VERSION "created by canmatrix"

NS_ :

BS_:

BU_: HC IDC_L3 RRR SRR_L SRR_R GW RSDS_R CR_R FR FR_IDC_L2 IFC IDC_L2 ADAS HAP CR_L RSDS_L IDC15_IDC_L2_ADC15H_ADC30L ADC15H_ADC30L_ADC30_ADC40 Tester CEM

BO_ 395 AEB_FD1: 64 IFC
 SG_ AEB_TgtDecel_ReqValue : 87|16@0+ (0.000488,-16) [-16|16] "m/s2"  CR_L,CR_R
 SG_ AEB_TgtDecel_Req : 74|1@0+ (1,0) [0|1] ""  CR_L,CR_R

BO_ 147 TMCU6: 8 GW
 SG_ TMCU_ActPosRotSpd : 15|16@0+ (1,0) [0|65534] "rpm"  CR_L,CR_R,RSDS_L,RSDS_R

BO_ 303 HCU_FD3: 64 GW
 SG_ HCU_GearSts : 164|4@0+ (1,0) [0|15] ""  CR_L,CR_R,RSDS_L,RSDS_R

BO_ 350 CR_FD1: 64 CR_R
 SG_ Checksum_CR_R_1 : 71|8@0+ (1,0) [0|255] "" Vector__XXX
 SG_ CR_FCTA_Resp : 79|1@0+ (1,0) [0|1] ""  GW
 SG_ CR_FCTB_Resp : 78|1@0+ (1,0) [0|1] ""  GW
 SG_ CR_ErrSts : 87|1@0+ (1,0) [0|1] ""  FR,ADAS
 SG_ CR_BliSts : 86|1@0+ (1,0) [0|1] ""  GW
 SG_ FCTB_ABA_Level : 82|2@0+ (1,0) [0|3] ""  FR,ADAS
 SG_ FCTB_ABA_Req : 80|1@0+ (1,0) [0|1] ""  FR,ADAS
 SG_ FCTB_ABP_Req : 111|1@0+ (1,0) [0|1] ""  FR,ADAS
 SG_ FCTA_Warn : 75|1@0+ (1,0) [0|1] ""  GW
 SG_ FCTBTrig : 83|1@0+ (1,0) [0|1] ""  GW
 SG_ FCTA_B_FuncSts : 77|2@0+ (1,0) [0|3] ""  GW
 SG_ CR_BrkgReqVal : 95|16@0+ (0.000488,-16) [-16|16] "m/s2"  FR,ADAS
 SG_ CR_BrkgReq : 85|1@0+ (1,0) [0|1] ""  FR,ADAS
 SG_ FCTA_B_TTC : 110|6@0+ (0.1,0) [0|6.3] "s"  GW
 SG_ RollingCounter_CR_R_1 : 123|4@0+ (1,0) [0|15] "" Vector__XXX
 SG_ Checksum_CR_R_2 : 135|8@0+ (1,0) [0|255] ""  IFC
 SG_ CR_ObjSts_Le : 179|2@0+ (1,0) [0|3] ""  IFC
 SG_ CR_ObjID_Le : 157|6@0+ (1,0) [0|63] ""  IFC
 SG_ CR_ObjDistX_Le : 151|10@0+ (0.1,-10) [-10|92.3] "m"  IFC
 SG_ CR_ObjDistY_Le : 143|8@0+ (0.1,-12.8) [-12.8|12.7] "m"  IFC
 SG_ CR_ObjRelVelX_Le : 167|10@0+ (0.1,-60) [-60|42.3] "m/s"  IFC
 SG_ CR_ObjRelAccelX_Le : 173|10@0+ (0.03125,-16) [-16|15.9688] "m/s2"  IFC
 SG_ CR_ObjMotionType_Le : 191|3@0+ (1,0) [0|7] ""  IFC
 SG_ RollingCounter_CR_R_2 : 187|4@0+ (1,0) [0|15] ""  IFC
 SG_ Checksum_CR_R_3 : 199|8@0+ (1,0) [0|255] ""  IFC
 SG_ CR_ObjSts_Ri : 243|2@0+ (1,0) [0|3] ""  IFC
 SG_ CR_ObjID_Ri : 221|6@0+ (1,0) [0|63] ""  IFC
 SG_ CR_ObjDistX_Ri : 215|10@0+ (0.1,-10) [-10|92.3] "m"  IFC
 SG_ CR_ObjDistY_Ri : 207|8@0+ (0.1,-12.8) [-12.8|12.7] "m"  IFC
 SG_ CR_ObjRelVelX_Ri : 231|10@0+ (0.1,-60) [-60|42.3] "m/s"  IFC
 SG_ CR_ObjRelAccelX_Ri : 237|10@0+ (0.03125,-16) [-16|15.9688] "m/s2"  IFC
 SG_ CR_ObjMotionType_Ri : 255|3@0+ (1,0) [0|7] ""  IFC
 SG_ RollingCounter_CR_R_3 : 251|4@0+ (1,0) [0|15] ""  IFC
 SG_ Checksum_CR_R_4 : 263|8@0+ (1,0) [0|255] ""  IFC
 SG_ CR_ObjRelAccelY_Ri : 271|10@0+ (0.03125,-16) [-16|15.9688] "m/s2"  IFC
 SG_ CR_ObjRelVelY_Ri : 295|7@0+ (0.1,-6.4) [-6.4|6.3] "m/s"  IFC
 SG_ CR_ObjRelAccelY_Le : 277|10@0+ (0.03125,-16) [-16|15.9688] "m/s2"  IFC
 SG_ CR_ObjRelVelY_Le : 303|7@0+ (0.1,-6.4) [-6.4|6.3] "m/s"  IFC
 SG_ RollingCounter_CR_R_4 : 315|4@0+ (1,0) [0|15] ""  IFC
 SG_ CR_ObjDistXStd_Le : 335|5@0+ (0.375,0) [0|11.625] "m"  IFC,IDC_L2
 SG_ CR_ObjDistYStd_Le : 330|5@0+ (0.375,0) [0|11.625] "m"  IFC,IDC_L2
 SG_ CR_ObjRelVelXStd_Le : 341|5@0+ (0.375,0) [0|11.625] "mps"  IFC,IDC_L2
 SG_ CR_ObjRelVelYStd_Le : 336|5@0+ (0.375,0) [0|11.625] "mps"  IFC,IDC_L2
 SG_ CR_ObjRAccelXStd_Le : 347|5@0+ (0.375,0) [0|11.625] "mps2"  IFC,IDC_L2
 SG_ CR_ObjRAccelYStd_Le : 358|5@0+ (0.375,0) [0|11.625] "mps2"  IFC,IDC_L2
 SG_ CR_ObjDistXStd_Ri : 353|5@0+ (0.375,0) [0|11.625] "m"  IFC,IDC_L2
 SG_ CR_ObjDistYStd_Ri : 364|5@0+ (0.375,0) [0|11.625] "m"  IFC,IDC_L2
 SG_ CR_ObjRelVelXStd_Ri : 375|5@0+ (0.375,0) [0|11.625] "mps"  IFC,IDC_L2
 SG_ CR_ObjRelVelYStd_Ri : 399|5@0+ (0.375,0) [0|11.625] "mps"  IFC,IDC_L2
 SG_ CR_ObjRAccelXStd_Ri : 394|5@0+ (0.375,0) [0|11.625] "mps2"  IFC,IDC_L2
 SG_ CR_ObjRAccelYStd_Ri : 405|5@0+ (0.375,0) [0|11.625] "mps2"  IFC,IDC_L2

BO_ 846 ACC_FD5: 16 FR
 SG_ Sync_CRC : 15|8@0+ (1,0) [0|255] ""  CR_L,CR_R
 SG_ Sync_OVS : 25|2@0+ (1,0) [0|3] ""  CR_L,CR_R
 SG_ Sync_Resd : 31|5@0+ (1,0) [0|31] ""  CR_L,CR_R
 SG_ Sync_Counter : 19|4@0+ (1,0) [0|15] ""  CR_L,CR_R
 SG_ Sync_SGW : 26|1@0+ (1,0) [0|1] ""  CR_L,CR_R
 SG_ Sync_SyncTime : 39|32@0+ (1,0) [0|4294967295] ""  CR_L,CR_R
 SG_ Sync_TimeDomain : 23|4@0+ (1,0) [0|15] ""  CR_L,CR_R
 SG_ Sync_Type : 7|8@0+ (1,0) [0|255] ""  CR_L,CR_R

BO_ 323 ACC_FD1: 64 FR_IDC_L2
 SG_ ACC_CRInterface : 191|1@0+ (1,0) [0|1] ""  CR_L,CR_R

BO_ 121 ECM_FD1: 64 GW
 SG_ BrkPedalSts_0x079 : 275|2@0+ (1,0) [0|3] ""  RSDS_R,RSDS_L,CR_L,CR_R
 SG_ EngSpd_0x079 : 303|16@0+ (0.125,0) [0|8191.875] "rpm"  RSDS_R,RSDS_L,CR_L,CR_R
 SG_ EngSpdVldty_0x079 : 319|2@0+ (1,0) [0|2] ""  RSDS_R,RSDS_L,CR_L,CR_R

BO_ 259 ECM_FD2: 64 GW
 SG_ AccelPedlPosnDiagc_0x103 : 103|8@0+ (0.3937,0) [0|100.3935] "%"  RSDS_R,RSDS_L,CR_L,CR_R
 SG_ AccelPedalPosnVldty_0x103 : 242|2@0+ (1,0) [0|2] ""  RSDS_R,RSDS_L,CR_L,CR_R
 SG_ EngState_0x103 : 254|2@0+ (1,0) [0|3] ""  RSDS_R,RSDS_L,CR_L,CR_R
 SG_ EngState_PHEV_0x103 : 351|3@0+ (1,0) [0|7] ""  RSDS_R,RSDS_L,CR_L,CR_R

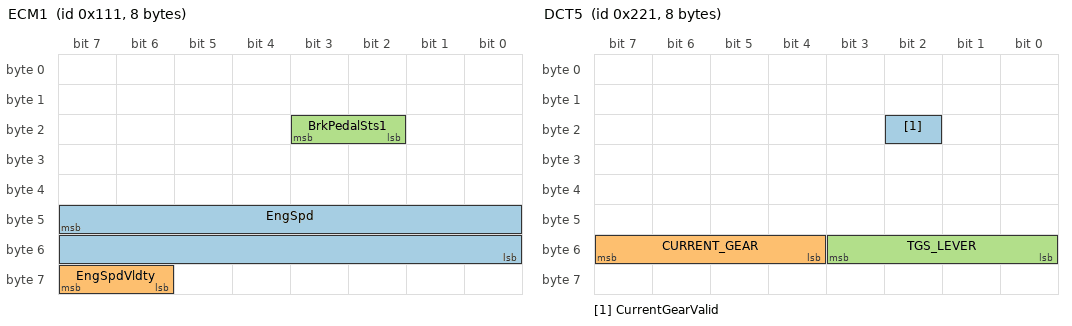
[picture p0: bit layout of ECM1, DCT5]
BO_ 273 ECM1: 8 GW
 SG_ EngSpd : 47|16@0+ (0.125,0) [0|8191.875] "rpm"  RSDS_R,RSDS_L,CR_L,CR_R
 SG_ EngSpdVldty : 63|2@0+ (1,0) [0|2] ""  RSDS_R,RSDS_L,CR_L,CR_R
 SG_ BrkPedalSts1 : 19|2@0+ (1,0) [0|3] ""  RSDS_R,RSDS_L,CR_L,CR_R

BO_ 545 DCT5: 8 GW
 SG_ CurrentGearValid : 18|1@0+ (1,0) [0|1] ""  RSDS_R,RSDS_L,CR_L,CR_R
 SG_ CURRENT_GEAR : 55|4@0+ (1,0) [0|15] ""  RSDS_R,RSDS_L,CR_L,CR_R
 SG_ TGS_LEVER : 51|4@0+ (1,0) [0|15] ""  RSDS_R,RSDS_L,CR_L,CR_R

BO_ 311 ESP_FD2: 64 GW
 SG_ ESP_DiagActv_0x137 : 73|1@0+ (1,0) [0|1] ""  RSDS_R,RSDS_L,CR_L,CR_R
 SG_ BrkDskOvrheatd_0x137 : 75|1@0+ (1,0) [0|1] ""  CR_L,CR_R
 SG_ NoBrkForce_0x137 : 76|1@0+ (1,0) [0|1] ""  RSDS_R,RSDS_L,CR_L,CR_R
 SG_ VehStandstill_0x137 : 78|2@0+ (1,0) [0|3] ""  RSDS_R,RSDS_L,CR_L,CR_R
 SG_ AEBIBActv_0x137 : 81|1@0+ (1,0) [0|1] ""  RSDS_R,RSDS_L,CR_L,CR_R
 SG_ AEBBAActv_0x137 : 82|1@0+ (1,0) [0|1] ""  RSDS_R,RSDS_L,CR_L,CR_R
 SG_ AEBAvailable_0x137 : 83|1@0+ (1,0) [0|1] ""  CR_L,CR_R
 SG_ ABPAvailable_0x137 : 84|1@0+ (1,0) [0|1] ""  CR_L,CR_R
 SG_ ABPActv_0x137 : 85|1@0+ (1,0) [0|1] ""  CR_L,CR_R
 SG_ ABAavailable_0x137 : 86|1@0+ (1,0) [0|1] ""  CR_L,CR_R
 SG_ ABAactv_0x137 : 87|1@0+ (1,0) [0|1] ""  CR_L,CR_R
 SG_ HDCCtrl_0x137 : 91|2@0+ (1,0) [0|2] ""  RSDS_R,RSDS_L,CR_L,CR_R
 SG_ CTABrkAvailable_0x137 : 74|1@0+ (1,0) [0|1] ""  RSDS_R,RSDS_L
 SG_ CheckSum_ESP1_0x137 : 135|8@0+ (1,0) [0|255] ""  RSDS_R,RSDS_L,CR_L,CR_R
 SG_ ESPFuncOffSts_0x137 : 140|1@0+ (1,0) [0|1] ""  RSDS_R,RSDS_L,CR_L,CR_R
 SG_ ESPFailSts_0x137 : 143|1@0+ (1,0) [0|1] ""  RSDS_R,RSDS_L,CR_L,CR_R
 SG_ ESP_MasterCylBrkPressVld_0x137 : 144|1@0+ (1,0) [0|1] ""  RSDS_R,RSDS_L,CR_L,CR_R
 SG_ MSRActv_0x137 : 149|1@0+ (1,0) [0|1] ""  RSDS_R,RSDS_L,CR_L,CR_R
 SG_ VDCActv_0x137 : 148|1@0+ (1,0) [0|1] ""  RSDS_R,RSDS_L,CR_L,CR_R
 SG_ PTCActv_0x137 : 150|1@0+ (1,0) [0|1] ""  RSDS_R,RSDS_L,CR_L,CR_R
 SG_ BTCActv_0x137 : 151|1@0+ (1,0) [0|1] ""  RSDS_R,RSDS_L,CR_L,CR_R
 SG_ ESP_MasterCylBrkPress_0x137 : 159|16@0+ (0.03125,-42.5) [-42.5|425] "bar"  RSDS_R,RSDS_L,CR_L,CR_R
 SG_ MSRActv_RA_0x137 : 174|1@0+ (1,0) [0|1] ""  RSDS_R,RSDS_L,CR_L,CR_R
 SG_ PTCActv_RA_0x137 : 136|1@0+ (1,0) [0|1] ""  RSDS_R,RSDS_L,CR_L,CR_R
 SG_ BTCActv_RA_0x137 : 137|1@0+ (1,0) [0|1] ""  RSDS_R,RSDS_L,CR_L,CR_R
 SG_ RollingCounter_ESP1_0x137 : 187|4@0+ (1,0) [0|15] ""  RSDS_R,RSDS_L,CR_L,CR_R
 SG_ CheckSum_ABS3_0x137 : 327|8@0+ (1,0) [0|255] ""  RSDS_R,RSDS_L,CR_L,CR_R
 SG_ VehSpdVld_0x137 : 333|1@0+ (1,0) [0|1] ""  RSDS_R,RSDS_L,CR_L,CR_R
 SG_ VehSpd_0x137 : 332|13@0+ (0.05625,0) [0|299.98125] "kph"  RSDS_R,RSDS_L,CR_L,CR_R
 SG_ ABSActv_0x137 : 347|1@0+ (1,0) [0|1] ""  RSDS_R,RSDS_L,CR_L,CR_R
 SG_ RollingCounter_ABS3_0x137 : 379|4@0+ (1,0) [0|15] ""  RSDS_R,RSDS_L,CR_L,CR_R

BO_ 315 ESP_FD3: 64 GW
 SG_ CheckSum_ABS1_0x13B : 7|8@0+ (1,0) [0|255] ""  RSDS_R,RSDS_L,CR_L,CR_R
 SG_ FLWheelDriveDirection_0x13B : 15|2@0+ (1,0) [0|3] ""  RSDS_R,RSDS_L,CR_L,CR_R
 SG_ FLWheelSpdVld_0x13B : 13|1@0+ (1,0) [0|1] ""  RSDS_R,RSDS_L,CR_L,CR_R
 SG_ FLWheelSpd_0x13B : 12|13@0+ (0.05625,0) [0|299.98125] "km/h"  RSDS_R,RSDS_L,CR_L,CR_R
 SG_ FRWheelDriveDirection_0x13B : 31|2@0+ (1,0) [0|3] ""  RSDS_R,RSDS_L,CR_L,CR_R
 SG_ FRWheelSpdVld_0x13B : 29|1@0+ (1,0) [0|1] ""  RSDS_R,RSDS_L,CR_L,CR_R
 SG_ FRWheelSpd_0x13B : 28|13@0+ (0.05625,0) [0|299.98125] "km/h"  RSDS_R,RSDS_L,CR_L,CR_R
 SG_ RollingCounter_ABS1_0x13B : 59|4@0+ (1,0) [0|15] ""  RSDS_R,RSDS_L,CR_L,CR_R
 SG_ EPBErrSts_0x13B : 91|2@0+ (1,0) [0|3] ""  RSDS_R,RSDS_L,CR_L,CR_R
 SG_ EPBSts_0x13B : 93|2@0+ (1,0) [0|3] ""  RSDS_R,RSDS_L,CR_L,CR_R
 SG_ CheckSum_ABS2_0x13B : 327|8@0+ (1,0) [0|255] ""  RSDS_R,RSDS_L,CR_L,CR_R
 SG_ RLWheelDriveDirection_0x13B : 335|2@0+ (1,0) [0|3] ""  RSDS_R,RSDS_L,CR_L,CR_R
 SG_ RLWheelSpdVld_0x13B : 333|1@0+ (1,0) [0|1] ""  RSDS_R,RSDS_L,CR_L,CR_R
 SG_ RLWheelSpd_0x13B : 332|13@0+ (0.05625,0) [0|299.98125] "km/h"  RSDS_R,RSDS_L,CR_L,CR_R
 SG_ RRWheelDriveDirection_0x13B : 351|2@0+ (1,0) [0|3] ""  RSDS_R,RSDS_L,CR_L,CR_R
 SG_ RRWheelSpdVld_0x13B : 349|1@0+ (1,0) [0|1] ""  RSDS_R,RSDS_L,CR_L,CR_R
 SG_ RRWheelSpd_0x13B : 348|13@0+ (0.05625,0) [0|299.98125] "km/h"  RSDS_R,RSDS_L,CR_L,CR_R
 SG_ RollingCounter_ABS2_0x13B : 379|4@0+ (1,0) [0|15] ""  RSDS_R,RSDS_L,CR_L,CR_R

BO_ 793 BCM1: 16 GW
 SG_ DrvDoorSts : 22|1@0+ (1,0) [0|1] ""  RSDS_R,RSDS_L,CR_L,CR_R
 SG_ LRDoorSts : 21|1@0+ (1,0) [0|1] ""  RSDS_R,RSDS_L
 SG_ PassengerDoorSts : 20|1@0+ (1,0) [0|1] ""  RSDS_R,RSDS_L
 SG_ RRDoorSts : 19|1@0+ (1,0) [0|1] ""  RSDS_R,RSDS_L

BO_ 671 BCM8: 8 GW
 SG_ RSDS_LLEDSts : 47|1@0+ (1,0) [0|1] ""  RSDS_R,RSDS_L
 SG_ RSDS_RLEDSts : 46|1@0+ (1,0) [0|1] ""  RSDS_R,RSDS_L

BO_ 661 PEPS2: 8 GW
 SG_ SysPowerMod : 15|2@0+ (1,0) [0|3] ""  RSDS_R,RSDS_L,CR_L,CR_R
 SG_ SysPowerModVld : 13|1@0+ (1,0) [0|1] ""  RSDS_R,RSDS_L,CR_L,CR_R

BO_ 627 Trailer1: 8 GW
 SG_ TrailerSts : 7|1@0+ (1,0) [0|1] ""  RSDS_R,RSDS_L

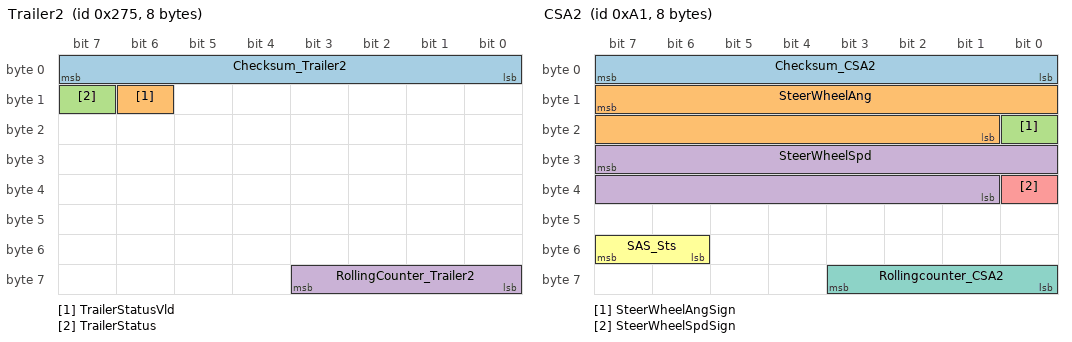
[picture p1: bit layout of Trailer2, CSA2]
BO_ 629 Trailer2: 8 GW
 SG_ Checksum_Trailer2 : 7|8@0+ (1,0) [0|255] "NoUnit"  RSDS_R,RSDS_L
 SG_ TrailerStatusVld : 14|1@0+ (1,0) [0|1] "NoUnit"  RSDS_R,RSDS_L
 SG_ TrailerStatus : 15|1@0+ (1,0) [0|1] "NoUnit"  RSDS_R,RSDS_L
 SG_ RollingCounter_Trailer2 : 59|4@0+ (1,0) [0|15] "NoUnit"  RSDS_R,RSDS_L

BO_ 357 CSA1: 8 GW
 SG_ LTurnLmpSwtSts : 19|1@0+ (1,0) [0|1] ""  RSDS_R,RSDS_L,CR_L,CR_R
 SG_ RTurnLmpSwtSts : 20|1@0+ (1,0) [0|1] ""  RSDS_R,RSDS_L,CR_L,CR_R

BO_ 161 CSA2: 8 GW
 SG_ Checksum_CSA2 : 7|8@0+ (1,0) [0|255] ""  RSDS_R,RSDS_L
 SG_ SteerWheelAng : 15|15@0+ (0.1,0) [0|780] "deg"  RSDS_R,RSDS_L,CR_L,CR_R
 SG_ SteerWheelAngSign : 16|1@0+ (1,0) [0|1] ""  RSDS_R,RSDS_L,CR_L,CR_R
 SG_ SteerWheelSpd : 31|15@0+ (0.1,0) [0|1016] "deg/s"  RSDS_R,RSDS_L,CR_L,CR_R
 SG_ SteerWheelSpdSign : 32|1@0+ (1,0) [0|1] ""  RSDS_R,RSDS_L,CR_L,CR_R
 SG_ SAS_Sts : 55|2@0+ (1,0) [0|3] ""  RSDS_R,RSDS_L,CR_L,CR_R
 SG_ Rollingcounter_CSA2 : 59|4@0+ (1,0) [0|15] ""  RSDS_R,RSDS_L

BO_ 714 DDCM1: 8 GW
 SG_ RSDS_Driver_LED_Sts : 9|1@0+ (1,0) [0|1] ""  RSDS_R,RSDS_L

BO_ 717 PDCM1: 8 GW
 SG_ RSDS_Pass_LED_Sts : 8|1@0+ (1,0) [0|1] ""  RSDS_R,RSDS_L

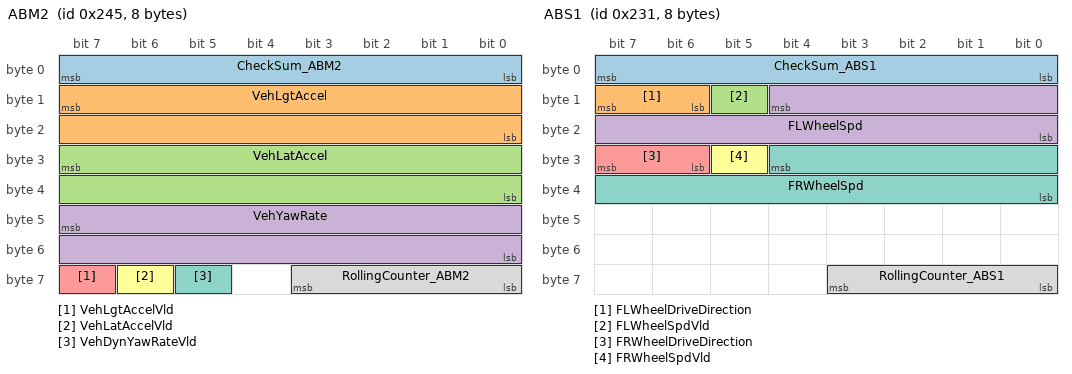
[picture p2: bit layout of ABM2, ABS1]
BO_ 581 ABM2: 8 GW
 SG_ CheckSum_ABM2 : 7|8@0+ (1,0) [0|255] ""  RSDS_R,RSDS_L,CR_L,CR_R
 SG_ VehLgtAccel : 15|16@0+ (0.00098,-21.592) [-21.592|21.592] "m/s^2"  RSDS_R,RSDS_L,CR_L,CR_R
 SG_ VehLatAccel : 31|16@0+ (0.00098,-21.592) [-21.592|21.592] "m/s^2"  RSDS_R,RSDS_L,CR_L,CR_R
 SG_ VehYawRate : 47|16@0+ (0.00024,-2.093) [-2.093|2.093] "rad/s"  RSDS_R,RSDS_L,CR_L,CR_R
 SG_ VehLgtAccelVld : 63|1@0+ (1,0) [0|1] ""  RSDS_R,RSDS_L,CR_L,CR_R
 SG_ VehLatAccelVld : 62|1@0+ (1,0) [0|1] ""  RSDS_R,RSDS_L,CR_L,CR_R
 SG_ VehDynYawRateVld : 61|1@0+ (1,0) [0|1] ""  RSDS_R,RSDS_L,CR_L,CR_R
 SG_ RollingCounter_ABM2 : 59|4@0+ (1,0) [0|15] ""  RSDS_R,RSDS_L,CR_L,CR_R

BO_ 639 IP2: 16 GW
 SG_ IP_VehTotDistance : 15|24@0+ (0.1,0) [0|999999.9] "Km"  RSDS_R,RSDS_L,CR_L,CR_R
 SG_ IP_VehTotDistanceValid : 46|1@0+ (1,0) [0|1] ""  RSDS_R,RSDS_L,CR_L,CR_R

BO_ 707 HUT_FD1: 64 GW
 SG_ DOWSwtReq : 104|1@0+ (1,0) [0|1] ""  RSDS_R,RSDS_L
 SG_ LCASwtReq : 85|1@0+ (1,0) [0|1] ""  RSDS_R,RSDS_L
 SG_ RCTASwtReq : 84|1@0+ (1,0) [0|1] ""  RSDS_R,RSDS_L
 SG_ RCTABrkSwtReq : 83|1@0+ (1,0) [0|1] ""  RSDS_R,RSDS_L
 SG_ RCWSwtReq : 82|1@0+ (1,0) [0|1] ""  RSDS_R,RSDS_L
 SG_ FCW_SnvtySet : 81|2@0+ (1,0) [0|3] ""  CR_L,CR_R
 SG_ FCTASwtReq : 301|1@0+ (1,0) [0|1] ""  CR_L,CR_R
 SG_ FCTABrkSwtReq : 300|1@0+ (1,0) [0|1] ""  CR_L,CR_R

BO_ 258 ECM9: 8 GW
 SG_ AccelPedlPosnDiagc : 39|8@0+ (0.3937,0) [0|100.3935] "%"  RSDS_R,RSDS_L,CR_L,CR_R

BO_ 625 ECM2: 8 GW
 SG_ AccelPedalPosnVldty : 50|2@0+ (1,0) [0|2] ""  RSDS_R,RSDS_L,CR_L,CR_R
 SG_ EngState : 62|2@0+ (1,0) [0|3] ""  RSDS_R,RSDS_L,CR_L,CR_R

BO_ 561 ABS1: 8 GW
 SG_ CheckSum_ABS1 : 7|8@0+ (1,0) [0|255] ""  RSDS_R,RSDS_L,CR_L,CR_R
 SG_ FLWheelDriveDirection : 15|2@0+ (1,0) [0|3] ""  RSDS_R,RSDS_L,CR_L,CR_R
 SG_ FLWheelSpdVld : 13|1@0+ (1,0) [0|1] ""  RSDS_R,RSDS_L,CR_L,CR_R
 SG_ FLWheelSpd : 12|13@0+ (0.05625,0) [0|299.98125] "km/h"  RSDS_R,RSDS_L,CR_L,CR_R
 SG_ FRWheelDriveDirection : 31|2@0+ (1,0) [0|3] ""  RSDS_R,RSDS_L,CR_L,CR_R
 SG_ FRWheelSpdVld : 29|1@0+ (1,0) [0|1] ""  RSDS_R,RSDS_L,CR_L,CR_R
 SG_ FRWheelSpd : 28|13@0+ (0.05625,0) [0|299.98125] "km/h"  RSDS_R,RSDS_L,CR_L,CR_R
 SG_ RollingCounter_ABS1 : 59|4@0+ (1,0) [0|15] ""  RSDS_R,RSDS_L,CR_L,CR_R

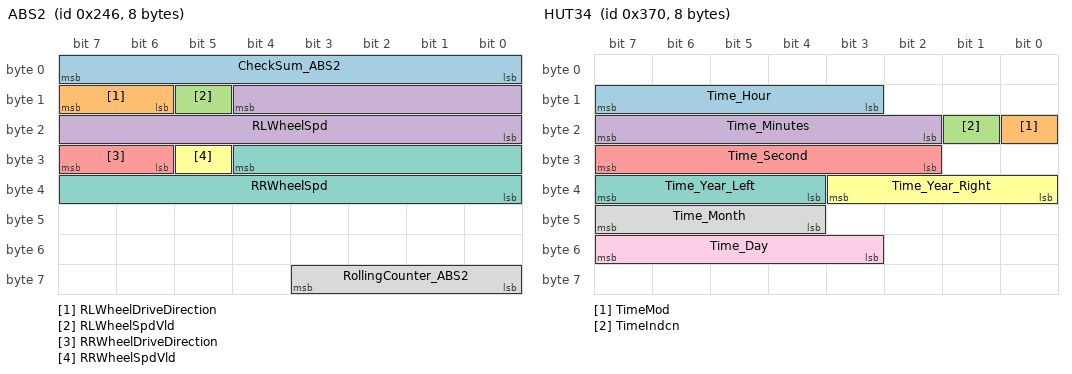
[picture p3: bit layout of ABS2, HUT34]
BO_ 582 ABS2: 8 GW
 SG_ CheckSum_ABS2 : 7|8@0+ (1,0) [0|255] ""  RSDS_R,RSDS_L,CR_L,CR_R
 SG_ RLWheelDriveDirection : 15|2@0+ (1,0) [0|3] ""  RSDS_R,RSDS_L,CR_L,CR_R
 SG_ RLWheelSpdVld : 13|1@0+ (1,0) [0|1] ""  RSDS_R,RSDS_L,CR_L,CR_R
 SG_ RLWheelSpd : 12|13@0+ (0.05625,0) [0|299.98125] "km/h"  RSDS_R,RSDS_L,CR_L,CR_R
 SG_ RRWheelDriveDirection : 31|2@0+ (1,0) [0|3] ""  RSDS_R,RSDS_L,CR_L,CR_R
 SG_ RRWheelSpdVld : 29|1@0+ (1,0) [0|1] ""  RSDS_R,RSDS_L,CR_L,CR_R
 SG_ RRWheelSpd : 28|13@0+ (0.05625,0) [0|299.98125] "km/h"  RSDS_R,RSDS_L,CR_L,CR_R
 SG_ RollingCounter_ABS2 : 59|4@0+ (1,0) [0|15] ""  RSDS_R,RSDS_L,CR_L,CR_R

BO_ 613 ABS3: 16 GW
 SG_ CheckSum_ABS3 : 7|8@0+ (1,0) [0|255] ""  RSDS_R,RSDS_L,CR_L,CR_R
 SG_ VehSpdVld : 13|1@0+ (1,0) [0|1] ""  RSDS_R,RSDS_L,CR_L,CR_R
 SG_ VehSpd : 12|13@0+ (0.05625,0) [0|299.98125] "kph"  RSDS_R,RSDS_L,CR_L,CR_R
 SG_ ABSActv : 27|1@0+ (1,0) [0|1] ""  RSDS_R,RSDS_L,CR_L,CR_R
 SG_ RollingCounter_ABS3 : 59|4@0+ (1,0) [0|15] ""  RSDS_R,RSDS_L,CR_L,CR_R

BO_ 363 EPB1: 8 GW
 SG_ EPBErrSts : 27|2@0+ (1,0) [0|3] ""  RSDS_R,RSDS_L,CR_L,CR_R
 SG_ EPBSts : 29|2@0+ (1,0) [0|3] ""  RSDS_R,RSDS_L,CR_L,CR_R

BO_ 329 ESP1: 16 GW
 SG_ CheckSum_ESP1 : 7|8@0+ (1,0) [0|255] ""  RSDS_R,RSDS_L,CR_L,CR_R
 SG_ ESPFuncOffSts : 12|1@0+ (1,0) [0|1] ""  RSDS_R,RSDS_L,CR_L,CR_R
 SG_ ESPFailSts : 15|1@0+ (1,0) [0|1] ""  RSDS_R,RSDS_L,CR_L,CR_R
 SG_ ESP_MasterCylBrkPressVld : 16|1@0+ (1,0) [0|1] ""  RSDS_R,RSDS_L,CR_L,CR_R
 SG_ MSRActv : 21|1@0+ (1,0) [0|1] ""  RSDS_R,RSDS_L,CR_L,CR_R
 SG_ VDCActv : 20|1@0+ (1,0) [0|1] ""  RSDS_R,RSDS_L,CR_L,CR_R
 SG_ PTCActv : 22|1@0+ (1,0) [0|1] ""  RSDS_R,RSDS_L,CR_L,CR_R
 SG_ BTCActv : 23|1@0+ (1,0) [0|1] ""  RSDS_R,RSDS_L,CR_L,CR_R
 SG_ ESP_MasterCylBrkPress : 31|16@0+ (0.03125,-42.5) [-42.5|425] "bar"  RSDS_R,RSDS_L,CR_L,CR_R
 SG_ RollingCounter_ESP1 : 59|4@0+ (1,0) [0|15] ""  RSDS_R,RSDS_L,CR_L,CR_R

BO_ 325 ESP2: 16 GW
 SG_ ESP_DiagActv : 9|1@0+ (1,0) [0|1] ""  RSDS_R,RSDS_L,CR_L,CR_R
 SG_ NoBrkForce : 12|1@0+ (1,0) [0|1] ""  RSDS_R,RSDS_L,CR_L,CR_R
 SG_ VehStandstill : 14|2@0+ (1,0) [0|3] ""  RSDS_R,RSDS_L,CR_L,CR_R
 SG_ AEBIBActv : 17|1@0+ (1,0) [0|1] ""  RSDS_R,RSDS_L,CR_L,CR_R
 SG_ AEBBAActv : 18|1@0+ (1,0) [0|1] ""  RSDS_R,RSDS_L,CR_L,CR_R
 SG_ HDCCtrl : 27|2@0+ (1,0) [0|2] ""  RSDS_R,RSDS_L,CR_L,CR_R
 SG_ CTABrkAvailable : 10|1@0+ (1,0) [0|1] ""  RSDS_R,RSDS_L
 SG_ BrkDskOvrheatd : 11|1@0+ (1,0) [0|1] ""  CR_L,CR_R
 SG_ AEBAvailable : 19|1@0+ (1,0) [0|1] ""  CR_L,CR_R
 SG_ ABPAvailable : 20|1@0+ (1,0) [0|1] ""  CR_L,CR_R
 SG_ ABPActv : 21|1@0+ (1,0) [0|1] ""  CR_L,CR_R
 SG_ ABAavailable : 22|1@0+ (1,0) [0|1] ""  CR_L,CR_R
 SG_ ABAactv : 23|1@0+ (1,0) [0|1] ""  CR_L,CR_R

BO_ 96 HCU_FD1: 64 GW
 SG_ HCU_BrkPedalSts : 87|2@0+ (1,0) [0|3] ""  RSDS_R,RSDS_L,CR_L,CR_R
 SG_ HCU_BrkPedalStsValid : 84|1@0+ (1,0) [0|1] ""  RSDS_R,RSDS_L,CR_L,CR_R
 SG_ HCU_AccelPedalPosn_Diag : 79|8@0+ (0.3937,0) [0|100.395] "%"  RSDS_R,RSDS_L,CR_L,CR_R
 SG_ HCU_AccelPedalPosn_DiagValid : 85|1@0+ (1,0) [0|1] ""  RSDS_R,RSDS_L,CR_L,CR_R
 SG_ HCU_PowertrainSts : 303|5@0+ (1,0) [0|31] ""  RSDS_R,RSDS_L,CR_L,CR_R

BO_ 288 Ibooster_FD2: 64 GW
 SG_ IB_BrkPedalAppld : 11|1@0+ (1,0) [0|1] ""  RSDS_R,RSDS_L,CR_L,CR_R
 SG_ IB_BrkPedalAppldVld : 10|2@0+ (1,0) [0|3] ""  RSDS_R,RSDS_L,CR_L,CR_R

BO_ 174 MCU_FD1: 64 GW
 SG_ MCU_ActRotSpd : 167|16@0+ (1,-20000) [-20000|45534] "rpm"  RSDS_R,RSDS_L,CR_L,CR_R

BO_ 537 VCU_FD3: 64 GW
 SG_ VCU_GearSts : 87|4@0+ (1,0) [0|15] ""  RSDS_R,RSDS_L,CR_L,CR_R
 SG_ VCU_GearStsVld : 94|1@0+ (1,0) [0|1] ""  RSDS_R,RSDS_L,CR_L,CR_R

BO_ 1305 HC_NM: 8 HC
 SG_ Destination_HC_NM : 7|8@0+ (1,0) [0|63] ""  GW,IDC_L3
 SG_ OpCode_HC_NM : 15|8@0+ (1,0) [0|63] ""  GW,IDC_L3

BO_ 1308 IDC_L3_NM: 8 IDC_L3
 SG_ Destination_IDC_L3_NM : 7|8@0+ (1,0) [0|63] ""  GW,HC,RRR,SRR_L,SRR_R
 SG_ OpCode_IDC_L3_NM : 15|8@0+ (1,0) [0|63] ""  GW,HC,RRR,SRR_L,SRR_R

BO_ 1309 RRR_NM: 8 RRR
 SG_ Destination_RRR_NM : 7|8@0+ (1,0) [0|63] ""  IDC_L3
 SG_ OpCode_RRR_NM : 15|8@0+ (1,0) [0|63] ""  IDC_L3

BO_ 1310 SRR_L_NM: 8 SRR_L
 SG_ Destination_SRR_L_NM : 7|8@0+ (1,0) [0|63] ""  IDC_L3,SRR_R
 SG_ OpCode_SRR_L_NM : 15|8@0+ (1,0) [0|63] ""  IDC_L3,SRR_R

BO_ 1311 SRR_R_NM: 8 SRR_R
 SG_ Destination_SRR_R_NM : 7|8@0+ (1,0) [0|63] ""  IDC_L3,SRR_L
 SG_ OpCode_SRR_R_NM : 15|8@0+ (1,0) [0|63] ""  IDC_L3,SRR_L

BO_ 1281 GW_NM: 8 GW
 SG_ Destination_GW_NM : 7|8@0+ (1,0) [0|63] ""  HC,IDC_L3
 SG_ OpCode_GW_NM : 15|8@0+ (1,0) [0|63] ""  HC,IDC_L3

BO_ 301 EBOOSTER_FD1: 64 GW
 SG_ EB_AEBIBActv : 13|1@0+ (1,0) [0|1] ""  CR_L,CR_R,RSDS_R,RSDS_L
 SG_ EB_AEBBAActv : 12|1@0+ (1,0) [0|1] ""  CR_L,CR_R,RSDS_R,RSDS_L
 SG_ EB_AEBAvailable : 11|1@0+ (1,0) [0|1] ""  CR_L,CR_R,RSDS_R,RSDS_L
 SG_ EB_ABPAvailable : 10|1@0+ (1,0) [0|1] ""  CR_L,CR_R
 SG_ EB_ABPActv : 9|1@0+ (1,0) [0|1] ""  CR_L,CR_R
 SG_ EB_CTABrkAvailable : 17|1@0+ (1,0) [0|1] ""  RSDS_R,RSDS_L

BO_ 1136 ADAS_AD1: 16 GW
 SG_ Sync_CRC_0x470 : 15|8@0+ (1,0) [0|255] ""  FR,CR_L,CR_R,RSDS_R,RSDS_L
 SG_ Sync_OVS_0x470 : 25|2@0+ (1,0) [0|3] ""  FR,CR_L,CR_R,RSDS_R,RSDS_L
 SG_ Sync_Resd_0x470 : 31|5@0+ (1,0) [0|31] ""  FR,CR_L,CR_R,RSDS_R,RSDS_L
 SG_ Sync_Counter_0x470 : 19|4@0+ (1,0) [0|15] ""  FR,CR_L,CR_R,RSDS_R,RSDS_L
 SG_ Sync_SGW_0x470 : 26|1@0+ (1,0) [0|1] ""  FR,CR_L,CR_R,RSDS_R,RSDS_L
 SG_ Sync_SyncTime_0x470 : 39|32@0+ (1,0) [0|4294967295] ""  FR,CR_L,CR_R,RSDS_R,RSDS_L
 SG_ Sync_TimeDomain_0x470 : 23|4@0+ (1,0) [0|15] ""  FR,CR_L,CR_R,RSDS_R,RSDS_L
 SG_ Sync_Type_0x470 : 7|8@0+ (1,0) [0|255] ""  FR,CR_L,CR_R,RSDS_R,RSDS_L

BO_ 778 RSDS_FD2: 64 RSDS_R
 SG_ RCTA_B_TTC : 15|6@0+ (0.1,0) [0|6.3] "s" Vector__XXX
 SG_ BSD_LCA_Left_TTC : 9|6@0+ (0.1,0) [0|6.3] "s" Vector__XXX
 SG_ RCW_TTC : 29|6@0+ (0.1,0) [0|6.3] "s" Vector__XXX
 SG_ BSD_LCA_Right_TTC : 19|6@0+ (0.1,0) [0|6.3] "s" Vector__XXX
 SG_ RSDS_LeTgt_01_dy : 78|7@0+ (0.1,0) [0|8] "m" Vector__XXX
 SG_ RSDS_LeTgt_01 : 79|1@0+ (1,0) [0|1] "NoUnit" Vector__XXX
 SG_ RSDS_LeTgt_02 : 93|1@0+ (1,0) [0|1] "NoUnit" Vector__XXX
 SG_ RSDS_LeTgt_01_dx : 87|10@0+ (0.1,-90) [-90|5] "m" Vector__XXX
 SG_ RSDS_LeTgt_02_dx : 92|10@0+ (0.1,-90) [-90|5] "m" Vector__XXX
 SG_ RSDS_RiTgt_01 : 107|1@0+ (1,0) [0|1] "NoUnit" Vector__XXX
 SG_ RSDS_LeTgt_02_dy : 98|7@0+ (0.1,0) [0|8] "m" Vector__XXX
 SG_ RSDS_RiTgt_01_dx : 106|10@0+ (0.1,-90) [-90|5] "m" Vector__XXX
 SG_ RSDS_RiTgt_02 : 136|1@0+ (1,0) [0|1] "NoUnit" Vector__XXX
 SG_ RSDS_RiTgt_01_dy : 143|7@0+ (0.1,-8) [-8|0] "m" Vector__XXX
 SG_ RSDS_RiTgt_02_dx : 151|10@0+ (0.1,-90) [-90|5] "m" Vector__XXX
 SG_ RSDS_MidTgt_01 : 166|1@0+ (1,0) [0|1] "NoUnit" Vector__XXX
 SG_ RSDS_RiTgt_02_dy : 157|7@0+ (0.1,-8) [-8|0] "m" Vector__XXX
 SG_ RSDS_MidTgt_01_dx : 165|10@0+ (0.1,-90) [-90|5] "m" Vector__XXX
 SG_ RSDS_MidTgt_02 : 180|1@0+ (1,0) [0|1] "NoUnit" Vector__XXX
 SG_ RSDS_MidTgt_01_dy : 171|7@0+ (0.1,-4) [-4|4] "m" Vector__XXX
 SG_ RSDS_MidTgt_02_dx : 207|10@0+ (0.1,-90) [-90|5] "m" Vector__XXX
 SG_ RSDS_MidTgt_02_dy : 213|7@0+ (0.1,-4) [-4|4] "m" Vector__XXX
 SG_ LCA_LeTgt_01_Type : 126|3@0+ (1,0) [0|7] "NoUnit" Vector__XXX
 SG_ RCTA_LeTgt_02_Type : 179|3@0+ (1,0) [0|7] "NoUnit" Vector__XXX
 SG_ LCA_RiTgt_01_Type : 190|3@0+ (1,0) [0|7] "NoUnit" Vector__XXX
 SG_ RCTA_RiTgt_02_Type : 222|3@0+ (1,0) [0|7] "NoUnit" Vector__XXX
 SG_ RCW_MidTgt_01_Type : 219|3@0+ (1,0) [0|7] "NoUnit" Vector__XXX
 SG_ RCTB_MidTgt_02_Type : 292|3@0+ (1,0) [0|7] "NoUnit" Vector__XXX
 SG_ LCA_LeTgt_01_Vx : 216|9@0+ (0.5,-127.5) [-127|128] "kph" Vector__XXX
 SG_ RCTA_LeTgt_02_Vx : 239|9@0+ (0.5,-127.5) [-127|128] "kph" Vector__XXX
 SG_ LCA_RiTgt_01_Vx : 246|9@0+ (0.5,-127.5) [-127|128] "kph" Vector__XXX
 SG_ RCTA_RiTgt_02_Vx : 271|9@0+ (0.5,-127.5) [-127|128] "kph" Vector__XXX
 SG_ RCW_MidTgt_01_Vx : 278|9@0+ (0.5,-127.5) [-127|128] "kph" Vector__XXX
 SG_ RCTB_MidTgt_02_Vx : 285|9@0+ (0.5,-127.5) [-127|128] "kph" Vector__XXX
 SG_ LCA_LeTgt_01_Vy : 289|9@0+ (0.5,-127.5) [-127|128] "kph" Vector__XXX
 SG_ RCTA_LeTgt_02_Vy : 296|9@0+ (0.5,-127.5) [-127|128] "kph" Vector__XXX
 SG_ LCA_RiTgt_01_Vy : 335|9@0+ (0.5,-127.5) [-127|128] "kph" Vector__XXX
 SG_ RCTA_RiTgt_02_Vy : 342|9@0+ (0.5,-127.5) [-127|128] "kph" Vector__XXX
 SG_ RCW_MidTgt_01_Vy : 349|9@0+ (0.5,-127.5) [-127|128] "kph" Vector__XXX
 SG_ RCTB_MidTgt_02_Vy : 356|9@0+ (0.5,-127.5) [-127|128] "kph" Vector__XXX

BO_ 367 RSDS_FD1: 64 RSDS_R
 SG_ RSDS_ObjRelAccelY_Le : 15|10@0+ (0.03125,-16) [-16|15.9688] "MtrPerSecSq"  GW
 SG_ Checksum_RSDS_R_2 : 71|8@0+ (1,0) [0|255] "NoUnit"  GW
 SG_ RSDS_BrkgReq : 78|1@0+ (1,0) [0|1] "NoUnit"  GW
 SG_ RSDS_Brk_ErrSts : 79|1@0+ (1,0) [0|1] "NoUnit"  GW
 SG_ RSDS_IPSoundReq : 81|2@0+ (1,0) [0|3] "NoUnit"  GW
 SG_ RSDS_LEDLightReqRight : 83|2@0+ (1,0) [0|3] "NoUnit" Vector__XXX
 SG_ RSDS_LEDLightReqLeft : 85|2@0+ (1,0) [0|3] "NoUnit" Vector__XXX
 SG_ RSDS_BrkgReqVal : 77|8@0+ (0.05,-10) [-10|2.75] "MtrPerSecSq"  GW
 SG_ DOW_warningReqleft : 89|2@0+ (1,0) [0|3] "NoUnit"  GW
 SG_ DOW_warningReqRight : 91|2@0+ (1,0) [0|3] "NoUnit"  GW
 SG_ BSD_LCA_warningReqleft : 93|2@0+ (1,0) [0|3] "NoUnit"  GW
 SG_ BSD_LCA_warningReqRight : 95|2@0+ (1,0) [0|3] "NoUnit"  GW
 SG_ RSDS_RCW_Trigger : 105|2@0+ (1,0) [0|3] "NoUnit"  GW
 SG_ RSDS_RCTAResp : 112|1@0+ (1,0) [0|1] "NoUnit"  GW
 SG_ RSDS_RCWResp : 113|1@0+ (1,0) [0|1] "NoUnit"  GW
 SG_ RSDS_DOWResp : 114|1@0+ (1,0) [0|1] "NoUnit"  GW
 SG_ RSDS_LCAResp : 115|1@0+ (1,0) [0|1] "NoUnit"  GW
 SG_ RSDS_TrailerSts : 116|1@0+ (1,0) [0|1] "NoUnit"  GW
 SG_ RSDS_BliSts : 117|1@0+ (1,0) [0|1] "NoUnit"  GW
 SG_ RSDS_BrkgTrig : 118|1@0+ (1,0) [0|1] "NoUnit"  GW
 SG_ RSDS_ErrSts : 119|1@0+ (1,0) [0|1] "NoUnit"  GW
 SG_ RollingCounter_RSDS_R_2 : 123|4@0+ (1,0) [0|15] "NoUnit"  GW
 SG_ RCTA_warningReqLeft : 124|1@0+ (1,0) [0|1] "NoUnit"  GW
 SG_ RCTA_warningReqRight : 125|1@0+ (1,0) [0|1] "NoUnit"  GW
 SG_ RSDS_CTA_Actv : 126|1@0+ (1,0) [0|1] "NoUnit"  GW
 SG_ RSDS_RCTABrkResp : 127|1@0+ (1,0) [0|1] "NoUnit"  GW
 SG_ Checksum_RSDS_R_3 : 135|8@0+ (1,0) [0|255] "NoUnit"  GW
 SG_ ObjIDLe : 141|6@0+ (1,0) [0|63] "NoUnit"  GW
 SG_ LeTarSts : 143|2@0+ (1,0) [0|3] "NoUnit"  GW
 SG_ ObjLgtPosnCurvLe : 151|10@0+ (0.1,-92.3) [-92.3|10] "m"  GW
 SG_ ObjLatPosnCurvLe : 157|8@0+ (0.1,-12.8) [-12.8|12.7] "m"  GW
 SG_ ObjLgtSpdCurvLe : 165|10@0+ (0.1,-10) [-10|92.3] "mps"  GW
 SG_ ObjLatSpdCurvLe : 171|7@0+ (0.1,-6.4) [-6.4|6.3] "mps"  GW
 SG_ RollingCounter_RSDS_R_3 : 187|4@0+ (1,0) [0|15] "NoUnit"  GW
 SG_ ObjTTCLe : 180|7@0+ (0.1,0) [0|12.7] "s"  GW
 SG_ Checksum_RSDS_R_4 : 199|8@0+ (1,0) [0|255] "NoUnit"  GW
 SG_ ObjStatyLe : 200|1@0+ (1,0) [0|1] "NoUnit"  GW
 SG_ ObjWidthLe : 203|3@0+ (0.5,0) [0|3.5] "m"  GW
 SG_ ObjLenLe : 207|4@0+ (1,0) [0|15] "m"  GW
 SG_ ObjRinRi : 211|4@0+ (1,0) [0|15] "m"  GW
 SG_ ObjStsLe : 213|2@0+ (1,0) [0|3] "NoUnit"  GW
 SG_ ZoneIndLe : 215|2@0+ (1,0) [0|3] "NoUnit"  GW
 SG_ ObjStsRi : 217|2@0+ (1,0) [0|3] "NoUnit"  GW
 SG_ ZoneIndRi : 219|2@0+ (1,0) [0|3] "NoUnit"  GW
 SG_ ObjStatyRi : 220|1@0+ (1,0) [0|1] "NoUnit"  GW
 SG_ ObjWidthRi : 223|3@0+ (0.5,0) [0|3.5] "m"  GW
 SG_ RollingCounter_RSDS_R_4 : 251|4@0+ (1,0) [0|15] "NoUnit"  GW
 SG_ Checksum_RSDS_R_5 : 263|8@0+ (1,0) [0|255] "NoUnit"  GW
 SG_ ObjIDRi : 269|6@0+ (1,0) [0|63] "NoUnit"  GW
 SG_ RiTarSts : 271|2@0+ (1,0) [0|3] "NoUnit"  GW
 SG_ ObjLgtPosnCurvRi : 279|10@0+ (0.1,-92.3) [-92.3|10] "m"  GW
 SG_ ObjLatPosnCurvRi : 285|8@0+ (0.1,-12.8) [-12.8|12.7] "m"  GW
 SG_ ObjLgtSpdCurvRi : 293|10@0+ (0.1,-10) [-10|92.3] "mps"  GW
 SG_ ObjLatSpdCurvRi : 299|7@0+ (0.1,-6.4) [-6.4|6.3] "mps"  GW
 SG_ RollingCounter_RSDS_R_5 : 315|4@0+ (1,0) [0|15] "NoUnit"  GW
 SG_ ObjTTCRi : 308|7@0+ (0.1,0) [0|12.7] "s"  GW
 SG_ RSDS_ObjDistXStd_Le : 335|5@0+ (0.375,0) [0|11.625] "m"  GW
 SG_ RSDS_ObjRelVelXStd_Le : 341|5@0+ (0.375,0) [0|11.625] "mps"  GW
 SG_ RSDS_ObjDistYStd_Le : 330|5@0+ (0.375,0) [0|11.625] "m"  GW
 SG_ RSDS_ObjRelVelYStd_Le : 336|5@0+ (0.375,0) [0|11.625] "mps"  GW
 SG_ RSDS_ObjRAccelYStd_Le : 358|5@0+ (0.375,0) [0|11.625] "MtrPerSecSq"  GW
 SG_ RSDS_ObjRAccelXStd_Le : 347|5@0+ (0.375,0) [0|11.625] "MtrPerSecSq"  GW
 SG_ RSDS_ObjDistYStd_Ri : 364|5@0+ (0.375,0) [0|11.625] "m"  GW
 SG_ RSDS_ObjDistXStd_Ri : 353|5@0+ (0.375,0) [0|11.625] "m"  GW
 SG_ RSDS_ObjRelVelXStd_Ri : 375|5@0+ (0.375,0) [0|11.625] "mps"  GW
 SG_ RSDS_ObjRelVelYStd_Ri : 399|5@0+ (0.375,0) [0|11.625] "mps"  GW
 SG_ RSDS_ObjRAccelYStd_Ri : 405|5@0+ (0.375,0) [0|11.625] "MtrPerSecSq"  GW
 SG_ RSDS_ObjRAccelXStd_Ri : 394|5@0+ (0.375,0) [0|11.625] "MtrPerSecSq"  GW
 SG_ RSDS_ObjRelAccelX_Le : 415|10@0+ (0.03125,-16) [-16|15.9688] "MtrPerSecSq"  GW
 SG_ RSDS_ObjRelAccelX_Ri : 421|10@0+ (0.03125,-16) [-16|15.9688] "MtrPerSecSq"  GW
 SG_ RSDS_ObjRelAccelY_Ri : 427|10@0+ (0.03125,-16) [-16|15.9688] "MtrPerSecSq"  GW
 SG_ BSD_State : 21|3@0+ (1,0) [0|7] "NoUnit" Vector__XXX
 SG_ LCA_State : 18|3@0+ (1,0) [0|7] "NoUnit" Vector__XXX
 SG_ DOW_State : 31|3@0+ (1,0) [0|7] "NoUnit" Vector__XXX
 SG_ RCW_State : 28|3@0+ (1,0) [0|7] "NoUnit" Vector__XXX
 SG_ RCTA_State : 25|3@0+ (1,0) [0|7] "NoUnit" Vector__XXX
 SG_ RCTB_State : 38|3@0+ (1,0) [0|7] "NoUnit" Vector__XXX

BO_ 880 HUT34: 8 GW
 SG_ Time_Hour : 15|5@0+ (1,0) [0|31] "NoUnit"  CR_L,CR_R,RSDS_L,RSDS_R
 SG_ TimeMod : 16|1@0+ (1,0) [0|1] "NoUnit"  CR_L,CR_R,RSDS_L,RSDS_R
 SG_ TimeIndcn : 17|1@0+ (1,0) [0|1] "NoUnit"  CR_L,CR_R,RSDS_L,RSDS_R
 SG_ Time_Minutes : 23|6@0+ (1,0) [0|63] "NoUnit"  CR_L,CR_R,RSDS_L,RSDS_R
 SG_ Time_Second : 31|6@0+ (1,0) [0|63] "NoUnit"  CR_L,CR_R,RSDS_L,RSDS_R
 SG_ Time_Year_Right : 35|4@0+ (1,0) [0|15] "NoUnit"  CR_L,CR_R,RSDS_L,RSDS_R
 SG_ Time_Year_Left : 39|4@0+ (1,0) [0|15] "NoUnit"  CR_L,CR_R,RSDS_L,RSDS_R
 SG_ Time_Month : 47|4@0+ (1,0) [0|15] "NoUnit"  CR_L,CR_R,RSDS_L,RSDS_R
 SG_ Time_Day : 55|5@0+ (1,0) [0|31] "NoUnit"  CR_L,CR_R,RSDS_L,RSDS_R

BO_ 302 IBC_FD1: 64 GW
 SG_ InpRodStkSts : 32|1@0+ (1,0) [0|1] "NoUnit"  CR_L,CR_R,RSDS_L,RSDS_R
 SG_ PushrodStauts : 51|2@0+ (1,0) [0|3] "NoUnit"  CR_L,CR_R,RSDS_L,RSDS_R
 SG_ InpRodStk : 47|10@0+ (0.05,-5) [-5|46.15] "mm"  CR_L,CR_R,RSDS_L,RSDS_R

BO_ 181 VCU_FD1: 64 GW
 SG_ VCU_ActAccrPedlRat : 247|8@0+ (0.3937,0) [0|100.3935] "Perc"  CR_L,CR_R,RSDS_L,RSDS_R
 SG_ VCU_APedlPosVld : 219|1@0+ (1,0) [0|1] "NoUnit"  CR_L,CR_R,RSDS_L,RSDS_R
 SG_ VCU_BrkPedlSts : 217|2@0+ (1,0) [0|3] "NoUnit"  CR_L,CR_R,RSDS_L,RSDS_R
 SG_ HCU_BrkPedalStsValid : 218|1@0+ (1,0) [0|1] "NoUnit"  CR_L,CR_R,RSDS_L,RSDS_R

BO_ 1091 RSDS_R_AD1: 64 RSDS_R
 SG_ RSDS_R_hdr_ErrorStatus : 181|4@0+ (1,0) [0|15] ""  IDC_L2
 SG_ RSDS_R_hdr_TimeStamp : 207|27@0+ (0.00097,0) [0|65536] "s"  IDC_L2
 SG_ RSDS_R_ObjID_1 : 15|8@0+ (1,0) [0|255] ""  IDC_L2
 SG_ RSDS_R_ObjExistProb_1 : 23|5@0+ (0.0322581,0) [0|1] ""  IDC_L2
 SG_ RSDS_R_ObjObstacleProb_1 : 18|5@0+ (0.0322581,0) [0|1] ""  IDC_L2
 SG_ RSDS_R_ObjDistX_1 : 29|12@0+ (0.0625,-128) [-128|126.9375] "m"  IDC_L2
 SG_ RSDS_R_ObjDistY_1 : 33|11@0+ (0.125,-128) [-128|127.875] "m"  IDC_L2
 SG_ RSDS_R_ObjRelVelX_1 : 79|13@0+ (0.0312,-128) [-128|126.9976] "mps"  IDC_L2
 SG_ RSDS_R_ObjRelVelY_1 : 82|13@0+ (0.0312,-128) [-128|126.9976] "mps"  IDC_L2
 SG_ RSDS_R_ObjRelAccelX_1 : 54|10@0+ (0.03125,-16) [-16|15.96875] "mps2"  IDC_L2
 SG_ RSDS_R_ObjRelAccelY_1 : 143|10@0+ (0.03125,-16) [-16|15.96875] "mps2"  IDC_L2
 SG_ RSDS_R_ObjDistXStd_1 : 101|6@0+ (0.1,0) [0|6] "m"  IDC_L2
 SG_ RSDS_R_ObjDistYStd_1 : 111|6@0+ (0.1,0) [0|6] "m"  IDC_L2
 SG_ RSDS_R_ObjRelVelXStd_1 : 105|6@0+ (0.0625,0) [0|3.9375] "mps"  IDC_L2
 SG_ RSDS_R_ObjRelVelYStd_1 : 115|6@0+ (0.0625,0) [0|3.9375] "mps"  IDC_L2
 SG_ RSDS_R_ObjRAccelXStd_1 : 149|6@0+ (0.0625,0) [0|3.9375] "mps2"  IDC_L2
 SG_ RSDS_R_ObjRAccelYStd_1 : 159|6@0+ (0.0625,0) [0|3.9375] "mps2"  IDC_L2
 SG_ RSDS_R_VFC_ObjWidth_1 : 153|10@0+ (0.01,0) [0|5] "m"  IDC_L2
 SG_ RSDS_R_VFC_ObjLength_1 : 175|10@0+ (0.05,0) [0|20] "m"  IDC_L2
 SG_ RSDS_R_ObjID_2 : 335|8@0+ (1,0) [0|255] ""  IDC_L2
 SG_ RSDS_R_ObjExistProb_2 : 343|5@0+ (0.0322581,0) [0|1] ""  IDC_L2
 SG_ RSDS_R_ObjObstacleProb_2 : 338|5@0+ (0.0322581,0) [0|1] ""  IDC_L2
 SG_ RSDS_R_ObjDistX_2 : 349|12@0+ (0.0625,-128) [-128|126.9375] "m"  IDC_L2
 SG_ RSDS_R_ObjDistY_2 : 353|11@0+ (0.125,-128) [-128|127.875] "m"  IDC_L2
 SG_ RSDS_R_ObjRelVelX_2 : 399|13@0+ (0.0312,-128) [-128|126.9976] "mps"  IDC_L2
 SG_ RSDS_R_ObjRelVelY_2 : 402|13@0+ (0.0312,-128) [-128|126.9976] "mps"  IDC_L2
 SG_ RSDS_R_ObjRelAccelX_2 : 374|10@0+ (0.03125,-16) [-16|15.96875] "mps2"  IDC_L2
 SG_ RSDS_R_ObjRelAccelY_2 : 463|10@0+ (0.03125,-16) [-16|15.96875] "mps2"  IDC_L2
 SG_ RSDS_R_ObjDistXStd_2 : 421|6@0+ (0.1,0) [0|6] "m"  IDC_L2
 SG_ RSDS_R_ObjDistYStd_2 : 431|6@0+ (0.1,0) [0|6] "m"  IDC_L2
 SG_ RSDS_R_ObjRelVelXStd_2 : 425|6@0+ (0.0625,0) [0|3.9375] "mps"  IDC_L2
 SG_ RSDS_R_ObjRelVelYStd_2 : 435|6@0+ (0.0625,0) [0|3.9375] "mps"  IDC_L2
 SG_ RSDS_R_ObjRAccelXStd_2 : 469|6@0+ (0.0625,0) [0|3.9375] "mps2"  IDC_L2
 SG_ RSDS_R_ObjRAccelYStd_2 : 479|6@0+ (0.0625,0) [0|3.9375] "mps2"  IDC_L2
 SG_ RSDS_R_VFC_ObjWidth_2 : 473|10@0+ (0.01,0) [0|5] "m"  IDC_L2
 SG_ RSDS_R_VFC_ObjLength_2 : 495|10@0+ (0.05,0) [0|20] "m"  IDC_L2
 SG_ Checksum22 : 7|8@0+ (1,0) [0|255] ""  IDC_L2
 SG_ Checksum23 : 71|8@0+ (1,0) [0|255] ""  IDC_L2
 SG_ Checksum24 : 135|8@0+ (1,0) [0|255] ""  IDC_L2
 SG_ Checksum26 : 327|8@0+ (1,0) [0|255] ""  IDC_L2
 SG_ Checksum27 : 391|8@0+ (1,0) [0|255] ""  IDC_L2
 SG_ Checksum28 : 455|8@0+ (1,0) [0|255] ""  IDC_L2
 SG_ RollingCounter22 : 59|4@0+ (1,0) [0|15] ""  IDC_L2
 SG_ RollingCounter23 : 123|4@0+ (1,0) [0|15] ""  IDC_L2
 SG_ RollingCounter24 : 187|4@0+ (1,0) [0|15] ""  IDC_L2
 SG_ RollingCounter26 : 379|4@0+ (1,0) [0|15] ""  IDC_L2
 SG_ RollingCounter27 : 443|4@0+ (1,0) [0|15] ""  IDC_L2
 SG_ RollingCounter28 : 507|4@0+ (1,0) [0|15] ""  IDC_L2
 SG_ RSDS_R_ObjMeasured_1 : 497|2@0+ (1,0) [0|3] ""  IDC_L2
 SG_ RSDS_R_ObjMeasured_2 : 499|2@0+ (1,0) [0|3] ""  IDC_L2
 SG_ RSDS_R_BLIND : 177|2@0+ (1,0) [0|3] ""  IDC_L2
 SG_ RSDS_R_hdr_TimerStempStatus : 228|8@0+ (1,0) [0|255] ""  IDC_L2
 SG_ Checksum25 : 199|8@0+ (1,0) [0|255] ""  IDC_L2
 SG_ Rollingcounter25 : 251|4@0+ (1,0) [0|15] ""  IDC_L2
 SG_ BlockCounter4 : 236|4@0+ (1,0) [0|15] ""  IDC_L2
 SG_ RSDS_R_hdr_AutosarTimeStamp : 271|26@0+ (1,0) [0|67108863] "ms"  IDC_L2

BO_ 1092 RSDS_R_AD2: 64 RSDS_R
 SG_ RSDS_R_ObjID_3 : 15|8@0+ (1,0) [0|255] ""  IDC_L2
 SG_ RSDS_R_ObjExistProb_3 : 23|5@0+ (0.0322581,0) [0|1] ""  IDC_L2
 SG_ RSDS_R_ObjObstacleProb_3 : 18|5@0+ (0.0322581,0) [0|1] ""  IDC_L2
 SG_ RSDS_R_ObjDistX_3 : 29|12@0+ (0.0625,-128) [-128|126.9375] "m"  IDC_L2
 SG_ RSDS_R_ObjDistY_3 : 33|11@0+ (0.125,-128) [-128|127.875] "m"  IDC_L2
 SG_ RSDS_R_ObjRelVelX_3 : 79|13@0+ (0.0312,-128) [-128|126.9976] "mps"  IDC_L2
 SG_ RSDS_R_ObjRelVelY_3 : 82|13@0+ (0.0312,-128) [-128|126.9976] "mps"  IDC_L2
 SG_ RSDS_R_ObjRelAccelX_3 : 54|10@0+ (0.03125,-16) [-16|15.96875] "mps2"  IDC_L2
 SG_ RSDS_R_ObjRelAccelY_3 : 143|10@0+ (0.03125,-16) [-16|15.96875] "mps2"  IDC_L2
 SG_ RSDS_R_ObjDistXStd_3 : 101|6@0+ (0.1,0) [0|6] "m"  IDC_L2
 SG_ RSDS_R_ObjDistYStd_3 : 111|6@0+ (0.1,0) [0|6] "m"  IDC_L2
 SG_ RSDS_R_ObjRelVelXStd_3 : 105|6@0+ (0.0625,0) [0|3.9375] "mps"  IDC_L2
 SG_ RSDS_R_ObjRelVelYStd_3 : 115|6@0+ (0.0625,0) [0|3.9375] "mps"  IDC_L2
 SG_ RSDS_R_ObjRAccelXStd_3 : 149|6@0+ (0.0625,0) [0|3.9375] "mps2"  IDC_L2
 SG_ RSDS_R_ObjRAccelYStd_3 : 159|6@0+ (0.0625,0) [0|3.9375] "mps2"  IDC_L2
 SG_ RSDS_R_VFC_ObjWidth_3 : 153|10@0+ (0.01,0) [0|5] "m"  IDC_L2
 SG_ RSDS_R_VFC_ObjLength_3 : 175|10@0+ (0.05,0) [0|20] "m"  IDC_L2
 SG_ RSDS_R_ObjID_4 : 335|8@0+ (1,0) [0|255] ""  IDC_L2
 SG_ RSDS_R_ObjExistProb_4 : 343|5@0+ (0.0322581,0) [0|1] ""  IDC_L2
 SG_ RSDS_R_ObjObstacleProb_4 : 338|5@0+ (0.0322581,0) [0|1] ""  IDC_L2
 SG_ RSDS_R_ObjDistX_4 : 349|12@0+ (0.0625,-128) [-128|126.9375] "m"  IDC_L2
 SG_ RSDS_R_ObjDistY_4 : 353|11@0+ (0.125,-128) [-128|127.875] "m"  IDC_L2
 SG_ RSDS_R_ObjRelVelX_4 : 399|13@0+ (0.0312,-128) [-128|126.9976] "mps"  IDC_L2
 SG_ RSDS_R_ObjRelVelY_4 : 402|13@0+ (0.0312,-128) [-128|126.9976] "mps"  IDC_L2
 SG_ RSDS_R_ObjRelAccelX_4 : 374|10@0+ (0.03125,-16) [-16|15.96875] "mps2"  IDC_L2
 SG_ RSDS_R_ObjRelAccelY_4 : 463|10@0+ (0.03125,-16) [-16|15.96875] "mps2"  IDC_L2
 SG_ RSDS_R_ObjDistXStd_4 : 421|6@0+ (0.1,0) [0|6] "m"  IDC_L2
 SG_ RSDS_R_ObjDistYStd_4 : 431|6@0+ (0.1,0) [0|6] "m"  IDC_L2
 SG_ RSDS_R_ObjRelVelXStd_4 : 425|6@0+ (0.0625,0) [0|3.9375] "mps"  IDC_L2
 SG_ RSDS_R_ObjRelVelYStd_4 : 435|6@0+ (0.0625,0) [0|3.9375] "mps"  IDC_L2
 SG_ RSDS_R_ObjRAccelXStd_4 : 469|6@0+ (0.0625,0) [0|3.9375] "mps2"  IDC_L2
 SG_ RSDS_R_ObjRAccelYStd_4 : 479|6@0+ (0.0625,0) [0|3.9375] "mps2"  IDC_L2
 SG_ RSDS_R_VFC_ObjWidth_4 : 473|10@0+ (0.01,0) [0|5] "m"  IDC_L2
 SG_ RSDS_R_VFC_ObjLength_4 : 495|10@0+ (0.05,0) [0|20] "m"  IDC_L2
 SG_ Checksum29 : 7|8@0+ (1,0) [0|255] ""  IDC_L2
 SG_ Checksum30 : 71|8@0+ (1,0) [0|255] ""  IDC_L2
 SG_ Checksum31 : 135|8@0+ (1,0) [0|255] ""  IDC_L2
 SG_ Checksum33 : 327|8@0+ (1,0) [0|255] ""  IDC_L2
 SG_ Checksum34 : 391|8@0+ (1,0) [0|255] ""  IDC_L2
 SG_ Checksum35 : 455|8@0+ (1,0) [0|255] ""  IDC_L2
 SG_ RollingCounter29 : 59|4@0+ (1,0) [0|15] ""  IDC_L2
 SG_ RollingCounter30 : 123|4@0+ (1,0) [0|15] ""  IDC_L2
 SG_ RollingCounter31 : 187|4@0+ (1,0) [0|15] ""  IDC_L2
 SG_ RollingCounter33 : 379|4@0+ (1,0) [0|15] ""  IDC_L2
 SG_ RollingCounter34 : 443|4@0+ (1,0) [0|15] ""  IDC_L2
 SG_ RollingCounter35 : 507|4@0+ (1,0) [0|15] ""  IDC_L2
 SG_ RSDS_R_ObjMeasured_3 : 497|2@0+ (1,0) [0|3] ""  IDC_L2
 SG_ RSDS_R_ObjMeasured_4 : 499|2@0+ (1,0) [0|3] ""  IDC_L2
 SG_ Checksum32 : 199|8@0+ (1,0) [0|255] ""  IDC_L2
 SG_ Rollingcounter32 : 251|4@0+ (1,0) [0|15] ""  IDC_L2
 SG_ BlockCounter5 : 236|4@0+ (1,0) [0|15] ""  IDC_L2

BO_ 1093 RSDS_R_AD3: 64 RSDS_R
 SG_ RSDS_R_ObjID_5 : 15|8@0+ (1,0) [0|255] ""  IDC_L2
 SG_ RSDS_R_ObjExistProb_5 : 23|5@0+ (0.0322581,0) [0|1] ""  IDC_L2
 SG_ RSDS_R_ObjObstacleProb_5 : 18|5@0+ (0.0322581,0) [0|1] ""  IDC_L2
 SG_ RSDS_R_ObjDistX_5 : 29|12@0+ (0.0625,-128) [-128|126.9375] "m"  IDC_L2
 SG_ RSDS_R_ObjDistY_5 : 33|11@0+ (0.125,-128) [-128|127.875] "m"  IDC_L2
 SG_ RSDS_R_ObjRelVelX_5 : 79|13@0+ (0.0312,-128) [-128|126.9976] "mps"  IDC_L2
 SG_ RSDS_R_ObjRelVelY_5 : 82|13@0+ (0.0312,-128) [-128|126.9976] "mps"  IDC_L2
 SG_ RSDS_R_ObjRelAccelX_5 : 54|10@0+ (0.03125,-16) [-16|15.96875] "mps2"  IDC_L2
 SG_ RSDS_R_ObjRelAccelY_5 : 143|10@0+ (0.03125,-16) [-16|15.96875] "mps2"  IDC_L2
 SG_ RSDS_R_ObjDistXStd_5 : 101|6@0+ (0.1,0) [0|6] "m"  IDC_L2
 SG_ RSDS_R_ObjDistYStd_5 : 111|6@0+ (0.1,0) [0|6] "m"  IDC_L2
 SG_ RSDS_R_ObjRelVelXStd_5 : 105|6@0+ (0.0625,0) [0|3.9375] "mps"  IDC_L2
 SG_ RSDS_R_ObjRelVelYStd_5 : 115|6@0+ (0.0625,0) [0|3.9375] "mps"  IDC_L2
 SG_ RSDS_R_ObjRAccelXStd_5 : 149|6@0+ (0.0625,0) [0|3.9375] "mps2"  IDC_L2
 SG_ RSDS_R_ObjRAccelYStd_5 : 159|6@0+ (0.0625,0) [0|3.9375] "mps2"  IDC_L2
 SG_ RSDS_R_VFC_ObjWidth_5 : 153|10@0+ (0.01,0) [0|5] "m"  IDC_L2
 SG_ RSDS_R_VFC_ObjLength_5 : 175|10@0+ (0.05,0) [0|20] "m"  IDC_L2
 SG_ RSDS_R_ObjID_6 : 335|8@0+ (1,0) [0|255] ""  IDC_L2
 SG_ RSDS_R_ObjExistProb_6 : 343|5@0+ (0.0322581,0) [0|1] ""  IDC_L2
 SG_ RSDS_R_ObjObstacleProb_6 : 338|5@0+ (0.0322581,0) [0|1] ""  IDC_L2
 SG_ RSDS_R_ObjDistX_6 : 349|12@0+ (0.0625,-128) [-128|126.9375] "m"  IDC_L2
 SG_ RSDS_R_ObjDistY_6 : 353|11@0+ (0.125,-128) [-128|127.875] "m"  IDC_L2
 SG_ RSDS_R_ObjRelVelX_6 : 399|13@0+ (0.0312,-128) [-128|126.9976] "mps"  IDC_L2
 SG_ RSDS_R_ObjRelVelY_6 : 402|13@0+ (0.0312,-128) [-128|126.9976] "mps"  IDC_L2
 SG_ RSDS_R_ObjRelAccelX_6 : 374|10@0+ (0.03125,-16) [-16|15.96875] "mps2"  IDC_L2
 SG_ RSDS_R_ObjRelAccelY_6 : 463|10@0+ (0.03125,-16) [-16|15.96875] "mps2"  IDC_L2
 SG_ RSDS_R_ObjDistXStd_6 : 421|6@0+ (0.1,0) [0|6] "m"  IDC_L2
 SG_ RSDS_R_ObjDistYStd_6 : 431|6@0+ (0.1,0) [0|6] "m"  IDC_L2
 SG_ RSDS_R_ObjRelVelXStd_6 : 425|6@0+ (0.0625,0) [0|3.9375] "mps"  IDC_L2
 SG_ RSDS_R_ObjRelVelYStd_6 : 435|6@0+ (0.0625,0) [0|3.9375] "mps"  IDC_L2
 SG_ RSDS_R_ObjRAccelXStd_6 : 469|6@0+ (0.0625,0) [0|3.9375] "mps2"  IDC_L2
 SG_ RSDS_R_ObjRAccelYStd_6 : 479|6@0+ (0.0625,0) [0|3.9375] "mps2"  IDC_L2
 SG_ RSDS_R_VFC_ObjWidth_6 : 473|10@0+ (0.01,0) [0|5] "m"  IDC_L2
 SG_ RSDS_R_VFC_ObjLength_6 : 495|10@0+ (0.05,0) [0|20] "m"  IDC_L2
 SG_ Checksum36 : 7|8@0+ (1,0) [0|255] ""  IDC_L2
 SG_ Checksum37 : 71|8@0+ (1,0) [0|255] ""  IDC_L2
 SG_ Checksum38 : 135|8@0+ (1,0) [0|255] ""  IDC_L2
 SG_ Checksum40 : 327|8@0+ (1,0) [0|255] ""  IDC_L2
 SG_ Checksum41 : 391|8@0+ (1,0) [0|255] ""  IDC_L2
 SG_ Checksum42 : 455|8@0+ (1,0) [0|255] ""  IDC_L2
 SG_ RollingCounter36 : 59|4@0+ (1,0) [0|15] ""  IDC_L2
 SG_ RollingCounter37 : 123|4@0+ (1,0) [0|15] ""  IDC_L2
 SG_ RollingCounter38 : 187|4@0+ (1,0) [0|15] ""  IDC_L2
 SG_ RollingCounter40 : 379|4@0+ (1,0) [0|15] ""  IDC_L2
 SG_ RollingCounter41 : 443|4@0+ (1,0) [0|15] ""  IDC_L2
 SG_ RollingCounter42 : 507|4@0+ (1,0) [0|15] ""  IDC_L2
 SG_ RSDS_R_ObjMeasured_5 : 497|2@0+ (1,0) [0|3] ""  IDC_L2
 SG_ RSDS_R_ObjMeasured_6 : 499|2@0+ (1,0) [0|3] ""  IDC_L2
 SG_ Checksum39 : 199|8@0+ (1,0) [0|255] ""  IDC_L2
 SG_ Rollingcounter39 : 251|4@0+ (1,0) [0|15] ""  IDC_L2
 SG_ BlockCounter6 : 236|4@0+ (1,0) [0|15] ""  IDC_L2

BO_ 1424 RSDS_R_SGU1: 64 RSDS_R
 SG_ RSDS_R_ObjID_1 : 15|8@0+ (1,0) [0|255] ""  IDC15_IDC_L2_ADC15H_ADC30L
 SG_ RSDS_R_ObjExistProb_1 : 23|5@0+ (0.03326,0) [0|1] ""  IDC15_IDC_L2_ADC15H_ADC30L
 SG_ RSDS_R_ObjObstacleProb_1 : 18|5@0+ (0.03326,0) [0|1] ""  IDC15_IDC_L2_ADC15H_ADC30L
 SG_ RSDS_R_ObjDistX_1 : 29|12@0+ (0.0625,-128) [-128|127.9375] "m"  IDC15_IDC_L2_ADC15H_ADC30L
 SG_ RSDS_R_ObjDistY_1 : 33|11@0+ (0.125,-128) [-128|127.875] "m"  IDC15_IDC_L2_ADC15H_ADC30L
 SG_ RSDS_R_ObjDistXStd_1 : 54|6@0+ (0.1,0) [0|6] "m"  IDC15_IDC_L2_ADC15H_ADC30L
 SG_ RSDS_R_ObjType_1 : 63|4@0+ (1,0) [0|15] ""  IDC15_IDC_L2_ADC15H_ADC30L
 SG_ RSDS_R_ObjRelVelX_1 : 79|13@0+ (0.0312,-128) [-128|126.9976] "mps"  IDC15_IDC_L2_ADC15H_ADC30L
 SG_ RSDS_R_ObjRelVelY_1 : 82|13@0+ (0.0312,-128) [-128|126.9976] "mps"  IDC15_IDC_L2_ADC15H_ADC30L
 SG_ RSDS_R_ObjRelAccelX_1 : 101|10@0+ (0.03125,-16) [-16|15.96875] "mps2"  IDC15_IDC_L2_ADC15H_ADC30L
 SG_ RSDS_R_ObjRelAccelY_1 : 107|10@0+ (0.03125,-16) [-16|15.96875] "mps2"  IDC15_IDC_L2_ADC15H_ADC30L
 SG_ RSDS_R_ObjMotionType_1 : 127|3@0+ (1,0) [0|7] ""  IDC15_IDC_L2_ADC15H_ADC30L
 SG_ RSDS_R_ObjMeasured_1 : 113|2@0+ (1,0) [0|3] ""  IDC15_IDC_L2_ADC15H_ADC30L
 SG_ RSDS_R_ObjDistYStd_1 : 143|6@0+ (0.1,0) [0|6] "m"  IDC15_IDC_L2_ADC15H_ADC30L
 SG_ RSDS_R_ObjRelVelXStd_1 : 137|6@0+ (0.0625,0) [0|3.9375] "mps"  IDC15_IDC_L2_ADC15H_ADC30L
 SG_ RSDS_R_ObjRelVelYStd_1 : 147|6@0+ (0.0625,0) [0|3.9375] "mps"  IDC15_IDC_L2_ADC15H_ADC30L
 SG_ RSDS_R_ObjRAccelXStd_1 : 157|6@0+ (0.0625,0) [0|3.9375] "mps2"  IDC15_IDC_L2_ADC15H_ADC30L
 SG_ RSDS_R_ObjRAccelYStd_1 : 167|6@0+ (0.0625,0) [0|3.9375] "mps2"  IDC15_IDC_L2_ADC15H_ADC30L
 SG_ RSDS_R_ObjWidth_1 : 161|10@0+ (0.01,0) [0|5] "m"  IDC15_IDC_L2_ADC15H_ADC30L
 SG_ RSDS_R_ObjMotionDirection_1 : 191|3@0+ (1,0) [0|7] ""  IDC15_IDC_L2_ADC15H_ADC30L
 SG_ RSDS_R_ObjAge_1 : 183|8@0+ (1,0) [0|255] ""  IDC15_IDC_L2_ADC15H_ADC30L
 SG_ RSDS_R_ObjLength_1 : 207|10@0+ (0.05,0) [0|20] "m"  IDC15_IDC_L2_ADC15H_ADC30L
 SG_ RSDS_R_ObjHeading_1 : 213|12@0+ (0.002,-3.14) [-3.14|3.14] "rad"  IDC15_IDC_L2_ADC15H_ADC30L
 SG_ RSDS_R_ObjYawrate_1 : 217|12@0+ (0.002,-3.14) [-3.14|3.14] "rad/s"  IDC15_IDC_L2_ADC15H_ADC30L
 SG_ RSDS_R_ObjRCS_1 : 237|10@0+ (0.125,-50) [-50|70] "dBm2"  IDC15_IDC_L2_ADC15H_ADC30L
 SG_ RSDS_R_ObjRefPoint_1 : 243|3@0+ (1,0) [0|8] ""  IDC15_IDC_L2_ADC15H_ADC30L
 SG_ RSDS_R_HWATargetValidity_1 : 240|1@0+ (1,0) [0|1] ""  IDC15_IDC_L2_ADC15H_ADC30L
 SG_ RSDS_R_ObjID_2 : 271|8@0+ (1,0) [0|255] ""  IDC15_IDC_L2_ADC15H_ADC30L
 SG_ RSDS_R_ObjExistProb_2 : 279|5@0+ (0.03326,0) [0|1] ""  IDC15_IDC_L2_ADC15H_ADC30L
 SG_ RSDS_R_ObjObstacleProb_2 : 274|5@0+ (0.03326,0) [0|1] ""  IDC15_IDC_L2_ADC15H_ADC30L
 SG_ RSDS_R_ObjDistX_2 : 285|12@0+ (0.0625,-128) [-128|127.9375] "m"  IDC15_IDC_L2_ADC15H_ADC30L
 SG_ RSDS_R_ObjDistY_2 : 289|11@0+ (0.125,-128) [-128|127.875] "m"  IDC15_IDC_L2_ADC15H_ADC30L
 SG_ RSDS_R_ObjDistXStd_2 : 310|6@0+ (0.1,0) [0|6] "m"  IDC15_IDC_L2_ADC15H_ADC30L
 SG_ RSDS_R_ObjType_2 : 319|4@0+ (1,0) [0|15] ""  IDC15_IDC_L2_ADC15H_ADC30L
 SG_ RSDS_R_ObjRelVelX_2 : 335|13@0+ (0.0312,-128) [-128|126.9976] "mps"  IDC15_IDC_L2_ADC15H_ADC30L
 SG_ RSDS_R_ObjRelVelY_2 : 338|13@0+ (0.0312,-128) [-128|126.9976] "mps"  IDC15_IDC_L2_ADC15H_ADC30L
 SG_ RSDS_R_ObjRelAccelX_2 : 357|10@0+ (0.03125,-16) [-16|15.96875] "mps2"  IDC15_IDC_L2_ADC15H_ADC30L
 SG_ RSDS_R_ObjRelAccelY_2 : 363|10@0+ (0.03125,-16) [-16|15.96875] "mps2"  IDC15_IDC_L2_ADC15H_ADC30L
 SG_ RSDS_R_ObjMotionType_2 : 383|3@0+ (1,0) [0|7] ""  IDC15_IDC_L2_ADC15H_ADC30L
 SG_ RSDS_R_ObjMeasured_2 : 369|2@0+ (1,0) [0|3] ""  IDC15_IDC_L2_ADC15H_ADC30L
 SG_ RSDS_R_ObjDistYStd_2 : 399|6@0+ (0.1,0) [0|6] "m"  IDC15_IDC_L2_ADC15H_ADC30L
 SG_ RSDS_R_ObjRelVelXStd_2 : 393|6@0+ (0.0625,0) [0|3.9375] "mps"  IDC15_IDC_L2_ADC15H_ADC30L
 SG_ RSDS_R_ObjRelVelYStd_2 : 403|6@0+ (0.0625,0) [0|3.9375] "mps"  IDC15_IDC_L2_ADC15H_ADC30L
 SG_ RSDS_R_ObjRAccelXStd_2 : 413|6@0+ (0.0625,0) [0|3.9375] "mps2"  IDC15_IDC_L2_ADC15H_ADC30L
 SG_ RSDS_R_ObjRAccelYStd_2 : 423|6@0+ (0.0625,0) [0|3.9375] "mps2"  IDC15_IDC_L2_ADC15H_ADC30L
 SG_ RSDS_R_ObjWidth_2 : 417|10@0+ (0.01,0) [0|5] "m"  IDC15_IDC_L2_ADC15H_ADC30L
 SG_ RSDS_R_ObjMotionDirection_2 : 447|3@0+ (1,0) [0|7] ""  IDC15_IDC_L2_ADC15H_ADC30L
 SG_ RSDS_R_ObjAge_2 : 439|8@0+ (1,0) [0|255] ""  IDC15_IDC_L2_ADC15H_ADC30L
 SG_ RSDS_R_ObjLength_2 : 463|10@0+ (0.05,0) [0|20] "m"  IDC15_IDC_L2_ADC15H_ADC30L
 SG_ RSDS_R_ObjHeading_2 : 469|12@0+ (0.002,-3.14) [-3.14|3.14] "rad"  IDC15_IDC_L2_ADC15H_ADC30L
 SG_ RSDS_R_ObjYawrate_2 : 473|12@0+ (0.002,-3.14) [-3.14|3.14] "rad/s"  IDC15_IDC_L2_ADC15H_ADC30L
 SG_ RSDS_R_ObjRCS_2 : 493|10@0+ (0.125,-50) [-50|70] "dBm2"  IDC15_IDC_L2_ADC15H_ADC30L
 SG_ RSDS_R_ObjRefPoint_2 : 499|3@0+ (1,0) [0|8] ""  IDC15_IDC_L2_ADC15H_ADC30L
 SG_ RSDS_R_HWATargetValidity_2 : 496|1@0+ (1,0) [0|1] ""  IDC15_IDC_L2_ADC15H_ADC30L
 SG_ RSDS_R_SGU1_BlockCounter : 511|4@0+ (1,0) [0|15] ""  IDC15_IDC_L2_ADC15H_ADC30L
 SG_ RSDS_R_SGU1_Checksum1 : 7|8@0+ (1,0) [0|255] ""  IDC15_IDC_L2_ADC15H_ADC30L
 SG_ RSDS_R_SGU1_Checksum2 : 71|8@0+ (1,0) [0|255] ""  IDC15_IDC_L2_ADC15H_ADC30L
 SG_ RSDS_R_SGU1_Checksum3 : 135|8@0+ (1,0) [0|255] ""  IDC15_IDC_L2_ADC15H_ADC30L
 SG_ RSDS_R_SGU1_Checksum4 : 199|8@0+ (1,0) [0|255] ""  IDC15_IDC_L2_ADC15H_ADC30L
 SG_ RSDS_R_SGU1_Checksum5 : 263|8@0+ (1,0) [0|255] ""  IDC15_IDC_L2_ADC15H_ADC30L
 SG_ RSDS_R_SGU1_Checksum6 : 327|8@0+ (1,0) [0|255] ""  IDC15_IDC_L2_ADC15H_ADC30L
 SG_ RSDS_R_SGU1_Checksum7 : 391|8@0+ (1,0) [0|255] ""  IDC15_IDC_L2_ADC15H_ADC30L
 SG_ RSDS_R_SGU1_Checksum8 : 455|8@0+ (1,0) [0|255] ""  IDC15_IDC_L2_ADC15H_ADC30L
 SG_ RSDS_R_SGU1_RollingCounter1 : 59|4@0+ (1,0) [0|15] ""  IDC15_IDC_L2_ADC15H_ADC30L
 SG_ RSDS_R_SGU1_RollingCounter2 : 123|4@0+ (1,0) [0|15] ""  IDC15_IDC_L2_ADC15H_ADC30L
 SG_ RSDS_R_SGU1_RollingCounter3 : 187|4@0+ (1,0) [0|15] ""  IDC15_IDC_L2_ADC15H_ADC30L
 SG_ RSDS_R_SGU1_RollingCounter4 : 251|4@0+ (1,0) [0|15] ""  IDC15_IDC_L2_ADC15H_ADC30L
 SG_ RSDS_R_SGU1_RollingCounter5 : 315|4@0+ (1,0) [0|15] ""  IDC15_IDC_L2_ADC15H_ADC30L
 SG_ RSDS_R_SGU1_RollingCounter6 : 379|4@0+ (1,0) [0|15] ""  IDC15_IDC_L2_ADC15H_ADC30L
 SG_ RSDS_R_SGU1_RollingCounter7 : 443|4@0+ (1,0) [0|15] ""  IDC15_IDC_L2_ADC15H_ADC30L
 SG_ RSDS_R_SGU1_RollingCounter8 : 507|4@0+ (1,0) [0|15] ""  IDC15_IDC_L2_ADC15H_ADC30L

BO_ 1425 RSDS_R_SGU2: 64 RSDS_R
 SG_ RSDS_R_ObjID_3 : 15|8@0+ (1,0) [0|255] ""  IDC15_IDC_L2_ADC15H_ADC30L
 SG_ RSDS_R_ObjExistProb_3 : 23|5@0+ (0.03326,0) [0|1] ""  IDC15_IDC_L2_ADC15H_ADC30L
 SG_ RSDS_R_ObjObstacleProb_3 : 18|5@0+ (0.03326,0) [0|1] ""  IDC15_IDC_L2_ADC15H_ADC30L
 SG_ RSDS_R_ObjDistX_3 : 29|12@0+ (0.0625,-128) [-128|127.9375] "m"  IDC15_IDC_L2_ADC15H_ADC30L
 SG_ RSDS_R_ObjDistY_3 : 33|11@0+ (0.125,-128) [-128|127.875] "m"  IDC15_IDC_L2_ADC15H_ADC30L
 SG_ RSDS_R_ObjDistXStd_3 : 54|6@0+ (0.1,0) [0|6] "m"  IDC15_IDC_L2_ADC15H_ADC30L
 SG_ RSDS_R_ObjType_3 : 63|4@0+ (1,0) [0|15] ""  IDC15_IDC_L2_ADC15H_ADC30L
 SG_ RSDS_R_ObjRelVelX_3 : 79|13@0+ (0.0312,-128) [-128|126.9976] "mps"  IDC15_IDC_L2_ADC15H_ADC30L
 SG_ RSDS_R_ObjRelVelY_3 : 82|13@0+ (0.0312,-128) [-128|126.9976] "mps"  IDC15_IDC_L2_ADC15H_ADC30L
 SG_ RSDS_R_ObjRelAccelX_3 : 101|10@0+ (0.03125,-16) [-16|15.96875] "mps2"  IDC15_IDC_L2_ADC15H_ADC30L
 SG_ RSDS_R_ObjRelAccelY_3 : 107|10@0+ (0.03125,-16) [-16|15.96875] "mps2"  IDC15_IDC_L2_ADC15H_ADC30L
 SG_ RSDS_R_ObjMotionType_3 : 127|3@0+ (1,0) [0|7] ""  IDC15_IDC_L2_ADC15H_ADC30L
 SG_ RSDS_R_ObjMeasured_3 : 113|2@0+ (1,0) [0|3] ""  IDC15_IDC_L2_ADC15H_ADC30L
 SG_ RSDS_R_ObjDistYStd_3 : 143|6@0+ (0.1,0) [0|6] "m"  IDC15_IDC_L2_ADC15H_ADC30L
 SG_ RSDS_R_ObjRelVelXStd_3 : 137|6@0+ (0.0625,0) [0|3.9375] "mps"  IDC15_IDC_L2_ADC15H_ADC30L
 SG_ RSDS_R_ObjRelVelYStd_3 : 147|6@0+ (0.0625,0) [0|3.9375] "mps"  IDC15_IDC_L2_ADC15H_ADC30L
 SG_ RSDS_R_ObjRAccelXStd_3 : 157|6@0+ (0.0625,0) [0|3.9375] "mps2"  IDC15_IDC_L2_ADC15H_ADC30L
 SG_ RSDS_R_ObjRAccelYStd_3 : 167|6@0+ (0.0625,0) [0|3.9375] "mps2"  IDC15_IDC_L2_ADC15H_ADC30L
 SG_ RSDS_R_ObjWidth_3 : 161|10@0+ (0.01,0) [0|5] "m"  IDC15_IDC_L2_ADC15H_ADC30L
 SG_ RSDS_R_ObjMotionDirection_3 : 191|3@0+ (1,0) [0|7] ""  IDC15_IDC_L2_ADC15H_ADC30L
 SG_ RSDS_R_ObjAge_3 : 183|8@0+ (1,0) [0|255] ""  IDC15_IDC_L2_ADC15H_ADC30L
 SG_ RSDS_R_ObjLength_3 : 207|10@0+ (0.05,0) [0|20] "m"  IDC15_IDC_L2_ADC15H_ADC30L
 SG_ RSDS_R_ObjHeading_3 : 213|12@0+ (0.002,-3.14) [-3.14|3.14] "rad"  IDC15_IDC_L2_ADC15H_ADC30L
 SG_ RSDS_R_ObjYawrate_3 : 217|12@0+ (0.002,-3.14) [-3.14|3.14] "rad/s"  IDC15_IDC_L2_ADC15H_ADC30L
 SG_ RSDS_R_ObjRCS_3 : 237|10@0+ (0.125,-50) [-50|70] "dBm2"  IDC15_IDC_L2_ADC15H_ADC30L
 SG_ RSDS_R_ObjRefPoint_3 : 243|3@0+ (1,0) [0|8] ""  IDC15_IDC_L2_ADC15H_ADC30L
 SG_ RSDS_R_HWATargetValidity_3 : 240|1@0+ (1,0) [0|1] ""  IDC15_IDC_L2_ADC15H_ADC30L
 SG_ RSDS_R_ObjID_4 : 271|8@0+ (1,0) [0|255] ""  IDC15_IDC_L2_ADC15H_ADC30L
 SG_ RSDS_R_ObjExistProb_4 : 279|5@0+ (0.03326,0) [0|1] ""  IDC15_IDC_L2_ADC15H_ADC30L
 SG_ RSDS_R_ObjObstacleProb_4 : 274|5@0+ (0.03326,0) [0|1] ""  IDC15_IDC_L2_ADC15H_ADC30L
 SG_ RSDS_R_ObjDistX_4 : 285|12@0+ (0.0625,-128) [-128|127.9375] "m"  IDC15_IDC_L2_ADC15H_ADC30L
 SG_ RSDS_R_ObjDistY_4 : 289|11@0+ (0.125,-128) [-128|127.875] "m"  IDC15_IDC_L2_ADC15H_ADC30L
 SG_ RSDS_R_ObjDistXStd_4 : 310|6@0+ (0.1,0) [0|6] "m"  IDC15_IDC_L2_ADC15H_ADC30L
 SG_ RSDS_R_ObjType_4 : 319|4@0+ (1,0) [0|15] ""  IDC15_IDC_L2_ADC15H_ADC30L
 SG_ RSDS_R_ObjRelVelX_4 : 335|13@0+ (0.0312,-128) [-128|126.9976] "mps"  IDC15_IDC_L2_ADC15H_ADC30L
 SG_ RSDS_R_ObjRelVelY_4 : 338|13@0+ (0.0312,-128) [-128|126.9976] "mps"  IDC15_IDC_L2_ADC15H_ADC30L
 SG_ RSDS_R_ObjRelAccelX_4 : 357|10@0+ (0.03125,-16) [-16|15.96875] "mps2"  IDC15_IDC_L2_ADC15H_ADC30L
 SG_ RSDS_R_ObjRelAccelY_4 : 363|10@0+ (0.03125,-16) [-16|15.96875] "mps2"  IDC15_IDC_L2_ADC15H_ADC30L
 SG_ RSDS_R_ObjMotionType_4 : 383|3@0+ (1,0) [0|7] ""  IDC15_IDC_L2_ADC15H_ADC30L
 SG_ RSDS_R_ObjMeasured_4 : 369|2@0+ (1,0) [0|3] ""  IDC15_IDC_L2_ADC15H_ADC30L
 SG_ RSDS_R_ObjDistYStd_4 : 399|6@0+ (0.1,0) [0|6] "m"  IDC15_IDC_L2_ADC15H_ADC30L
 SG_ RSDS_R_ObjRelVelXStd_4 : 393|6@0+ (0.0625,0) [0|3.9375] "mps"  IDC15_IDC_L2_ADC15H_ADC30L
 SG_ RSDS_R_ObjRelVelYStd_4 : 403|6@0+ (0.0625,0) [0|3.9375] "mps"  IDC15_IDC_L2_ADC15H_ADC30L
 SG_ RSDS_R_ObjRAccelXStd_4 : 413|6@0+ (0.0625,0) [0|3.9375] "mps2"  IDC15_IDC_L2_ADC15H_ADC30L
 SG_ RSDS_R_ObjRAccelYStd_4 : 423|6@0+ (0.0625,0) [0|3.9375] "mps2"  IDC15_IDC_L2_ADC15H_ADC30L
 SG_ RSDS_R_ObjWidth_4 : 417|10@0+ (0.01,0) [0|5] "m"  IDC15_IDC_L2_ADC15H_ADC30L
 SG_ RSDS_R_ObjMotionDirection_4 : 447|3@0+ (1,0) [0|7] ""  IDC15_IDC_L2_ADC15H_ADC30L
 SG_ RSDS_R_ObjAge_4 : 439|8@0+ (1,0) [0|255] ""  IDC15_IDC_L2_ADC15H_ADC30L
 SG_ RSDS_R_ObjLength_4 : 463|10@0+ (0.05,0) [0|20] "m"  IDC15_IDC_L2_ADC15H_ADC30L
 SG_ RSDS_R_ObjHeading_4 : 469|12@0+ (0.002,-3.14) [-3.14|3.14] "rad"  IDC15_IDC_L2_ADC15H_ADC30L
 SG_ RSDS_R_ObjYawrate_4 : 473|12@0+ (0.002,-3.14) [-3.14|3.14] "rad/s"  IDC15_IDC_L2_ADC15H_ADC30L
 SG_ RSDS_R_ObjRCS_4 : 493|10@0+ (0.125,-50) [-50|70] "dBm2"  IDC15_IDC_L2_ADC15H_ADC30L
 SG_ RSDS_R_ObjRefPoint_4 : 499|3@0+ (1,0) [0|8] ""  IDC15_IDC_L2_ADC15H_ADC30L
 SG_ RSDS_R_HWATargetValidity_4 : 496|1@0+ (1,0) [0|1] ""  IDC15_IDC_L2_ADC15H_ADC30L
 SG_ RSDS_R_SGU2_BlockCounter : 511|4@0+ (1,0) [0|15] ""  IDC15_IDC_L2_ADC15H_ADC30L
 SG_ RSDS_R_SGU2_Checksum1 : 7|8@0+ (1,0) [0|255] ""  IDC15_IDC_L2_ADC15H_ADC30L
 SG_ RSDS_R_SGU2_Checksum2 : 71|8@0+ (1,0) [0|255] ""  IDC15_IDC_L2_ADC15H_ADC30L
 SG_ RSDS_R_SGU2_Checksum3 : 135|8@0+ (1,0) [0|255] ""  IDC15_IDC_L2_ADC15H_ADC30L
 SG_ RSDS_R_SGU2_Checksum4 : 199|8@0+ (1,0) [0|255] ""  IDC15_IDC_L2_ADC15H_ADC30L
 SG_ RSDS_R_SGU2_Checksum5 : 263|8@0+ (1,0) [0|255] ""  IDC15_IDC_L2_ADC15H_ADC30L
 SG_ RSDS_R_SGU2_Checksum6 : 327|8@0+ (1,0) [0|255] ""  IDC15_IDC_L2_ADC15H_ADC30L
 SG_ RSDS_R_SGU2_Checksum7 : 391|8@0+ (1,0) [0|255] ""  IDC15_IDC_L2_ADC15H_ADC30L
 SG_ RSDS_R_SGU2_Checksum8 : 455|8@0+ (1,0) [0|255] ""  IDC15_IDC_L2_ADC15H_ADC30L
 SG_ RSDS_R_SGU2_RollingCounter1 : 59|4@0+ (1,0) [0|15] ""  IDC15_IDC_L2_ADC15H_ADC30L
 SG_ RSDS_R_SGU2_RollingCounter2 : 123|4@0+ (1,0) [0|15] ""  IDC15_IDC_L2_ADC15H_ADC30L
 SG_ RSDS_R_SGU2_RollingCounter3 : 187|4@0+ (1,0) [0|15] ""  IDC15_IDC_L2_ADC15H_ADC30L
 SG_ RSDS_R_SGU2_RollingCounter4 : 251|4@0+ (1,0) [0|15] ""  IDC15_IDC_L2_ADC15H_ADC30L
 SG_ RSDS_R_SGU2_RollingCounter5 : 315|4@0+ (1,0) [0|15] ""  IDC15_IDC_L2_ADC15H_ADC30L
 SG_ RSDS_R_SGU2_RollingCounter6 : 379|4@0+ (1,0) [0|15] ""  IDC15_IDC_L2_ADC15H_ADC30L
 SG_ RSDS_R_SGU2_RollingCounter7 : 443|4@0+ (1,0) [0|15] ""  IDC15_IDC_L2_ADC15H_ADC30L
 SG_ RSDS_R_SGU2_RollingCounter8 : 507|4@0+ (1,0) [0|15] ""  IDC15_IDC_L2_ADC15H_ADC30L

BO_ 1426 RSDS_R_SGU3: 64 RSDS_R
 SG_ RSDS_R_ObjID_5 : 15|8@0+ (1,0) [0|255] ""  IDC15_IDC_L2_ADC15H_ADC30L
 SG_ RSDS_R_ObjExistProb_5 : 23|5@0+ (0.03326,0) [0|1] ""  IDC15_IDC_L2_ADC15H_ADC30L
 SG_ RSDS_R_ObjObstacleProb_5 : 18|5@0+ (0.03326,0) [0|1] ""  IDC15_IDC_L2_ADC15H_ADC30L
 SG_ RSDS_R_ObjDistX_5 : 29|12@0+ (0.0625,-128) [-128|127.9375] "m"  IDC15_IDC_L2_ADC15H_ADC30L
 SG_ RSDS_R_ObjDistY_5 : 33|11@0+ (0.125,-128) [-128|127.875] "m"  IDC15_IDC_L2_ADC15H_ADC30L
 SG_ RSDS_R_ObjDistXStd_5 : 54|6@0+ (0.1,0) [0|6] "m"  IDC15_IDC_L2_ADC15H_ADC30L
 SG_ RSDS_R_ObjType_5 : 63|4@0+ (1,0) [0|15] ""  IDC15_IDC_L2_ADC15H_ADC30L
 SG_ RSDS_R_ObjRelVelX_5 : 79|13@0+ (0.0312,-128) [-128|126.9976] "mps"  IDC15_IDC_L2_ADC15H_ADC30L
 SG_ RSDS_R_ObjRelVelY_5 : 82|13@0+ (0.0312,-128) [-128|126.9976] "mps"  IDC15_IDC_L2_ADC15H_ADC30L
 SG_ RSDS_R_ObjRelAccelX_5 : 101|10@0+ (0.03125,-16) [-16|15.96875] "mps2"  IDC15_IDC_L2_ADC15H_ADC30L
 SG_ RSDS_R_ObjRelAccelY_5 : 107|10@0+ (0.03125,-16) [-16|15.96875] "mps2"  IDC15_IDC_L2_ADC15H_ADC30L
 SG_ RSDS_R_ObjMotionType_5 : 127|3@0+ (1,0) [0|7] ""  IDC15_IDC_L2_ADC15H_ADC30L
 SG_ RSDS_R_ObjMeasured_5 : 113|2@0+ (1,0) [0|3] ""  IDC15_IDC_L2_ADC15H_ADC30L
 SG_ RSDS_R_ObjDistYStd_5 : 143|6@0+ (0.1,0) [0|6] "m"  IDC15_IDC_L2_ADC15H_ADC30L
 SG_ RSDS_R_ObjRelVelXStd_5 : 137|6@0+ (0.0625,0) [0|3.9375] "mps"  IDC15_IDC_L2_ADC15H_ADC30L
 SG_ RSDS_R_ObjRelVelYStd_5 : 147|6@0+ (0.0625,0) [0|3.9375] "mps"  IDC15_IDC_L2_ADC15H_ADC30L
 SG_ RSDS_R_ObjRAccelXStd_5 : 157|6@0+ (0.0625,0) [0|3.9375] "mps2"  IDC15_IDC_L2_ADC15H_ADC30L
 SG_ RSDS_R_ObjRAccelYStd_5 : 167|6@0+ (0.0625,0) [0|3.9375] "mps2"  IDC15_IDC_L2_ADC15H_ADC30L
 SG_ RSDS_R_ObjWidth_5 : 161|10@0+ (0.01,0) [0|5] "m"  IDC15_IDC_L2_ADC15H_ADC30L
 SG_ RSDS_R_ObjMotionDirection_5 : 191|3@0+ (1,0) [0|7] ""  IDC15_IDC_L2_ADC15H_ADC30L
 SG_ RSDS_R_ObjAge_5 : 183|8@0+ (1,0) [0|255] ""  IDC15_IDC_L2_ADC15H_ADC30L
 SG_ RSDS_R_ObjLength_5 : 207|10@0+ (0.05,0) [0|20] "m"  IDC15_IDC_L2_ADC15H_ADC30L
 SG_ RSDS_R_ObjHeading_5 : 213|12@0+ (0.002,-3.14) [-3.14|3.14] "rad"  IDC15_IDC_L2_ADC15H_ADC30L
 SG_ RSDS_R_ObjYawrate_5 : 217|12@0+ (0.002,-3.14) [-3.14|3.14] "rad/s"  IDC15_IDC_L2_ADC15H_ADC30L
 SG_ RSDS_R_ObjRCS_5 : 237|10@0+ (0.125,-50) [-50|70] "dBm2"  IDC15_IDC_L2_ADC15H_ADC30L
 SG_ RSDS_R_ObjRefPoint_5 : 243|3@0+ (1,0) [0|8] ""  IDC15_IDC_L2_ADC15H_ADC30L
 SG_ RSDS_R_HWATargetValidity_5 : 240|1@0+ (1,0) [0|1] ""  IDC15_IDC_L2_ADC15H_ADC30L
 SG_ RSDS_R_ObjID_6 : 271|8@0+ (1,0) [0|255] ""  IDC15_IDC_L2_ADC15H_ADC30L
 SG_ RSDS_R_ObjExistProb_6 : 279|5@0+ (0.03326,0) [0|1] ""  IDC15_IDC_L2_ADC15H_ADC30L
 SG_ RSDS_R_ObjObstacleProb_6 : 274|5@0+ (0.03326,0) [0|1] ""  IDC15_IDC_L2_ADC15H_ADC30L
 SG_ RSDS_R_ObjDistX_6 : 285|12@0+ (0.0625,-128) [-128|127.9375] "m"  IDC15_IDC_L2_ADC15H_ADC30L
 SG_ RSDS_R_ObjDistY_6 : 289|11@0+ (0.125,-128) [-128|127.875] "m"  IDC15_IDC_L2_ADC15H_ADC30L
 SG_ RSDS_R_ObjDistXStd_6 : 310|6@0+ (0.1,0) [0|6] "m"  IDC15_IDC_L2_ADC15H_ADC30L
 SG_ RSDS_R_ObjType_6 : 319|4@0+ (1,0) [0|15] ""  IDC15_IDC_L2_ADC15H_ADC30L
 SG_ RSDS_R_ObjRelVelX_6 : 335|13@0+ (0.0312,-128) [-128|126.9976] "mps"  IDC15_IDC_L2_ADC15H_ADC30L
 SG_ RSDS_R_ObjRelVelY_6 : 338|13@0+ (0.0312,-128) [-128|126.9976] "mps"  IDC15_IDC_L2_ADC15H_ADC30L
 SG_ RSDS_R_ObjRelAccelX_6 : 357|10@0+ (0.03125,-16) [-16|15.96875] "mps2"  IDC15_IDC_L2_ADC15H_ADC30L
 SG_ RSDS_R_ObjRelAccelY_6 : 363|10@0+ (0.03125,-16) [-16|15.96875] "mps2"  IDC15_IDC_L2_ADC15H_ADC30L
 SG_ RSDS_R_ObjMotionType_6 : 383|3@0+ (1,0) [0|7] ""  IDC15_IDC_L2_ADC15H_ADC30L
 SG_ RSDS_R_ObjMeasured_6 : 369|2@0+ (1,0) [0|3] ""  IDC15_IDC_L2_ADC15H_ADC30L
 SG_ RSDS_R_ObjDistYStd_6 : 399|6@0+ (0.1,0) [0|6] "m"  IDC15_IDC_L2_ADC15H_ADC30L
 SG_ RSDS_R_ObjRelVelXStd_6 : 393|6@0+ (0.0625,0) [0|3.9375] "mps"  IDC15_IDC_L2_ADC15H_ADC30L
 SG_ RSDS_R_ObjRelVelYStd_6 : 403|6@0+ (0.0625,0) [0|3.9375] "mps"  IDC15_IDC_L2_ADC15H_ADC30L
 SG_ RSDS_R_ObjRAccelXStd_6 : 413|6@0+ (0.0625,0) [0|3.9375] "mps2"  IDC15_IDC_L2_ADC15H_ADC30L
 SG_ RSDS_R_ObjRAccelYStd_6 : 423|6@0+ (0.0625,0) [0|3.9375] "mps2"  IDC15_IDC_L2_ADC15H_ADC30L
 SG_ RSDS_R_ObjWidth_6 : 417|10@0+ (0.01,0) [0|5] "m"  IDC15_IDC_L2_ADC15H_ADC30L
 SG_ RSDS_R_ObjMotionDirection_6 : 447|3@0+ (1,0) [0|7] ""  IDC15_IDC_L2_ADC15H_ADC30L
 SG_ RSDS_R_ObjAge_6 : 439|8@0+ (1,0) [0|255] ""  IDC15_IDC_L2_ADC15H_ADC30L
 SG_ RSDS_R_ObjLength_6 : 463|10@0+ (0.05,0) [0|20] "m"  IDC15_IDC_L2_ADC15H_ADC30L
 SG_ RSDS_R_ObjHeading_6 : 469|12@0+ (0.002,-3.14) [-3.14|3.14] "rad"  IDC15_IDC_L2_ADC15H_ADC30L
 SG_ RSDS_R_ObjYawrate_6 : 473|12@0+ (0.002,-3.14) [-3.14|3.14] "rad/s"  IDC15_IDC_L2_ADC15H_ADC30L
 SG_ RSDS_R_ObjRCS_6 : 493|10@0+ (0.125,-50) [-50|70] "dBm2"  IDC15_IDC_L2_ADC15H_ADC30L
 SG_ RSDS_R_ObjRefPoint_6 : 499|3@0+ (1,0) [0|8] ""  IDC15_IDC_L2_ADC15H_ADC30L
 SG_ RSDS_R_HWATargetValidity_6 : 496|1@0+ (1,0) [0|1] ""  IDC15_IDC_L2_ADC15H_ADC30L
 SG_ RSDS_R_SGU3_BlockCounter : 511|4@0+ (1,0) [0|15] ""  IDC15_IDC_L2_ADC15H_ADC30L
 SG_ RSDS_R_SGU3_Checksum1 : 7|8@0+ (1,0) [0|255] ""  IDC15_IDC_L2_ADC15H_ADC30L
 SG_ RSDS_R_SGU3_Checksum2 : 71|8@0+ (1,0) [0|255] ""  IDC15_IDC_L2_ADC15H_ADC30L
 SG_ RSDS_R_SGU3_Checksum3 : 135|8@0+ (1,0) [0|255] ""  IDC15_IDC_L2_ADC15H_ADC30L
 SG_ RSDS_R_SGU3_Checksum4 : 199|8@0+ (1,0) [0|255] ""  IDC15_IDC_L2_ADC15H_ADC30L
 SG_ RSDS_R_SGU3_Checksum5 : 263|8@0+ (1,0) [0|255] ""  IDC15_IDC_L2_ADC15H_ADC30L
 SG_ RSDS_R_SGU3_Checksum6 : 327|8@0+ (1,0) [0|255] ""  IDC15_IDC_L2_ADC15H_ADC30L
 SG_ RSDS_R_SGU3_Checksum7 : 391|8@0+ (1,0) [0|255] ""  IDC15_IDC_L2_ADC15H_ADC30L
 SG_ RSDS_R_SGU3_Checksum8 : 455|8@0+ (1,0) [0|255] ""  IDC15_IDC_L2_ADC15H_ADC30L
 SG_ RSDS_R_SGU3_RollingCounter1 : 59|4@0+ (1,0) [0|15] ""  IDC15_IDC_L2_ADC15H_ADC30L
 SG_ RSDS_R_SGU3_RollingCounter2 : 123|4@0+ (1,0) [0|15] ""  IDC15_IDC_L2_ADC15H_ADC30L
 SG_ RSDS_R_SGU3_RollingCounter3 : 187|4@0+ (1,0) [0|15] ""  IDC15_IDC_L2_ADC15H_ADC30L
 SG_ RSDS_R_SGU3_RollingCounter4 : 251|4@0+ (1,0) [0|15] ""  IDC15_IDC_L2_ADC15H_ADC30L
 SG_ RSDS_R_SGU3_RollingCounter5 : 315|4@0+ (1,0) [0|15] ""  IDC15_IDC_L2_ADC15H_ADC30L
 SG_ RSDS_R_SGU3_RollingCounter6 : 379|4@0+ (1,0) [0|15] ""  IDC15_IDC_L2_ADC15H_ADC30L
 SG_ RSDS_R_SGU3_RollingCounter7 : 443|4@0+ (1,0) [0|15] ""  IDC15_IDC_L2_ADC15H_ADC30L
 SG_ RSDS_R_SGU3_RollingCounter8 : 507|4@0+ (1,0) [0|15] ""  IDC15_IDC_L2_ADC15H_ADC30L

BO_ 1427 RSDS_R_SGU4: 64 RSDS_R
 SG_ RSDS_R_ObjID_7 : 15|8@0+ (1,0) [0|255] ""  IDC15_IDC_L2_ADC15H_ADC30L
 SG_ RSDS_R_ObjExistProb_7 : 23|5@0+ (0.03326,0) [0|1] ""  IDC15_IDC_L2_ADC15H_ADC30L
 SG_ RSDS_R_ObjObstacleProb_7 : 18|5@0+ (0.03326,0) [0|1] ""  IDC15_IDC_L2_ADC15H_ADC30L
 SG_ RSDS_R_ObjDistX_7 : 29|12@0+ (0.0625,-128) [-128|127.9375] "m"  IDC15_IDC_L2_ADC15H_ADC30L
 SG_ RSDS_R_ObjDistY_7 : 33|11@0+ (0.125,-128) [-128|127.875] "m"  IDC15_IDC_L2_ADC15H_ADC30L
 SG_ RSDS_R_ObjDistXStd_7 : 54|6@0+ (0.1,0) [0|6] "m"  IDC15_IDC_L2_ADC15H_ADC30L
 SG_ RSDS_R_ObjType_7 : 63|4@0+ (1,0) [0|15] ""  IDC15_IDC_L2_ADC15H_ADC30L
 SG_ RSDS_R_ObjRelVelX_7 : 79|13@0+ (0.0312,-128) [-128|126.9976] "mps"  IDC15_IDC_L2_ADC15H_ADC30L
 SG_ RSDS_R_ObjRelVelY_7 : 82|13@0+ (0.0312,-128) [-128|126.9976] "mps"  IDC15_IDC_L2_ADC15H_ADC30L
 SG_ RSDS_R_ObjRelAccelX_7 : 101|10@0+ (0.03125,-16) [-16|15.96875] "mps2"  IDC15_IDC_L2_ADC15H_ADC30L
 SG_ RSDS_R_ObjRelAccelY_7 : 107|10@0+ (0.03125,-16) [-16|15.96875] "mps2"  IDC15_IDC_L2_ADC15H_ADC30L
 SG_ RSDS_R_ObjMotionType_7 : 127|3@0+ (1,0) [0|7] ""  IDC15_IDC_L2_ADC15H_ADC30L
 SG_ RSDS_R_ObjMeasured_7 : 113|2@0+ (1,0) [0|3] ""  IDC15_IDC_L2_ADC15H_ADC30L
 SG_ RSDS_R_ObjDistYStd_7 : 143|6@0+ (0.1,0) [0|6] "m"  IDC15_IDC_L2_ADC15H_ADC30L
 SG_ RSDS_R_ObjRelVelXStd_7 : 137|6@0+ (0.0625,0) [0|3.9375] "mps"  IDC15_IDC_L2_ADC15H_ADC30L
 SG_ RSDS_R_ObjRelVelYStd_7 : 147|6@0+ (0.0625,0) [0|3.9375] "mps"  IDC15_IDC_L2_ADC15H_ADC30L
 SG_ RSDS_R_ObjRAccelXStd_7 : 157|6@0+ (0.0625,0) [0|3.9375] "mps2"  IDC15_IDC_L2_ADC15H_ADC30L
 SG_ RSDS_R_ObjRAccelYStd_7 : 167|6@0+ (0.0625,0) [0|3.9375] "mps2"  IDC15_IDC_L2_ADC15H_ADC30L
 SG_ RSDS_R_ObjWidth_7 : 161|10@0+ (0.01,0) [0|5] "m"  IDC15_IDC_L2_ADC15H_ADC30L
 SG_ RSDS_R_ObjMotionDirection_7 : 191|3@0+ (1,0) [0|7] ""  IDC15_IDC_L2_ADC15H_ADC30L
 SG_ RSDS_R_ObjAge_7 : 183|8@0+ (1,0) [0|255] ""  IDC15_IDC_L2_ADC15H_ADC30L
 SG_ RSDS_R_ObjLength_7 : 207|10@0+ (0.05,0) [0|20] "m"  IDC15_IDC_L2_ADC15H_ADC30L
 SG_ RSDS_R_ObjHeading_7 : 213|12@0+ (0.002,-3.14) [-3.14|3.14] "rad"  IDC15_IDC_L2_ADC15H_ADC30L
 SG_ RSDS_R_ObjYawrate_7 : 217|12@0+ (0.002,-3.14) [-3.14|3.14] "rad/s"  IDC15_IDC_L2_ADC15H_ADC30L
 SG_ RSDS_R_ObjRCS_7 : 237|10@0+ (0.125,-50) [-50|70] "dBm2"  IDC15_IDC_L2_ADC15H_ADC30L
 SG_ RSDS_R_ObjRefPoint_7 : 243|3@0+ (1,0) [0|8] ""  IDC15_IDC_L2_ADC15H_ADC30L
 SG_ RSDS_R_HWATargetValidity_7 : 240|1@0+ (1,0) [0|1] ""  IDC15_IDC_L2_ADC15H_ADC30L
 SG_ RSDS_R_ObjID_8 : 271|8@0+ (1,0) [0|255] ""  IDC15_IDC_L2_ADC15H_ADC30L
 SG_ RSDS_R_ObjExistProb_8 : 279|5@0+ (0.03326,0) [0|1] ""  IDC15_IDC_L2_ADC15H_ADC30L
 SG_ RSDS_R_ObjObstacleProb_8 : 274|5@0+ (0.03326,0) [0|1] ""  IDC15_IDC_L2_ADC15H_ADC30L
 SG_ RSDS_R_ObjDistX_8 : 285|12@0+ (0.0625,-128) [-128|127.9375] "m"  IDC15_IDC_L2_ADC15H_ADC30L
 SG_ RSDS_R_ObjDistY_8 : 289|11@0+ (0.125,-128) [-128|127.875] "m"  IDC15_IDC_L2_ADC15H_ADC30L
 SG_ RSDS_R_ObjDistXStd_8 : 310|6@0+ (0.1,0) [0|6] "m"  IDC15_IDC_L2_ADC15H_ADC30L
 SG_ RSDS_R_ObjType_8 : 319|4@0+ (1,0) [0|15] ""  IDC15_IDC_L2_ADC15H_ADC30L
 SG_ RSDS_R_ObjRelVelX_8 : 335|13@0+ (0.0312,-128) [-128|126.9976] "mps"  IDC15_IDC_L2_ADC15H_ADC30L
 SG_ RSDS_R_ObjRelVelY_8 : 338|13@0+ (0.0312,-128) [-128|126.9976] "mps"  IDC15_IDC_L2_ADC15H_ADC30L
 SG_ RSDS_R_ObjRelAccelX_8 : 357|10@0+ (0.03125,-16) [-16|15.96875] "mps2"  IDC15_IDC_L2_ADC15H_ADC30L
 SG_ RSDS_R_ObjRelAccelY_8 : 363|10@0+ (0.03125,-16) [-16|15.96875] "mps2"  IDC15_IDC_L2_ADC15H_ADC30L
 SG_ RSDS_R_ObjMotionType_8 : 383|3@0+ (1,0) [0|7] ""  IDC15_IDC_L2_ADC15H_ADC30L
 SG_ RSDS_R_ObjMeasured_8 : 369|2@0+ (1,0) [0|3] ""  IDC15_IDC_L2_ADC15H_ADC30L
 SG_ RSDS_R_ObjDistYStd_8 : 399|6@0+ (0.1,0) [0|6] "m"  IDC15_IDC_L2_ADC15H_ADC30L
 SG_ RSDS_R_ObjRelVelXStd_8 : 393|6@0+ (0.0625,0) [0|3.9375] "mps"  IDC15_IDC_L2_ADC15H_ADC30L
 SG_ RSDS_R_ObjRelVelYStd_8 : 403|6@0+ (0.0625,0) [0|3.9375] "mps"  IDC15_IDC_L2_ADC15H_ADC30L
 SG_ RSDS_R_ObjRAccelXStd_8 : 413|6@0+ (0.0625,0) [0|3.9375] "mps2"  IDC15_IDC_L2_ADC15H_ADC30L
 SG_ RSDS_R_ObjRAccelYStd_8 : 423|6@0+ (0.0625,0) [0|3.9375] "mps2"  IDC15_IDC_L2_ADC15H_ADC30L
 SG_ RSDS_R_ObjWidth_8 : 417|10@0+ (0.01,0) [0|5] "m"  IDC15_IDC_L2_ADC15H_ADC30L
 SG_ RSDS_R_ObjMotionDirection_8 : 447|3@0+ (1,0) [0|7] ""  IDC15_IDC_L2_ADC15H_ADC30L
 SG_ RSDS_R_ObjAge_8 : 439|8@0+ (1,0) [0|255] ""  IDC15_IDC_L2_ADC15H_ADC30L
 SG_ RSDS_R_ObjLength_8 : 463|10@0+ (0.05,0) [0|20] "m"  IDC15_IDC_L2_ADC15H_ADC30L
 SG_ RSDS_R_ObjHeading_8 : 469|12@0+ (0.002,-3.14) [-3.14|3.14] "rad"  IDC15_IDC_L2_ADC15H_ADC30L
 SG_ RSDS_R_ObjYawrate_8 : 473|12@0+ (0.002,-3.14) [-3.14|3.14] "rad/s"  IDC15_IDC_L2_ADC15H_ADC30L
 SG_ RSDS_R_ObjRCS_8 : 493|10@0+ (0.125,-50) [-50|70] "dBm2"  IDC15_IDC_L2_ADC15H_ADC30L
 SG_ RSDS_R_ObjRefPoint_8 : 499|3@0+ (1,0) [0|8] ""  IDC15_IDC_L2_ADC15H_ADC30L
 SG_ RSDS_R_HWATargetValidity_8 : 496|1@0+ (1,0) [0|1] ""  IDC15_IDC_L2_ADC15H_ADC30L
 SG_ RSDS_R_SGU4_BlockCounter : 511|4@0+ (1,0) [0|15] ""  IDC15_IDC_L2_ADC15H_ADC30L
 SG_ RSDS_R_SGU4_Checksum1 : 7|8@0+ (1,0) [0|255] ""  IDC15_IDC_L2_ADC15H_ADC30L
 SG_ RSDS_R_SGU4_Checksum2 : 71|8@0+ (1,0) [0|255] ""  IDC15_IDC_L2_ADC15H_ADC30L
 SG_ RSDS_R_SGU4_Checksum3 : 135|8@0+ (1,0) [0|255] ""  IDC15_IDC_L2_ADC15H_ADC30L
 SG_ RSDS_R_SGU4_Checksum4 : 199|8@0+ (1,0) [0|255] ""  IDC15_IDC_L2_ADC15H_ADC30L
 SG_ RSDS_R_SGU4_Checksum5 : 263|8@0+ (1,0) [0|255] ""  IDC15_IDC_L2_ADC15H_ADC30L
 SG_ RSDS_R_SGU4_Checksum6 : 327|8@0+ (1,0) [0|255] ""  IDC15_IDC_L2_ADC15H_ADC30L
 SG_ RSDS_R_SGU4_Checksum7 : 391|8@0+ (1,0) [0|255] ""  IDC15_IDC_L2_ADC15H_ADC30L
 SG_ RSDS_R_SGU4_Checksum8 : 455|8@0+ (1,0) [0|255] ""  IDC15_IDC_L2_ADC15H_ADC30L
 SG_ RSDS_R_SGU4_RollingCounter1 : 59|4@0+ (1,0) [0|15] ""  IDC15_IDC_L2_ADC15H_ADC30L
 SG_ RSDS_R_SGU4_RollingCounter2 : 123|4@0+ (1,0) [0|15] ""  IDC15_IDC_L2_ADC15H_ADC30L
 SG_ RSDS_R_SGU4_RollingCounter3 : 187|4@0+ (1,0) [0|15] ""  IDC15_IDC_L2_ADC15H_ADC30L
 SG_ RSDS_R_SGU4_RollingCounter4 : 251|4@0+ (1,0) [0|15] ""  IDC15_IDC_L2_ADC15H_ADC30L
 SG_ RSDS_R_SGU4_RollingCounter5 : 315|4@0+ (1,0) [0|15] ""  IDC15_IDC_L2_ADC15H_ADC30L
 SG_ RSDS_R_SGU4_RollingCounter6 : 379|4@0+ (1,0) [0|15] ""  IDC15_IDC_L2_ADC15H_ADC30L
 SG_ RSDS_R_SGU4_RollingCounter7 : 443|4@0+ (1,0) [0|15] ""  IDC15_IDC_L2_ADC15H_ADC30L
 SG_ RSDS_R_SGU4_RollingCounter8 : 507|4@0+ (1,0) [0|15] ""  IDC15_IDC_L2_ADC15H_ADC30L

CM_ SG_ 395 AEB_TgtDecel_ReqValue "0x0000-0xFFFE:Valid value
0xFFFF:Invalid";
CM_ SG_ 639 IP_VehTotDistance "B";
CM_ SG_ 639 IP_VehTotDistanceValid "B";
CM_ SG_ 181 VCU_ActAccrPedlRat "/";
CM_ SG_ 181 VCU_APedlPosVld "/";
CM_ SG_ 1091 RSDS_R_hdr_ErrorStatus "/";
CM_ SG_ 1091 RSDS_R_hdr_TimeStamp "/";
CM_ SG_ 1091 RSDS_R_ObjID_1 "/";
CM_ SG_ 1091 RSDS_R_ObjExistProb_1 "/";
CM_ SG_ 1091 RSDS_R_ObjObstacleProb_1 "/";
CM_ SG_ 1091 RSDS_R_ObjDistX_1 "/";
CM_ SG_ 1091 RSDS_R_ObjDistY_1 "/";
CM_ SG_ 1091 RSDS_R_ObjRelVelX_1 "/";
CM_ SG_ 1091 RSDS_R_ObjRelVelY_1 "/";
CM_ SG_ 1091 RSDS_R_ObjRelAccelX_1 "/";
CM_ SG_ 1091 RSDS_R_ObjRelAccelY_1 "/";
CM_ SG_ 1091 RSDS_R_ObjDistXStd_1 "/";
CM_ SG_ 1091 RSDS_R_ObjDistYStd_1 "/";
CM_ SG_ 1091 RSDS_R_ObjRelVelXStd_1 "/";
CM_ SG_ 1091 RSDS_R_ObjRelVelYStd_1 "/";
CM_ SG_ 1091 RSDS_R_ObjRAccelXStd_1 "/";
CM_ SG_ 1091 RSDS_R_ObjRAccelYStd_1 "/";
CM_ SG_ 1091 RSDS_R_VFC_ObjWidth_1 "/";
CM_ SG_ 1091 RSDS_R_VFC_ObjLength_1 "/";
CM_ SG_ 1091 RSDS_R_ObjID_2 "/";
CM_ SG_ 1091 RSDS_R_ObjExistProb_2 "/";
CM_ SG_ 1091 RSDS_R_ObjObstacleProb_2 "/";
CM_ SG_ 1091 RSDS_R_ObjDistX_2 "/";
CM_ SG_ 1091 RSDS_R_ObjDistY_2 "/";
CM_ SG_ 1091 RSDS_R_ObjRelVelX_2 "/";
CM_ SG_ 1091 RSDS_R_ObjRelVelY_2 "/";
CM_ SG_ 1091 RSDS_R_ObjRelAccelX_2 "/";
CM_ SG_ 1091 RSDS_R_ObjRelAccelY_2 "/";
CM_ SG_ 1091 RSDS_R_ObjDistXStd_2 "/";
CM_ SG_ 1091 RSDS_R_ObjDistYStd_2 "/";
CM_ SG_ 1091 RSDS_R_ObjRelVelXStd_2 "/";
CM_ SG_ 1091 RSDS_R_ObjRelVelYStd_2 "/";
CM_ SG_ 1091 RSDS_R_ObjRAccelXStd_2 "/";
CM_ SG_ 1091 RSDS_R_ObjRAccelYStd_2 "/";
CM_ SG_ 1091 RSDS_R_VFC_ObjWidth_2 "/";
CM_ SG_ 1091 RSDS_R_VFC_ObjLength_2 "/";
CM_ SG_ 1091 Checksum22 "/";
CM_ SG_ 1091 Checksum23 "/";
CM_ SG_ 1091 Checksum24 "/";
CM_ SG_ 1091 Checksum26 "/";
CM_ SG_ 1091 Checksum27 "/";
CM_ SG_ 1091 Checksum28 "/";
CM_ SG_ 1091 RollingCounter22 "/";
CM_ SG_ 1091 RollingCounter23 "/";
CM_ SG_ 1091 RollingCounter24 "/";
CM_ SG_ 1091 RollingCounter26 "/";
CM_ SG_ 1091 RollingCounter27 "/";
CM_ SG_ 1091 RollingCounter28 "/";
CM_ SG_ 1091 RSDS_R_ObjMeasured_1 "/";
CM_ SG_ 1091 RSDS_R_ObjMeasured_2 "/";
CM_ SG_ 1091 RSDS_R_BLIND "/";
CM_ SG_ 1091 RSDS_R_hdr_TimerStempStatus "/";
CM_ SG_ 1091 Checksum25 "/";
CM_ SG_ 1091 Rollingcounter25 "/";
CM_ SG_ 1091 BlockCounter4 "/";
CM_ SG_ 1091 RSDS_R_hdr_AutosarTimeStamp "/";
CM_ SG_ 1092 RSDS_R_ObjID_3 "/";
CM_ SG_ 1092 RSDS_R_ObjExistProb_3 "/";
CM_ SG_ 1092 RSDS_R_ObjObstacleProb_3 "/";
CM_ SG_ 1092 RSDS_R_ObjDistX_3 "/";
CM_ SG_ 1092 RSDS_R_ObjDistY_3 "/";
CM_ SG_ 1092 RSDS_R_ObjRelVelX_3 "/";
CM_ SG_ 1092 RSDS_R_ObjRelVelY_3 "/";
CM_ SG_ 1092 RSDS_R_ObjRelAccelX_3 "/";
CM_ SG_ 1092 RSDS_R_ObjRelAccelY_3 "/";
CM_ SG_ 1092 RSDS_R_ObjDistXStd_3 "/";
CM_ SG_ 1092 RSDS_R_ObjDistYStd_3 "/";
CM_ SG_ 1092 RSDS_R_ObjRelVelXStd_3 "/";
CM_ SG_ 1092 RSDS_R_ObjRelVelYStd_3 "/";
CM_ SG_ 1092 RSDS_R_ObjRAccelXStd_3 "/";
CM_ SG_ 1092 RSDS_R_ObjRAccelYStd_3 "/";
CM_ SG_ 1092 RSDS_R_VFC_ObjWidth_3 "/";
CM_ SG_ 1092 RSDS_R_VFC_ObjLength_3 "/";
CM_ SG_ 1092 RSDS_R_ObjID_4 "/";
CM_ SG_ 1092 RSDS_R_ObjExistProb_4 "/";
CM_ SG_ 1092 RSDS_R_ObjObstacleProb_4 "/";
CM_ SG_ 1092 RSDS_R_ObjDistX_4 "/";
CM_ SG_ 1092 RSDS_R_ObjDistY_4 "/";
CM_ SG_ 1092 RSDS_R_ObjRelVelX_4 "/";
CM_ SG_ 1092 RSDS_R_ObjRelVelY_4 "/";
CM_ SG_ 1092 RSDS_R_ObjRelAccelX_4 "/";
CM_ SG_ 1092 RSDS_R_ObjRelAccelY_4 "/";
CM_ SG_ 1092 RSDS_R_ObjDistXStd_4 "/";
CM_ SG_ 1092 RSDS_R_ObjDistYStd_4 "/";
CM_ SG_ 1092 RSDS_R_ObjRelVelXStd_4 "/";
CM_ SG_ 1092 RSDS_R_ObjRelVelYStd_4 "/";
CM_ SG_ 1092 RSDS_R_ObjRAccelXStd_4 "/";
CM_ SG_ 1092 RSDS_R_ObjRAccelYStd_4 "/";
CM_ SG_ 1092 RSDS_R_VFC_ObjWidth_4 "/";
CM_ SG_ 1092 RSDS_R_VFC_ObjLength_4 "/";
CM_ SG_ 1092 Checksum29 "/";
CM_ SG_ 1092 Checksum30 "/";
CM_ SG_ 1092 Checksum31 "/";
CM_ SG_ 1092 Checksum33 "/";
CM_ SG_ 1092 Checksum34 "/";
CM_ SG_ 1092 Checksum35 "/";
CM_ SG_ 1092 RollingCounter29 "/";
CM_ SG_ 1092 RollingCounter30 "/";
CM_ SG_ 1092 RollingCounter31 "/";
CM_ SG_ 1092 RollingCounter33 "/";
CM_ SG_ 1092 RollingCounter34 "/";
CM_ SG_ 1092 RollingCounter35 "/";
CM_ SG_ 1092 RSDS_R_ObjMeasured_3 "/";
CM_ SG_ 1092 RSDS_R_ObjMeasured_4 "/";
CM_ SG_ 1092 Checksum32 "/";
CM_ SG_ 1092 Rollingcounter32 "/";
CM_ SG_ 1092 BlockCounter5 "/";
CM_ SG_ 1093 RSDS_R_ObjID_5 "/";
CM_ SG_ 1093 RSDS_R_ObjExistProb_5 "/";
CM_ SG_ 1093 RSDS_R_ObjObstacleProb_5 "/";
CM_ SG_ 1093 RSDS_R_ObjDistX_5 "/";
CM_ SG_ 1093 RSDS_R_ObjDistY_5 "/";
CM_ SG_ 1093 RSDS_R_ObjRelVelX_5 "/";
CM_ SG_ 1093 RSDS_R_ObjRelVelY_5 "/";
CM_ SG_ 1093 RSDS_R_ObjRelAccelX_5 "/";
CM_ SG_ 1093 RSDS_R_ObjRelAccelY_5 "/";
CM_ SG_ 1093 RSDS_R_ObjDistXStd_5 "/";
CM_ SG_ 1093 RSDS_R_ObjDistYStd_5 "/";
CM_ SG_ 1093 RSDS_R_ObjRelVelXStd_5 "/";
CM_ SG_ 1093 RSDS_R_ObjRelVelYStd_5 "/";
CM_ SG_ 1093 RSDS_R_ObjRAccelXStd_5 "/";
CM_ SG_ 1093 RSDS_R_ObjRAccelYStd_5 "/";
CM_ SG_ 1093 RSDS_R_VFC_ObjWidth_5 "/";
CM_ SG_ 1093 RSDS_R_VFC_ObjLength_5 "/";
CM_ SG_ 1093 RSDS_R_ObjID_6 "/";
CM_ SG_ 1093 RSDS_R_ObjExistProb_6 "/";
CM_ SG_ 1093 RSDS_R_ObjObstacleProb_6 "/";
CM_ SG_ 1093 RSDS_R_ObjDistX_6 "/";
CM_ SG_ 1093 RSDS_R_ObjDistY_6 "/";
CM_ SG_ 1093 RSDS_R_ObjRelVelX_6 "/";
CM_ SG_ 1093 RSDS_R_ObjRelVelY_6 "/";
CM_ SG_ 1093 RSDS_R_ObjRelAccelX_6 "/";
CM_ SG_ 1093 RSDS_R_ObjRelAccelY_6 "/";
CM_ SG_ 1093 RSDS_R_ObjDistXStd_6 "/";
CM_ SG_ 1093 RSDS_R_ObjDistYStd_6 "/";
CM_ SG_ 1093 RSDS_R_ObjRelVelXStd_6 "/";
CM_ SG_ 1093 RSDS_R_ObjRelVelYStd_6 "/";
CM_ SG_ 1093 RSDS_R_ObjRAccelXStd_6 "/";
CM_ SG_ 1093 RSDS_R_ObjRAccelYStd_6 "/";
CM_ SG_ 1093 RSDS_R_VFC_ObjWidth_6 "/";
CM_ SG_ 1093 RSDS_R_VFC_ObjLength_6 "/";
CM_ SG_ 1093 Checksum36 "/";
CM_ SG_ 1093 Checksum37 "/";
CM_ SG_ 1093 Checksum38 "/";
CM_ SG_ 1093 Checksum40 "/";
CM_ SG_ 1093 Checksum41 "/";
CM_ SG_ 1093 Checksum42 "/";
CM_ SG_ 1093 RollingCounter36 "/";
CM_ SG_ 1093 RollingCounter37 "/";
CM_ SG_ 1093 RollingCounter38 "/";
CM_ SG_ 1093 RollingCounter40 "/";
CM_ SG_ 1093 RollingCounter41 "/";
CM_ SG_ 1093 RollingCounter42 "/";
CM_ SG_ 1093 RSDS_R_ObjMeasured_5 "/";
CM_ SG_ 1093 RSDS_R_ObjMeasured_6 "/";
CM_ SG_ 1093 Checksum39 "/";
CM_ SG_ 1093 Rollingcounter39 "/";
CM_ SG_ 1093 BlockCounter6 "/";
CM_ SG_ 1424 RSDS_R_ObjID_1 "/";
CM_ SG_ 1424 RSDS_R_ObjExistProb_1 "/";
CM_ SG_ 1424 RSDS_R_ObjObstacleProb_1 "/";
CM_ SG_ 1424 RSDS_R_ObjDistX_1 "/";
CM_ SG_ 1424 RSDS_R_ObjDistY_1 "/";
CM_ SG_ 1424 RSDS_R_ObjDistXStd_1 "/";
CM_ SG_ 1424 RSDS_R_ObjType_1 "/";
CM_ SG_ 1424 RSDS_R_ObjRelVelX_1 "/";
CM_ SG_ 1424 RSDS_R_ObjRelVelY_1 "/";
CM_ SG_ 1424 RSDS_R_ObjRelAccelX_1 "/";
CM_ SG_ 1424 RSDS_R_ObjRelAccelY_1 "/";
CM_ SG_ 1424 RSDS_R_ObjMotionType_1 "/";
CM_ SG_ 1424 RSDS_R_ObjMeasured_1 "/";
CM_ SG_ 1424 RSDS_R_ObjDistYStd_1 "/";
CM_ SG_ 1424 RSDS_R_ObjRelVelXStd_1 "/";
CM_ SG_ 1424 RSDS_R_ObjRelVelYStd_1 "/";
CM_ SG_ 1424 RSDS_R_ObjRAccelXStd_1 "/";
CM_ SG_ 1424 RSDS_R_ObjRAccelYStd_1 "/";
CM_ SG_ 1424 RSDS_R_ObjWidth_1 "/";
CM_ SG_ 1424 RSDS_R_ObjMotionDirection_1 "/";
CM_ SG_ 1424 RSDS_R_ObjAge_1 "/";
CM_ SG_ 1424 RSDS_R_ObjLength_1 "/";
CM_ SG_ 1424 RSDS_R_ObjHeading_1 "/";
CM_ SG_ 1424 RSDS_R_ObjYawrate_1 "/";
CM_ SG_ 1424 RSDS_R_ObjRCS_1 "/";
CM_ SG_ 1424 RSDS_R_ObjRefPoint_1 "/";
CM_ SG_ 1424 RSDS_R_HWATargetValidity_1 "/";
CM_ SG_ 1424 RSDS_R_ObjID_2 "/";
CM_ SG_ 1424 RSDS_R_ObjExistProb_2 "/";
CM_ SG_ 1424 RSDS_R_ObjObstacleProb_2 "/";
CM_ SG_ 1424 RSDS_R_ObjDistX_2 "/";
CM_ SG_ 1424 RSDS_R_ObjDistY_2 "/";
CM_ SG_ 1424 RSDS_R_ObjDistXStd_2 "/";
CM_ SG_ 1424 RSDS_R_ObjType_2 "/";
CM_ SG_ 1424 RSDS_R_ObjRelVelX_2 "/";
CM_ SG_ 1424 RSDS_R_ObjRelVelY_2 "/";
CM_ SG_ 1424 RSDS_R_ObjRelAccelX_2 "/";
CM_ SG_ 1424 RSDS_R_ObjRelAccelY_2 "/";
CM_ SG_ 1424 RSDS_R_ObjMotionType_2 "/";
CM_ SG_ 1424 RSDS_R_ObjMeasured_2 "/";
CM_ SG_ 1424 RSDS_R_ObjDistYStd_2 "/";
CM_ SG_ 1424 RSDS_R_ObjRelVelXStd_2 "/";
CM_ SG_ 1424 RSDS_R_ObjRelVelYStd_2 "/";
CM_ SG_ 1424 RSDS_R_ObjRAccelXStd_2 "/";
CM_ SG_ 1424 RSDS_R_ObjRAccelYStd_2 "/";
CM_ SG_ 1424 RSDS_R_ObjWidth_2 "/";
CM_ SG_ 1424 RSDS_R_ObjMotionDirection_2 "/";
CM_ SG_ 1424 RSDS_R_ObjAge_2 "/";
CM_ SG_ 1424 RSDS_R_ObjLength_2 "/";
CM_ SG_ 1424 RSDS_R_ObjHeading_2 "/";
CM_ SG_ 1424 RSDS_R_ObjYawrate_2 "/";
CM_ SG_ 1424 RSDS_R_ObjRCS_2 "/";
CM_ SG_ 1424 RSDS_R_ObjRefPoint_2 "/";
CM_ SG_ 1424 RSDS_R_HWATargetValidity_2 "/";
CM_ SG_ 1424 RSDS_R_SGU1_BlockCounter "/";
CM_ SG_ 1424 RSDS_R_SGU1_Checksum1 "/";
CM_ SG_ 1424 RSDS_R_SGU1_Checksum2 "/";
CM_ SG_ 1424 RSDS_R_SGU1_Checksum3 "/";
CM_ SG_ 1424 RSDS_R_SGU1_Checksum4 "/";
CM_ SG_ 1424 RSDS_R_SGU1_Checksum5 "/";
CM_ SG_ 1424 RSDS_R_SGU1_Checksum6 "/";
CM_ SG_ 1424 RSDS_R_SGU1_Checksum7 "/";
CM_ SG_ 1424 RSDS_R_SGU1_Checksum8 "/";
CM_ SG_ 1424 RSDS_R_SGU1_RollingCounter1 "/";
CM_ SG_ 1424 RSDS_R_SGU1_RollingCounter2 "/";
CM_ SG_ 1424 RSDS_R_SGU1_RollingCounter3 "/";
CM_ SG_ 1424 RSDS_R_SGU1_RollingCounter4 "/";
CM_ SG_ 1424 RSDS_R_SGU1_RollingCounter5 "/";
CM_ SG_ 1424 RSDS_R_SGU1_RollingCounter6 "/";
CM_ SG_ 1424 RSDS_R_SGU1_RollingCounter7 "/";
CM_ SG_ 1424 RSDS_R_SGU1_RollingCounter8 "/";
CM_ SG_ 1425 RSDS_R_ObjID_3 "/";
CM_ SG_ 1425 RSDS_R_ObjExistProb_3 "/";
CM_ SG_ 1425 RSDS_R_ObjObstacleProb_3 "/";
CM_ SG_ 1425 RSDS_R_ObjDistX_3 "/";
CM_ SG_ 1425 RSDS_R_ObjDistY_3 "/";
CM_ SG_ 1425 RSDS_R_ObjDistXStd_3 "/";
CM_ SG_ 1425 RSDS_R_ObjType_3 "/";
CM_ SG_ 1425 RSDS_R_ObjRelVelX_3 "/";
CM_ SG_ 1425 RSDS_R_ObjRelVelY_3 "/";
CM_ SG_ 1425 RSDS_R_ObjRelAccelX_3 "/";
CM_ SG_ 1425 RSDS_R_ObjRelAccelY_3 "/";
CM_ SG_ 1425 RSDS_R_ObjMotionType_3 "/";
CM_ SG_ 1425 RSDS_R_ObjMeasured_3 "/";
CM_ SG_ 1425 RSDS_R_ObjDistYStd_3 "/";
CM_ SG_ 1425 RSDS_R_ObjRelVelXStd_3 "/";
CM_ SG_ 1425 RSDS_R_ObjRelVelYStd_3 "/";
CM_ SG_ 1425 RSDS_R_ObjRAccelXStd_3 "/";
CM_ SG_ 1425 RSDS_R_ObjRAccelYStd_3 "/";
CM_ SG_ 1425 RSDS_R_ObjWidth_3 "/";
CM_ SG_ 1425 RSDS_R_ObjMotionDirection_3 "/";
CM_ SG_ 1425 RSDS_R_ObjAge_3 "/";
CM_ SG_ 1425 RSDS_R_ObjLength_3 "/";
CM_ SG_ 1425 RSDS_R_ObjHeading_3 "/";
CM_ SG_ 1425 RSDS_R_ObjYawrate_3 "/";
CM_ SG_ 1425 RSDS_R_ObjRCS_3 "/";
CM_ SG_ 1425 RSDS_R_ObjRefPoint_3 "/";
CM_ SG_ 1425 RSDS_R_HWATargetValidity_3 "/";
CM_ SG_ 1425 RSDS_R_ObjID_4 "/";
CM_ SG_ 1425 RSDS_R_ObjExistProb_4 "/";
CM_ SG_ 1425 RSDS_R_ObjObstacleProb_4 "/";
CM_ SG_ 1425 RSDS_R_ObjDistX_4 "/";
CM_ SG_ 1425 RSDS_R_ObjDistY_4 "/";
CM_ SG_ 1425 RSDS_R_ObjDistXStd_4 "/";
CM_ SG_ 1425 RSDS_R_ObjType_4 "/";
CM_ SG_ 1425 RSDS_R_ObjRelVelX_4 "/";
CM_ SG_ 1425 RSDS_R_ObjRelVelY_4 "/";
CM_ SG_ 1425 RSDS_R_ObjRelAccelX_4 "/";
CM_ SG_ 1425 RSDS_R_ObjRelAccelY_4 "/";
CM_ SG_ 1425 RSDS_R_ObjMotionType_4 "/";
CM_ SG_ 1425 RSDS_R_ObjMeasured_4 "/";
CM_ SG_ 1425 RSDS_R_ObjDistYStd_4 "/";
CM_ SG_ 1425 RSDS_R_ObjRelVelXStd_4 "/";
CM_ SG_ 1425 RSDS_R_ObjRelVelYStd_4 "/";
CM_ SG_ 1425 RSDS_R_ObjRAccelXStd_4 "/";
CM_ SG_ 1425 RSDS_R_ObjRAccelYStd_4 "/";
CM_ SG_ 1425 RSDS_R_ObjWidth_4 "/";
CM_ SG_ 1425 RSDS_R_ObjMotionDirection_4 "/";
CM_ SG_ 1425 RSDS_R_ObjAge_4 "/";
CM_ SG_ 1425 RSDS_R_ObjLength_4 "/";
CM_ SG_ 1425 RSDS_R_ObjHeading_4 "/";
CM_ SG_ 1425 RSDS_R_ObjYawrate_4 "/";
CM_ SG_ 1425 RSDS_R_ObjRCS_4 "/";
CM_ SG_ 1425 RSDS_R_ObjRefPoint_4 "/";
CM_ SG_ 1425 RSDS_R_HWATargetValidity_4 "/";
CM_ SG_ 1425 RSDS_R_SGU2_BlockCounter "/";
CM_ SG_ 1425 RSDS_R_SGU2_Checksum1 "/";
CM_ SG_ 1425 RSDS_R_SGU2_Checksum2 "/";
CM_ SG_ 1425 RSDS_R_SGU2_Checksum3 "/";
CM_ SG_ 1425 RSDS_R_SGU2_Checksum4 "/";
CM_ SG_ 1425 RSDS_R_SGU2_Checksum5 "/";
CM_ SG_ 1425 RSDS_R_SGU2_Checksum6 "/";
CM_ SG_ 1425 RSDS_R_SGU2_Checksum7 "/";
CM_ SG_ 1425 RSDS_R_SGU2_Checksum8 "/";
CM_ SG_ 1425 RSDS_R_SGU2_RollingCounter1 "/";
CM_ SG_ 1425 RSDS_R_SGU2_RollingCounter2 "/";
CM_ SG_ 1425 RSDS_R_SGU2_RollingCounter3 "/";
CM_ SG_ 1425 RSDS_R_SGU2_RollingCounter4 "/";
CM_ SG_ 1425 RSDS_R_SGU2_RollingCounter5 "/";
CM_ SG_ 1425 RSDS_R_SGU2_RollingCounter6 "/";
CM_ SG_ 1425 RSDS_R_SGU2_RollingCounter7 "/";
CM_ SG_ 1425 RSDS_R_SGU2_RollingCounter8 "/";
CM_ SG_ 1426 RSDS_R_ObjID_5 "/";
CM_ SG_ 1426 RSDS_R_ObjExistProb_5 "/";
CM_ SG_ 1426 RSDS_R_ObjObstacleProb_5 "/";
CM_ SG_ 1426 RSDS_R_ObjDistX_5 "/";
CM_ SG_ 1426 RSDS_R_ObjDistY_5 "/";
CM_ SG_ 1426 RSDS_R_ObjDistXStd_5 "/";
CM_ SG_ 1426 RSDS_R_ObjType_5 "/";
CM_ SG_ 1426 RSDS_R_ObjRelVelX_5 "/";
CM_ SG_ 1426 RSDS_R_ObjRelVelY_5 "/";
CM_ SG_ 1426 RSDS_R_ObjRelAccelX_5 "/";
CM_ SG_ 1426 RSDS_R_ObjRelAccelY_5 "/";
CM_ SG_ 1426 RSDS_R_ObjMotionType_5 "/";
CM_ SG_ 1426 RSDS_R_ObjMeasured_5 "/";
CM_ SG_ 1426 RSDS_R_ObjDistYStd_5 "/";
CM_ SG_ 1426 RSDS_R_ObjRelVelXStd_5 "/";
CM_ SG_ 1426 RSDS_R_ObjRelVelYStd_5 "/";
CM_ SG_ 1426 RSDS_R_ObjRAccelXStd_5 "/";
CM_ SG_ 1426 RSDS_R_ObjRAccelYStd_5 "/";
CM_ SG_ 1426 RSDS_R_ObjWidth_5 "/";
CM_ SG_ 1426 RSDS_R_ObjMotionDirection_5 "/";
CM_ SG_ 1426 RSDS_R_ObjAge_5 "/";
CM_ SG_ 1426 RSDS_R_ObjLength_5 "/";
CM_ SG_ 1426 RSDS_R_ObjHeading_5 "/";
CM_ SG_ 1426 RSDS_R_ObjYawrate_5 "/";
CM_ SG_ 1426 RSDS_R_ObjRCS_5 "/";
CM_ SG_ 1426 RSDS_R_ObjRefPoint_5 "/";
CM_ SG_ 1426 RSDS_R_HWATargetValidity_5 "/";
CM_ SG_ 1426 RSDS_R_ObjID_6 "/";
CM_ SG_ 1426 RSDS_R_ObjExistProb_6 "/";
CM_ SG_ 1426 RSDS_R_ObjObstacleProb_6 "/";
CM_ SG_ 1426 RSDS_R_ObjDistX_6 "/";
CM_ SG_ 1426 RSDS_R_ObjDistY_6 "/";
CM_ SG_ 1426 RSDS_R_ObjDistXStd_6 "/";
CM_ SG_ 1426 RSDS_R_ObjType_6 "/";
CM_ SG_ 1426 RSDS_R_ObjRelVelX_6 "/";
CM_ SG_ 1426 RSDS_R_ObjRelVelY_6 "/";
CM_ SG_ 1426 RSDS_R_ObjRelAccelX_6 "/";
CM_ SG_ 1426 RSDS_R_ObjRelAccelY_6 "/";
CM_ SG_ 1426 RSDS_R_ObjMotionType_6 "/";
CM_ SG_ 1426 RSDS_R_ObjMeasured_6 "/";
CM_ SG_ 1426 RSDS_R_ObjDistYStd_6 "/";
CM_ SG_ 1426 RSDS_R_ObjRelVelXStd_6 "/";
CM_ SG_ 1426 RSDS_R_ObjRelVelYStd_6 "/";
CM_ SG_ 1426 RSDS_R_ObjRAccelXStd_6 "/";
CM_ SG_ 1426 RSDS_R_ObjRAccelYStd_6 "/";
CM_ SG_ 1426 RSDS_R_ObjWidth_6 "/";
CM_ SG_ 1426 RSDS_R_ObjMotionDirection_6 "/";
CM_ SG_ 1426 RSDS_R_ObjAge_6 "/";
CM_ SG_ 1426 RSDS_R_ObjLength_6 "/";
CM_ SG_ 1426 RSDS_R_ObjHeading_6 "/";
CM_ SG_ 1426 RSDS_R_ObjYawrate_6 "/";
CM_ SG_ 1426 RSDS_R_ObjRCS_6 "/";
CM_ SG_ 1426 RSDS_R_ObjRefPoint_6 "/";
CM_ SG_ 1426 RSDS_R_HWATargetValidity_6 "/";
CM_ SG_ 1426 RSDS_R_SGU3_BlockCounter "/";
CM_ SG_ 1426 RSDS_R_SGU3_Checksum1 "/";
CM_ SG_ 1426 RSDS_R_SGU3_Checksum2 "/";
CM_ SG_ 1426 RSDS_R_SGU3_Checksum3 "/";
CM_ SG_ 1426 RSDS_R_SGU3_Checksum4 "/";
CM_ SG_ 1426 RSDS_R_SGU3_Checksum5 "/";
CM_ SG_ 1426 RSDS_R_SGU3_Checksum6 "/";
CM_ SG_ 1426 RSDS_R_SGU3_Checksum7 "/";
CM_ SG_ 1426 RSDS_R_SGU3_Checksum8 "/";
CM_ SG_ 1426 RSDS_R_SGU3_RollingCounter1 "/";
CM_ SG_ 1426 RSDS_R_SGU3_RollingCounter2 "/";
CM_ SG_ 1426 RSDS_R_SGU3_RollingCounter3 "/";
CM_ SG_ 1426 RSDS_R_SGU3_RollingCounter4 "/";
CM_ SG_ 1426 RSDS_R_SGU3_RollingCounter5 "/";
CM_ SG_ 1426 RSDS_R_SGU3_RollingCounter6 "/";
CM_ SG_ 1426 RSDS_R_SGU3_RollingCounter7 "/";
CM_ SG_ 1426 RSDS_R_SGU3_RollingCounter8 "/";
CM_ SG_ 1427 RSDS_R_ObjID_7 "/";
CM_ SG_ 1427 RSDS_R_ObjExistProb_7 "/";
CM_ SG_ 1427 RSDS_R_ObjObstacleProb_7 "/";
CM_ SG_ 1427 RSDS_R_ObjDistX_7 "/";
CM_ SG_ 1427 RSDS_R_ObjDistY_7 "/";
CM_ SG_ 1427 RSDS_R_ObjDistXStd_7 "/";
CM_ SG_ 1427 RSDS_R_ObjType_7 "/";
CM_ SG_ 1427 RSDS_R_ObjRelVelX_7 "/";
CM_ SG_ 1427 RSDS_R_ObjRelVelY_7 "/";
CM_ SG_ 1427 RSDS_R_ObjRelAccelX_7 "/";
CM_ SG_ 1427 RSDS_R_ObjRelAccelY_7 "/";
CM_ SG_ 1427 RSDS_R_ObjMotionType_7 "/";
CM_ SG_ 1427 RSDS_R_ObjMeasured_7 "/";
CM_ SG_ 1427 RSDS_R_ObjDistYStd_7 "/";
CM_ SG_ 1427 RSDS_R_ObjRelVelXStd_7 "/";
CM_ SG_ 1427 RSDS_R_ObjRelVelYStd_7 "/";
CM_ SG_ 1427 RSDS_R_ObjRAccelXStd_7 "/";
CM_ SG_ 1427 RSDS_R_ObjRAccelYStd_7 "/";
CM_ SG_ 1427 RSDS_R_ObjWidth_7 "/";
CM_ SG_ 1427 RSDS_R_ObjMotionDirection_7 "/";
CM_ SG_ 1427 RSDS_R_ObjAge_7 "/";
CM_ SG_ 1427 RSDS_R_ObjLength_7 "/";
CM_ SG_ 1427 RSDS_R_ObjHeading_7 "/";
CM_ SG_ 1427 RSDS_R_ObjYawrate_7 "/";
CM_ SG_ 1427 RSDS_R_ObjRCS_7 "/";
CM_ SG_ 1427 RSDS_R_ObjRefPoint_7 "/";
CM_ SG_ 1427 RSDS_R_HWATargetValidity_7 "/";
CM_ SG_ 1427 RSDS_R_ObjID_8 "/";
CM_ SG_ 1427 RSDS_R_ObjExistProb_8 "/";
CM_ SG_ 1427 RSDS_R_ObjObstacleProb_8 "/";
CM_ SG_ 1427 RSDS_R_ObjDistX_8 "/";
CM_ SG_ 1427 RSDS_R_ObjDistY_8 "/";
CM_ SG_ 1427 RSDS_R_ObjDistXStd_8 "/";
CM_ SG_ 1427 RSDS_R_ObjType_8 "/";
CM_ SG_ 1427 RSDS_R_ObjRelVelX_8 "/";
CM_ SG_ 1427 RSDS_R_ObjRelVelY_8 "/";
CM_ SG_ 1427 RSDS_R_ObjRelAccelX_8 "/";
CM_ SG_ 1427 RSDS_R_ObjRelAccelY_8 "/";
CM_ SG_ 1427 RSDS_R_ObjMotionType_8 "/";
CM_ SG_ 1427 RSDS_R_ObjMeasured_8 "/";
CM_ SG_ 1427 RSDS_R_ObjDistYStd_8 "/";
CM_ SG_ 1427 RSDS_R_ObjRelVelXStd_8 "/";
CM_ SG_ 1427 RSDS_R_ObjRelVelYStd_8 "/";
CM_ SG_ 1427 RSDS_R_ObjRAccelXStd_8 "/";
CM_ SG_ 1427 RSDS_R_ObjRAccelYStd_8 "/";
CM_ SG_ 1427 RSDS_R_ObjWidth_8 "/";
CM_ SG_ 1427 RSDS_R_ObjMotionDirection_8 "/";
CM_ SG_ 1427 RSDS_R_ObjAge_8 "/";
CM_ SG_ 1427 RSDS_R_ObjLength_8 "/";
CM_ SG_ 1427 RSDS_R_ObjHeading_8 "/";
CM_ SG_ 1427 RSDS_R_ObjYawrate_8 "/";
CM_ SG_ 1427 RSDS_R_ObjRCS_8 "/";
CM_ SG_ 1427 RSDS_R_ObjRefPoint_8 "/";
CM_ SG_ 1427 RSDS_R_HWATargetValidity_8 "/";
CM_ SG_ 1427 RSDS_R_SGU4_BlockCounter "/";
CM_ SG_ 1427 RSDS_R_SGU4_Checksum1 "/";
CM_ SG_ 1427 RSDS_R_SGU4_Checksum2 "/";
CM_ SG_ 1427 RSDS_R_SGU4_Checksum3 "/";
CM_ SG_ 1427 RSDS_R_SGU4_Checksum4 "/";
CM_ SG_ 1427 RSDS_R_SGU4_Checksum5 "/";
CM_ SG_ 1427 RSDS_R_SGU4_Checksum6 "/";
CM_ SG_ 1427 RSDS_R_SGU4_Checksum7 "/";
CM_ SG_ 1427 RSDS_R_SGU4_Checksum8 "/";
CM_ SG_ 1427 RSDS_R_SGU4_RollingCounter1 "/";
CM_ SG_ 1427 RSDS_R_SGU4_RollingCounter2 "/";
CM_ SG_ 1427 RSDS_R_SGU4_RollingCounter3 "/";
CM_ SG_ 1427 RSDS_R_SGU4_RollingCounter4 "/";
CM_ SG_ 1427 RSDS_R_SGU4_RollingCounter5 "/";
CM_ SG_ 1427 RSDS_R_SGU4_RollingCounter6 "/";
CM_ SG_ 1427 RSDS_R_SGU4_RollingCounter7 "/";
CM_ SG_ 1427 RSDS_R_SGU4_RollingCounter8 "/";
BA_DEF_ BO_  "CANFD_BRS" ENUM  "0","1";
BA_DEF_ BO_  "DiagState" ENUM  "No","Yes";
BA_DEF_ BO_  "GenMsgCycleTime" INT 0 65535;
BA_DEF_ BO_  "GenMsgILSupport" ENUM  "No","Yes";
BA_DEF_ BO_  "GenMsgMinAcceptLength" INT 0 8;
BA_DEF_ BO_  "GenMsgSendType" ENUM  "Cyclic","CyclicAndSpontanX","Event";
BA_DEF_ BO_  "NmMessage" ENUM  "no","yes";
BA_DEF_ BO_  "VFrameFormat" ENUM  "StandardCAN","ExtendedCAN","reserved","reserved","reserved","reserved","reserved","reserved","reserved","reserved","reserved","reserved","reserved","reserved","StandardCAN_FD","ExtendedCAN_FD";
BA_DEF_ SG_  "GenSigEnvVarType" ENUM  "undef","int","float";
BA_DEF_ SG_  "GenSigSendType" ENUM  "Cyclic","OnWrite","OnWriteWithRepetition","OnChange","OnChangeWithRepetition","IfActive","IfActiveWithRepetition","NoSigSendType","NotUsed","NotUsed","NotUsed","NotUsed","NotUsed";
BA_DEF_ SG_  "GenSigStartValue" FLOAT 0 1215752192;
BA_DEF_ BU_  "ILUsed" ENUM  "No","Yes";
BA_DEF_ BU_  "NmCAN" INT 0 2;
BA_DEF_ BU_  "NodeLayerModules" STRING ;
BA_DEF_  "BusType" STRING ;
BA_DEF_  "DBName" STRING ;
BA_DEF_  "GenEnvVarEndingDsp" STRING ;
BA_DEF_  "GenEnvVarEndingSnd" STRING ;
BA_DEF_  "GenEnvVarPrefix" STRING ;
BA_DEF_  "GenNWMApBusSleep" STRING ;
BA_DEF_  "GenNWMApCanNormal" STRING ;
BA_DEF_  "GenNWMApCanOff" STRING ;
BA_DEF_  "GenNWMApCanOn" STRING ;
BA_DEF_  "GenNWMApCanSleep" STRING ;
BA_DEF_  "GenNWMApCanWakeUp" STRING ;
BA_DEF_  "GenNWMGotoMode_Awake" STRING ;
BA_DEF_  "GenNWMGotoMode_BusSleep" STRING ;
BA_DEF_  "GenNWMTalkNM" STRING ;
BA_DEF_  "Manufacturer" STRING ;
BA_DEF_  "NmBaseAddress" HEX 1152 1279;
BA_DEF_DEF_  "CANFD_BRS" "1";
BA_DEF_DEF_  "DiagState" "No";
BA_DEF_DEF_  "GenMsgCycleTime" 10;
BA_DEF_DEF_  "GenMsgILSupport" "Yes";
BA_DEF_DEF_  "GenMsgMinAcceptLength" 8;
BA_DEF_DEF_  "GenMsgSendType" "Cyclic";
BA_DEF_DEF_  "NmMessage" "no";
BA_DEF_DEF_  "VFrameFormat" "StandardCAN";
BA_DEF_DEF_  "GenSigEnvVarType" "undef";
BA_DEF_DEF_  "GenSigSendType" "Cyclic";
BA_DEF_DEF_  "GenSigStartValue" 0;
BA_DEF_DEF_  "ILUsed" "Yes";
BA_DEF_DEF_  "NmCAN" 1;
BA_DEF_DEF_  "NodeLayerModules" "CANoeILNLVector.dll";
BA_DEF_DEF_  "BusType" "";
BA_DEF_DEF_  "DBName" "V71_L3_001_021MM01 C_Matrix for  ADAS_CANFD_V2_0";
BA_DEF_DEF_  "GenEnvVarEndingDsp" "_d";
BA_DEF_DEF_  "GenEnvVarEndingSnd" "_s";
BA_DEF_DEF_  "GenEnvVarPrefix" "c";
BA_DEF_DEF_  "GenNWMApBusSleep" "apBusSleep()";
BA_DEF_DEF_  "GenNWMApCanNormal" "apCanNormal()";
BA_DEF_DEF_  "GenNWMApCanOff" "apCanOff()";
BA_DEF_DEF_  "GenNWMApCanOn" "apCanOn()";
BA_DEF_DEF_  "GenNWMApCanSleep" "apCanSleep()";
BA_DEF_DEF_  "GenNWMApCanWakeUp" "apCanWakeUp()";
BA_DEF_DEF_  "GenNWMGotoMode_Awake" "GotoMode_Awake()";
BA_DEF_DEF_  "GenNWMGotoMode_BusSleep" "GotoMode_BusSleep()";
BA_DEF_DEF_  "GenNWMTalkNM" "TalkNM()";
BA_DEF_DEF_  "Manufacturer" "GWM";
BA_DEF_DEF_  "NmBaseAddress" 1152;
BA_ "BusType" "CAN FD";
BA_ "DBName" "V71_L3_001_021MM01C_MatrixforADA";
BA_ "GenMsgCycleTime" BO_ 395 20;
BA_ "VFrameFormat" BO_ 395 14;
BA_ "VFrameFormat" BO_ 147 14;
BA_ "GenMsgCycleTime" BO_ 303 20;
BA_ "VFrameFormat" BO_ 303 14;
BA_ "GenMsgCycleTime" BO_ 350 20;
BA_ "VFrameFormat" BO_ 350 14;
BA_ "GenMsgCycleTime" BO_ 846 500;
BA_ "VFrameFormat" BO_ 846 14;
BA_ "GenMsgCycleTime" BO_ 323 20;
BA_ "VFrameFormat" BO_ 323 14;
BA_ "VFrameFormat" BO_ 121 14;
BA_ "GenMsgCycleTime" BO_ 259 20;
BA_ "VFrameFormat" BO_ 259 14;
BA_ "VFrameFormat" BO_ 273 14;
BA_ "GenMsgCycleTime" BO_ 545 20;
BA_ "VFrameFormat" BO_ 545 14;
BA_ "GenMsgCycleTime" BO_ 311 20;
BA_ "VFrameFormat" BO_ 311 14;
BA_ "GenMsgCycleTime" BO_ 315 20;
BA_ "VFrameFormat" BO_ 315 14;
BA_ "GenMsgCycleTime" BO_ 793 50;
BA_ "VFrameFormat" BO_ 793 14;
BA_ "GenMsgCycleTime" BO_ 671 100;
BA_ "VFrameFormat" BO_ 671 14;
BA_ "GenMsgCycleTime" BO_ 661 50;
BA_ "VFrameFormat" BO_ 661 14;
BA_ "GenMsgCycleTime" BO_ 627 50;
BA_ "VFrameFormat" BO_ 627 14;
BA_ "GenMsgCycleTime" BO_ 357 20;
BA_ "VFrameFormat" BO_ 357 14;
BA_ "VFrameFormat" BO_ 161 14;
BA_ "GenMsgCycleTime" BO_ 714 100;
BA_ "VFrameFormat" BO_ 714 14;
BA_ "GenMsgCycleTime" BO_ 717 100;
BA_ "VFrameFormat" BO_ 717 14;
BA_ "GenMsgCycleTime" BO_ 581 20;
BA_ "VFrameFormat" BO_ 581 14;
BA_ "GenMsgCycleTime" BO_ 639 50;
BA_ "VFrameFormat" BO_ 639 14;
BA_ "GenMsgCycleTime" BO_ 707 100;
BA_ "VFrameFormat" BO_ 707 14;
BA_ "GenMsgCycleTime" BO_ 258 20;
BA_ "VFrameFormat" BO_ 258 14;
BA_ "GenMsgCycleTime" BO_ 625 20;
BA_ "VFrameFormat" BO_ 625 14;
BA_ "GenMsgCycleTime" BO_ 561 20;
BA_ "VFrameFormat" BO_ 561 14;
BA_ "GenMsgCycleTime" BO_ 582 20;
BA_ "VFrameFormat" BO_ 582 14;
BA_ "GenMsgCycleTime" BO_ 613 20;
BA_ "VFrameFormat" BO_ 613 14;
BA_ "GenMsgCycleTime" BO_ 363 20;
BA_ "VFrameFormat" BO_ 363 14;
BA_ "GenMsgCycleTime" BO_ 329 20;
BA_ "VFrameFormat" BO_ 329 14;
BA_ "GenMsgCycleTime" BO_ 325 20;
BA_ "VFrameFormat" BO_ 325 14;
BA_ "VFrameFormat" BO_ 96 14;
BA_ "GenMsgCycleTime" BO_ 288 20;
BA_ "VFrameFormat" BO_ 288 14;
BA_ "VFrameFormat" BO_ 174 14;
BA_ "GenMsgCycleTime" BO_ 537 50;
BA_ "VFrameFormat" BO_ 537 14;
BA_ "NmMessage" BO_ 1305 1;
BA_ "GenMsgSendType" BO_ 1305 2;
BA_ "GenMsgCycleTime" BO_ 1305 0;
BA_ "NmMessage" BO_ 1308 1;
BA_ "GenMsgSendType" BO_ 1308 2;
BA_ "GenMsgCycleTime" BO_ 1308 0;
BA_ "NmMessage" BO_ 1309 1;
BA_ "GenMsgSendType" BO_ 1309 2;
BA_ "GenMsgCycleTime" BO_ 1309 0;
BA_ "NmMessage" BO_ 1310 1;
BA_ "GenMsgSendType" BO_ 1310 2;
BA_ "GenMsgCycleTime" BO_ 1310 0;
BA_ "NmMessage" BO_ 1311 1;
BA_ "GenMsgSendType" BO_ 1311 2;
BA_ "GenMsgCycleTime" BO_ 1311 0;
BA_ "NmMessage" BO_ 1281 1;
BA_ "GenMsgSendType" BO_ 1281 2;
BA_ "GenMsgCycleTime" BO_ 1281 0;
BA_ "GenMsgCycleTime" BO_ 301 20;
BA_ "VFrameFormat" BO_ 301 14;
BA_ "GenMsgCycleTime" BO_ 1136 500;
BA_ "VFrameFormat" BO_ 1136 14;
BA_ "GenMsgCycleTime" BO_ 778 200;
BA_ "VFrameFormat" BO_ 778 14;
BA_ "GenMsgCycleTime" BO_ 367 20;
BA_ "VFrameFormat" BO_ 367 14;
BA_ "GenMsgCycleTime" BO_ 880 1000;
BA_ "VFrameFormat" BO_ 880 14;
BA_ "GenMsgCycleTime" BO_ 302 20;
BA_ "VFrameFormat" BO_ 302 14;
BA_ "VFrameFormat" BO_ 181 14;
BA_ "GenMsgSendType" BO_ 1091 2;
BA_ "GenMsgCycleTime" BO_ 1091 0;
BA_ "VFrameFormat" BO_ 1091 14;
BA_ "GenMsgSendType" BO_ 1092 2;
BA_ "GenMsgCycleTime" BO_ 1092 0;
BA_ "VFrameFormat" BO_ 1092 14;
BA_ "GenMsgSendType" BO_ 1093 2;
BA_ "GenMsgCycleTime" BO_ 1093 0;
BA_ "VFrameFormat" BO_ 1093 14;
BA_ "GenMsgSendType" BO_ 1424 2;
BA_ "GenMsgCycleTime" BO_ 1424 0;
BA_ "VFrameFormat" BO_ 1424 14;
BA_ "GenMsgSendType" BO_ 1425 2;
BA_ "GenMsgCycleTime" BO_ 1425 0;
BA_ "VFrameFormat" BO_ 1425 14;
BA_ "GenMsgSendType" BO_ 1426 2;
BA_ "GenMsgCycleTime" BO_ 1426 0;
BA_ "VFrameFormat" BO_ 1426 14;
BA_ "GenMsgSendType" BO_ 1427 2;
BA_ "GenMsgCycleTime" BO_ 1427 0;
BA_ "VFrameFormat" BO_ 1427 14;
BA_ "GenMsgCycleTime" BO_ 629 50;
BA_  "VFrameFormat" BO_ 629 14;
BA_ "GenSigStartValue" SG_ 303 HCU_GearSts 14;
BA_ "GenSigStartValue" SG_ 350 CR_ObjSts_Le 2;
BA_ "GenSigStartValue" SG_ 350 CR_ObjDistY_Le 128;
BA_ "GenSigStartValue" SG_ 350 CR_ObjRelAccelX_Le 512;
BA_ "GenSigStartValue" SG_ 350 CR_ObjSts_Ri 2;
BA_ "GenSigStartValue" SG_ 350 CR_ObjDistY_Ri 128;
BA_ "GenSigStartValue" SG_ 350 CR_ObjRelAccelX_Ri 512;
BA_ "GenSigStartValue" SG_ 350 CR_ObjRelAccelY_Ri 512;
BA_ "GenSigStartValue" SG_ 350 CR_ObjRelVelY_Ri 64;
BA_ "GenSigStartValue" SG_ 350 CR_ObjRelAccelY_Le 512;
BA_ "GenSigStartValue" SG_ 350 CR_ObjRelVelY_Le 64;
BA_ "GenSigStartValue" SG_ 121 EngSpdVldty_0x079 2;
BA_ "GenSigStartValue" SG_ 259 AccelPedalPosnVldty_0x103 2;
BA_ "GenSigStartValue" SG_ 273 EngSpdVldty 2;
BA_ "GenSigStartValue" SG_ 545 TGS_LEVER 14;
BA_ "GenSigStartValue" SG_ 311 ESP_MasterCylBrkPressVld_0x137 1;
BA_ "GenSigStartValue" SG_ 581 VehLgtAccel 22033;
BA_ "GenSigStartValue" SG_ 581 VehLatAccel 22033;
BA_ "GenSigStartValue" SG_ 581 VehYawRate 8721;
BA_ "GenSigStartValue" SG_ 625 AccelPedalPosnVldty 2;
BA_ "GenSigStartValue" SG_ 329 ESP_MasterCylBrkPressVld 1;
BA_ "GenSigStartValue" SG_ 96 HCU_AccelPedalPosn_DiagValid 1;
BA_ "GenSigStartValue" SG_ 174 MCU_ActRotSpd 20000;
BA_ "GenSigSendType" SG_ 1305 Destination_HC_NM 8;
BA_ "GenSigSendType" SG_ 1305 OpCode_HC_NM 8;
BA_ "GenSigSendType" SG_ 1308 Destination_IDC_L3_NM 8;
BA_ "GenSigSendType" SG_ 1308 OpCode_IDC_L3_NM 8;
BA_ "GenSigSendType" SG_ 1309 Destination_RRR_NM 8;
BA_ "GenSigSendType" SG_ 1309 OpCode_RRR_NM 8;
BA_ "GenSigSendType" SG_ 1310 Destination_SRR_L_NM 8;
BA_ "GenSigSendType" SG_ 1310 OpCode_SRR_L_NM 8;
BA_ "GenSigSendType" SG_ 1311 Destination_SRR_R_NM 8;
BA_ "GenSigSendType" SG_ 1311 OpCode_SRR_R_NM 8;
BA_ "GenSigSendType" SG_ 1281 Destination_GW_NM 8;
BA_ "GenSigSendType" SG_ 1281 OpCode_GW_NM 8;
BA_ "GenSigStartValue" SG_ 778 LCA_LeTgt_01_Vx 1;
BA_ "GenSigStartValue" SG_ 778 RCTA_LeTgt_02_Vx 1;
BA_ "GenSigStartValue" SG_ 778 LCA_RiTgt_01_Vx 1;
BA_ "GenSigStartValue" SG_ 778 RCTA_RiTgt_02_Vx 1;
BA_ "GenSigStartValue" SG_ 778 RCW_MidTgt_01_Vx 1;
BA_ "GenSigStartValue" SG_ 778 RCTB_MidTgt_02_Vx 1;
BA_ "GenSigStartValue" SG_ 778 LCA_LeTgt_01_Vy 1;
BA_ "GenSigStartValue" SG_ 778 RCTA_LeTgt_02_Vy 1;
BA_ "GenSigStartValue" SG_ 778 LCA_RiTgt_01_Vy 1;
BA_ "GenSigStartValue" SG_ 778 RCTA_RiTgt_02_Vy 1;
BA_ "GenSigStartValue" SG_ 778 RCW_MidTgt_01_Vy 1;
BA_ "GenSigStartValue" SG_ 778 RCTB_MidTgt_02_Vy 1;
BA_ "GenSigStartValue" SG_ 367 RSDS_ObjRelAccelY_Le 512;
BA_ "GenSigStartValue" SG_ 367 RSDS_BrkgReqVal 200;
BA_ "GenSigStartValue" SG_ 367 LeTarSts 2;
BA_ "GenSigStartValue" SG_ 367 ObjLatPosnCurvLe 128;
BA_ "GenSigStartValue" SG_ 367 ObjLatSpdCurvLe 64;
BA_ "GenSigStartValue" SG_ 367 ObjTTCLe 127;
BA_ "GenSigStartValue" SG_ 367 RiTarSts 2;
BA_ "GenSigStartValue" SG_ 367 ObjLatPosnCurvRi 128;
BA_ "GenSigStartValue" SG_ 367 ObjLatSpdCurvRi 64;
BA_ "GenSigStartValue" SG_ 367 ObjTTCRi 127;
BA_ "GenSigStartValue" SG_ 367 RSDS_ObjRelAccelX_Le 512;
BA_ "GenSigStartValue" SG_ 367 RSDS_ObjRelAccelX_Ri 512;
BA_ "GenSigStartValue" SG_ 367 RSDS_ObjRelAccelY_Ri 512;
BA_ "GenSigStartValue" SG_ 880 Time_Hour 31;
BA_ "GenSigStartValue" SG_ 880 Time_Minutes 63;
BA_ "GenSigStartValue" SG_ 880 Time_Second 63;
BA_ "GenSigStartValue" SG_ 880 Time_Year_Right 15;
BA_ "GenSigStartValue" SG_ 880 Time_Year_Left 15;
BA_ "GenSigSendType" SG_ 1091 RSDS_R_hdr_ErrorStatus 8;
BA_ "GenSigSendType" SG_ 1091 RSDS_R_hdr_TimeStamp 8;
BA_ "GenSigSendType" SG_ 1091 RSDS_R_ObjID_1 8;
BA_ "GenSigSendType" SG_ 1091 RSDS_R_ObjExistProb_1 8;
BA_ "GenSigSendType" SG_ 1091 RSDS_R_ObjObstacleProb_1 8;
BA_ "GenSigSendType" SG_ 1091 RSDS_R_ObjDistX_1 8;
BA_ "GenSigStartValue" SG_ 1091 RSDS_R_ObjDistY_1 1024;
BA_ "GenSigSendType" SG_ 1091 RSDS_R_ObjDistY_1 8;
BA_ "GenSigStartValue" SG_ 1091 RSDS_R_ObjRelVelX_1 4102;
BA_ "GenSigSendType" SG_ 1091 RSDS_R_ObjRelVelX_1 8;
BA_ "GenSigStartValue" SG_ 1091 RSDS_R_ObjRelVelY_1 4102;
BA_ "GenSigSendType" SG_ 1091 RSDS_R_ObjRelVelY_1 8;
BA_ "GenSigStartValue" SG_ 1091 RSDS_R_ObjRelAccelX_1 512;
BA_ "GenSigSendType" SG_ 1091 RSDS_R_ObjRelAccelX_1 8;
BA_ "GenSigStartValue" SG_ 1091 RSDS_R_ObjRelAccelY_1 512;
BA_ "GenSigSendType" SG_ 1091 RSDS_R_ObjRelAccelY_1 8;
BA_ "GenSigSendType" SG_ 1091 RSDS_R_ObjDistXStd_1 8;
BA_ "GenSigSendType" SG_ 1091 RSDS_R_ObjDistYStd_1 8;
BA_ "GenSigSendType" SG_ 1091 RSDS_R_ObjRelVelXStd_1 8;
BA_ "GenSigSendType" SG_ 1091 RSDS_R_ObjRelVelYStd_1 8;
BA_ "GenSigSendType" SG_ 1091 RSDS_R_ObjRAccelXStd_1 8;
BA_ "GenSigSendType" SG_ 1091 RSDS_R_ObjRAccelYStd_1 8;
BA_ "GenSigSendType" SG_ 1091 RSDS_R_VFC_ObjWidth_1 8;
BA_ "GenSigSendType" SG_ 1091 RSDS_R_VFC_ObjLength_1 8;
BA_ "GenSigSendType" SG_ 1091 RSDS_R_ObjID_2 8;
BA_ "GenSigSendType" SG_ 1091 RSDS_R_ObjExistProb_2 8;
BA_ "GenSigSendType" SG_ 1091 RSDS_R_ObjObstacleProb_2 8;
BA_ "GenSigSendType" SG_ 1091 RSDS_R_ObjDistX_2 8;
BA_ "GenSigStartValue" SG_ 1091 RSDS_R_ObjDistY_2 1024;
BA_ "GenSigSendType" SG_ 1091 RSDS_R_ObjDistY_2 8;
BA_ "GenSigStartValue" SG_ 1091 RSDS_R_ObjRelVelX_2 4102;
BA_ "GenSigSendType" SG_ 1091 RSDS_R_ObjRelVelX_2 8;
BA_ "GenSigStartValue" SG_ 1091 RSDS_R_ObjRelVelY_2 4102;
BA_ "GenSigSendType" SG_ 1091 RSDS_R_ObjRelVelY_2 8;
BA_ "GenSigStartValue" SG_ 1091 RSDS_R_ObjRelAccelX_2 512;
BA_ "GenSigSendType" SG_ 1091 RSDS_R_ObjRelAccelX_2 8;
BA_ "GenSigStartValue" SG_ 1091 RSDS_R_ObjRelAccelY_2 512;
BA_ "GenSigSendType" SG_ 1091 RSDS_R_ObjRelAccelY_2 8;
BA_ "GenSigSendType" SG_ 1091 RSDS_R_ObjDistXStd_2 8;
BA_ "GenSigSendType" SG_ 1091 RSDS_R_ObjDistYStd_2 8;
BA_ "GenSigSendType" SG_ 1091 RSDS_R_ObjRelVelXStd_2 8;
BA_ "GenSigSendType" SG_ 1091 RSDS_R_ObjRelVelYStd_2 8;
BA_ "GenSigSendType" SG_ 1091 RSDS_R_ObjRAccelXStd_2 8;
BA_ "GenSigSendType" SG_ 1091 RSDS_R_ObjRAccelYStd_2 8;
BA_ "GenSigSendType" SG_ 1091 RSDS_R_VFC_ObjWidth_2 8;
BA_ "GenSigSendType" SG_ 1091 RSDS_R_VFC_ObjLength_2 8;
BA_ "GenSigSendType" SG_ 1091 Checksum22 8;
BA_ "GenSigSendType" SG_ 1091 Checksum23 8;
BA_ "GenSigSendType" SG_ 1091 Checksum24 8;
BA_ "GenSigSendType" SG_ 1091 Checksum26 8;
BA_ "GenSigSendType" SG_ 1091 Checksum27 8;
BA_ "GenSigSendType" SG_ 1091 Checksum28 8;
BA_ "GenSigSendType" SG_ 1091 RollingCounter22 8;
BA_ "GenSigSendType" SG_ 1091 RollingCounter23 8;
BA_ "GenSigSendType" SG_ 1091 RollingCounter24 8;
BA_ "GenSigSendType" SG_ 1091 RollingCounter26 8;
BA_ "GenSigSendType" SG_ 1091 RollingCounter27 8;
BA_ "GenSigSendType" SG_ 1091 RollingCounter28 8;
BA_ "GenSigSendType" SG_ 1091 RSDS_R_ObjMeasured_1 8;
BA_ "GenSigSendType" SG_ 1091 RSDS_R_ObjMeasured_2 8;
BA_ "GenSigSendType" SG_ 1091 RSDS_R_BLIND 8;
BA_ "GenSigSendType" SG_ 1091 RSDS_R_hdr_TimerStempStatus 8;
BA_ "GenSigSendType" SG_ 1091 Checksum25 8;
BA_ "GenSigSendType" SG_ 1091 Rollingcounter25 8;
BA_ "GenSigSendType" SG_ 1091 BlockCounter4 8;
BA_ "GenSigSendType" SG_ 1091 RSDS_R_hdr_AutosarTimeStamp 8;
BA_ "GenSigSendType" SG_ 1092 RSDS_R_ObjID_3 8;
BA_ "GenSigSendType" SG_ 1092 RSDS_R_ObjExistProb_3 8;
BA_ "GenSigSendType" SG_ 1092 RSDS_R_ObjObstacleProb_3 8;
BA_ "GenSigSendType" SG_ 1092 RSDS_R_ObjDistX_3 8;
BA_ "GenSigStartValue" SG_ 1092 RSDS_R_ObjDistY_3 1024;
BA_ "GenSigSendType" SG_ 1092 RSDS_R_ObjDistY_3 8;
BA_ "GenSigStartValue" SG_ 1092 RSDS_R_ObjRelVelX_3 4102;
BA_ "GenSigSendType" SG_ 1092 RSDS_R_ObjRelVelX_3 8;
BA_ "GenSigStartValue" SG_ 1092 RSDS_R_ObjRelVelY_3 4102;
BA_ "GenSigSendType" SG_ 1092 RSDS_R_ObjRelVelY_3 8;
BA_ "GenSigStartValue" SG_ 1092 RSDS_R_ObjRelAccelX_3 512;
BA_ "GenSigSendType" SG_ 1092 RSDS_R_ObjRelAccelX_3 8;
BA_ "GenSigStartValue" SG_ 1092 RSDS_R_ObjRelAccelY_3 512;
BA_ "GenSigSendType" SG_ 1092 RSDS_R_ObjRelAccelY_3 8;
BA_ "GenSigSendType" SG_ 1092 RSDS_R_ObjDistXStd_3 8;
BA_ "GenSigSendType" SG_ 1092 RSDS_R_ObjDistYStd_3 8;
BA_ "GenSigSendType" SG_ 1092 RSDS_R_ObjRelVelXStd_3 8;
BA_ "GenSigSendType" SG_ 1092 RSDS_R_ObjRelVelYStd_3 8;
BA_ "GenSigSendType" SG_ 1092 RSDS_R_ObjRAccelXStd_3 8;
BA_ "GenSigSendType" SG_ 1092 RSDS_R_ObjRAccelYStd_3 8;
BA_ "GenSigSendType" SG_ 1092 RSDS_R_VFC_ObjWidth_3 8;
BA_ "GenSigSendType" SG_ 1092 RSDS_R_VFC_ObjLength_3 8;
BA_ "GenSigSendType" SG_ 1092 RSDS_R_ObjID_4 8;
BA_ "GenSigSendType" SG_ 1092 RSDS_R_ObjExistProb_4 8;
BA_ "GenSigSendType" SG_ 1092 RSDS_R_ObjObstacleProb_4 8;
BA_ "GenSigSendType" SG_ 1092 RSDS_R_ObjDistX_4 8;
BA_ "GenSigStartValue" SG_ 1092 RSDS_R_ObjDistY_4 1024;
BA_ "GenSigSendType" SG_ 1092 RSDS_R_ObjDistY_4 8;
BA_ "GenSigStartValue" SG_ 1092 RSDS_R_ObjRelVelX_4 4102;
BA_ "GenSigSendType" SG_ 1092 RSDS_R_ObjRelVelX_4 8;
BA_ "GenSigStartValue" SG_ 1092 RSDS_R_ObjRelVelY_4 4102;
BA_ "GenSigSendType" SG_ 1092 RSDS_R_ObjRelVelY_4 8;
BA_ "GenSigStartValue" SG_ 1092 RSDS_R_ObjRelAccelX_4 512;
BA_ "GenSigSendType" SG_ 1092 RSDS_R_ObjRelAccelX_4 8;
BA_ "GenSigStartValue" SG_ 1092 RSDS_R_ObjRelAccelY_4 512;
BA_ "GenSigSendType" SG_ 1092 RSDS_R_ObjRelAccelY_4 8;
BA_ "GenSigSendType" SG_ 1092 RSDS_R_ObjDistXStd_4 8;
BA_ "GenSigSendType" SG_ 1092 RSDS_R_ObjDistYStd_4 8;
BA_ "GenSigSendType" SG_ 1092 RSDS_R_ObjRelVelXStd_4 8;
BA_ "GenSigSendType" SG_ 1092 RSDS_R_ObjRelVelYStd_4 8;
BA_ "GenSigSendType" SG_ 1092 RSDS_R_ObjRAccelXStd_4 8;
BA_ "GenSigSendType" SG_ 1092 RSDS_R_ObjRAccelYStd_4 8;
BA_ "GenSigSendType" SG_ 1092 RSDS_R_VFC_ObjWidth_4 8;
BA_ "GenSigSendType" SG_ 1092 RSDS_R_VFC_ObjLength_4 8;
BA_ "GenSigSendType" SG_ 1092 Checksum29 8;
BA_ "GenSigSendType" SG_ 1092 Checksum30 8;
BA_ "GenSigSendType" SG_ 1092 Checksum31 8;
BA_ "GenSigSendType" SG_ 1092 Checksum33 8;
BA_ "GenSigSendType" SG_ 1092 Checksum34 8;
BA_ "GenSigSendType" SG_ 1092 Checksum35 8;
BA_ "GenSigSendType" SG_ 1092 RollingCounter29 8;
BA_ "GenSigSendType" SG_ 1092 RollingCounter30 8;
BA_ "GenSigSendType" SG_ 1092 RollingCounter31 8;
BA_ "GenSigSendType" SG_ 1092 RollingCounter33 8;
BA_ "GenSigSendType" SG_ 1092 RollingCounter34 8;
BA_ "GenSigSendType" SG_ 1092 RollingCounter35 8;
BA_ "GenSigSendType" SG_ 1092 RSDS_R_ObjMeasured_3 8;
BA_ "GenSigSendType" SG_ 1092 RSDS_R_ObjMeasured_4 8;
BA_ "GenSigSendType" SG_ 1092 Checksum32 8;
BA_ "GenSigSendType" SG_ 1092 Rollingcounter32 8;
BA_ "GenSigSendType" SG_ 1092 BlockCounter5 8;
BA_ "GenSigSendType" SG_ 1093 RSDS_R_ObjID_5 8;
BA_ "GenSigSendType" SG_ 1093 RSDS_R_ObjExistProb_5 8;
BA_ "GenSigSendType" SG_ 1093 RSDS_R_ObjObstacleProb_5 8;
BA_ "GenSigSendType" SG_ 1093 RSDS_R_ObjDistX_5 8;
BA_ "GenSigStartValue" SG_ 1093 RSDS_R_ObjDistY_5 1024;
BA_ "GenSigSendType" SG_ 1093 RSDS_R_ObjDistY_5 8;
BA_ "GenSigStartValue" SG_ 1093 RSDS_R_ObjRelVelX_5 4102;
BA_ "GenSigSendType" SG_ 1093 RSDS_R_ObjRelVelX_5 8;
BA_ "GenSigStartValue" SG_ 1093 RSDS_R_ObjRelVelY_5 4102;
BA_ "GenSigSendType" SG_ 1093 RSDS_R_ObjRelVelY_5 8;
BA_ "GenSigStartValue" SG_ 1093 RSDS_R_ObjRelAccelX_5 512;
BA_ "GenSigSendType" SG_ 1093 RSDS_R_ObjRelAccelX_5 8;
BA_ "GenSigStartValue" SG_ 1093 RSDS_R_ObjRelAccelY_5 512;
BA_ "GenSigSendType" SG_ 1093 RSDS_R_ObjRelAccelY_5 8;
BA_ "GenSigSendType" SG_ 1093 RSDS_R_ObjDistXStd_5 8;
BA_ "GenSigSendType" SG_ 1093 RSDS_R_ObjDistYStd_5 8;
BA_ "GenSigSendType" SG_ 1093 RSDS_R_ObjRelVelXStd_5 8;
BA_ "GenSigSendType" SG_ 1093 RSDS_R_ObjRelVelYStd_5 8;
BA_ "GenSigSendType" SG_ 1093 RSDS_R_ObjRAccelXStd_5 8;
BA_ "GenSigSendType" SG_ 1093 RSDS_R_ObjRAccelYStd_5 8;
BA_ "GenSigSendType" SG_ 1093 RSDS_R_VFC_ObjWidth_5 8;
BA_ "GenSigSendType" SG_ 1093 RSDS_R_VFC_ObjLength_5 8;
BA_ "GenSigSendType" SG_ 1093 RSDS_R_ObjID_6 8;
BA_ "GenSigSendType" SG_ 1093 RSDS_R_ObjExistProb_6 8;
BA_ "GenSigSendType" SG_ 1093 RSDS_R_ObjObstacleProb_6 8;
BA_ "GenSigSendType" SG_ 1093 RSDS_R_ObjDistX_6 8;
BA_ "GenSigStartValue" SG_ 1093 RSDS_R_ObjDistY_6 1024;
BA_ "GenSigSendType" SG_ 1093 RSDS_R_ObjDistY_6 8;
BA_ "GenSigStartValue" SG_ 1093 RSDS_R_ObjRelVelX_6 4102;
BA_ "GenSigSendType" SG_ 1093 RSDS_R_ObjRelVelX_6 8;
BA_ "GenSigStartValue" SG_ 1093 RSDS_R_ObjRelVelY_6 4102;
BA_ "GenSigSendType" SG_ 1093 RSDS_R_ObjRelVelY_6 8;
BA_ "GenSigStartValue" SG_ 1093 RSDS_R_ObjRelAccelX_6 512;
BA_ "GenSigSendType" SG_ 1093 RSDS_R_ObjRelAccelX_6 8;
BA_ "GenSigStartValue" SG_ 1093 RSDS_R_ObjRelAccelY_6 512;
BA_ "GenSigSendType" SG_ 1093 RSDS_R_ObjRelAccelY_6 8;
BA_ "GenSigSendType" SG_ 1093 RSDS_R_ObjDistXStd_6 8;
BA_ "GenSigSendType" SG_ 1093 RSDS_R_ObjDistYStd_6 8;
BA_ "GenSigSendType" SG_ 1093 RSDS_R_ObjRelVelXStd_6 8;
BA_ "GenSigSendType" SG_ 1093 RSDS_R_ObjRelVelYStd_6 8;
BA_ "GenSigSendType" SG_ 1093 RSDS_R_ObjRAccelXStd_6 8;
BA_ "GenSigSendType" SG_ 1093 RSDS_R_ObjRAccelYStd_6 8;
BA_ "GenSigSendType" SG_ 1093 RSDS_R_VFC_ObjWidth_6 8;
BA_ "GenSigSendType" SG_ 1093 RSDS_R_VFC_ObjLength_6 8;
BA_ "GenSigSendType" SG_ 1093 Checksum36 8;
BA_ "GenSigSendType" SG_ 1093 Checksum37 8;
BA_ "GenSigSendType" SG_ 1093 Checksum38 8;
BA_ "GenSigSendType" SG_ 1093 Checksum40 8;
BA_ "GenSigSendType" SG_ 1093 Checksum41 8;
BA_ "GenSigSendType" SG_ 1093 Checksum42 8;
BA_ "GenSigSendType" SG_ 1093 RollingCounter36 8;
BA_ "GenSigSendType" SG_ 1093 RollingCounter37 8;
BA_ "GenSigSendType" SG_ 1093 RollingCounter38 8;
BA_ "GenSigSendType" SG_ 1093 RollingCounter40 8;
BA_ "GenSigSendType" SG_ 1093 RollingCounter41 8;
BA_ "GenSigSendType" SG_ 1093 RollingCounter42 8;
BA_ "GenSigSendType" SG_ 1093 RSDS_R_ObjMeasured_5 8;
BA_ "GenSigSendType" SG_ 1093 RSDS_R_ObjMeasured_6 8;
BA_ "GenSigSendType" SG_ 1093 Checksum39 8;
BA_ "GenSigSendType" SG_ 1093 Rollingcounter39 8;
BA_ "GenSigSendType" SG_ 1093 BlockCounter6 8;
BA_ "GenSigSendType" SG_ 1424 RSDS_R_ObjID_1 8;
BA_ "GenSigSendType" SG_ 1424 RSDS_R_ObjExistProb_1 8;
BA_ "GenSigSendType" SG_ 1424 RSDS_R_ObjObstacleProb_1 8;
BA_ "GenSigSendType" SG_ 1424 RSDS_R_ObjDistX_1 8;
BA_ "GenSigStartValue" SG_ 1424 RSDS_R_ObjDistY_1 1024;
BA_ "GenSigSendType" SG_ 1424 RSDS_R_ObjDistY_1 8;
BA_ "GenSigSendType" SG_ 1424 RSDS_R_ObjDistXStd_1 8;
BA_ "GenSigSendType" SG_ 1424 RSDS_R_ObjType_1 8;
BA_ "GenSigStartValue" SG_ 1424 RSDS_R_ObjRelVelX_1 4102;
BA_ "GenSigSendType" SG_ 1424 RSDS_R_ObjRelVelX_1 8;
BA_ "GenSigStartValue" SG_ 1424 RSDS_R_ObjRelVelY_1 4102;
BA_ "GenSigSendType" SG_ 1424 RSDS_R_ObjRelVelY_1 8;
BA_ "GenSigStartValue" SG_ 1424 RSDS_R_ObjRelAccelX_1 512;
BA_ "GenSigSendType" SG_ 1424 RSDS_R_ObjRelAccelX_1 8;
BA_ "GenSigStartValue" SG_ 1424 RSDS_R_ObjRelAccelY_1 512;
BA_ "GenSigSendType" SG_ 1424 RSDS_R_ObjRelAccelY_1 8;
BA_ "GenSigSendType" SG_ 1424 RSDS_R_ObjMotionType_1 8;
BA_ "GenSigStartValue" SG_ 1424 RSDS_R_ObjMeasured_1 1;
BA_ "GenSigSendType" SG_ 1424 RSDS_R_ObjMeasured_1 8;
BA_ "GenSigSendType" SG_ 1424 RSDS_R_ObjDistYStd_1 8;
BA_ "GenSigSendType" SG_ 1424 RSDS_R_ObjRelVelXStd_1 8;
BA_ "GenSigSendType" SG_ 1424 RSDS_R_ObjRelVelYStd_1 8;
BA_ "GenSigSendType" SG_ 1424 RSDS_R_ObjRAccelXStd_1 8;
BA_ "GenSigSendType" SG_ 1424 RSDS_R_ObjRAccelYStd_1 8;
BA_ "GenSigSendType" SG_ 1424 RSDS_R_ObjWidth_1 8;
BA_ "GenSigSendType" SG_ 1424 RSDS_R_ObjMotionDirection_1 8;
BA_ "GenSigSendType" SG_ 1424 RSDS_R_ObjAge_1 8;
BA_ "GenSigSendType" SG_ 1424 RSDS_R_ObjLength_1 8;
BA_ "GenSigSendType" SG_ 1424 RSDS_R_ObjHeading_1 8;
BA_ "GenSigSendType" SG_ 1424 RSDS_R_ObjYawrate_1 8;
BA_ "GenSigStartValue" SG_ 1424 RSDS_R_ObjRCS_1 400;
BA_ "GenSigSendType" SG_ 1424 RSDS_R_ObjRCS_1 8;
BA_ "GenSigSendType" SG_ 1424 RSDS_R_ObjRefPoint_1 8;
BA_ "GenSigSendType" SG_ 1424 RSDS_R_HWATargetValidity_1 8;
BA_ "GenSigSendType" SG_ 1424 RSDS_R_ObjID_2 8;
BA_ "GenSigSendType" SG_ 1424 RSDS_R_ObjExistProb_2 8;
BA_ "GenSigSendType" SG_ 1424 RSDS_R_ObjObstacleProb_2 8;
BA_ "GenSigSendType" SG_ 1424 RSDS_R_ObjDistX_2 8;
BA_ "GenSigStartValue" SG_ 1424 RSDS_R_ObjDistY_2 1024;
BA_ "GenSigSendType" SG_ 1424 RSDS_R_ObjDistY_2 8;
BA_ "GenSigSendType" SG_ 1424 RSDS_R_ObjDistXStd_2 8;
BA_ "GenSigSendType" SG_ 1424 RSDS_R_ObjType_2 8;
BA_ "GenSigStartValue" SG_ 1424 RSDS_R_ObjRelVelX_2 4102;
BA_ "GenSigSendType" SG_ 1424 RSDS_R_ObjRelVelX_2 8;
BA_ "GenSigStartValue" SG_ 1424 RSDS_R_ObjRelVelY_2 4102;
BA_ "GenSigSendType" SG_ 1424 RSDS_R_ObjRelVelY_2 8;
BA_ "GenSigStartValue" SG_ 1424 RSDS_R_ObjRelAccelX_2 512;
BA_ "GenSigSendType" SG_ 1424 RSDS_R_ObjRelAccelX_2 8;
BA_ "GenSigStartValue" SG_ 1424 RSDS_R_ObjRelAccelY_2 512;
BA_ "GenSigSendType" SG_ 1424 RSDS_R_ObjRelAccelY_2 8;
BA_ "GenSigSendType" SG_ 1424 RSDS_R_ObjMotionType_2 8;
BA_ "GenSigStartValue" SG_ 1424 RSDS_R_ObjMeasured_2 1;
BA_ "GenSigSendType" SG_ 1424 RSDS_R_ObjMeasured_2 8;
BA_ "GenSigSendType" SG_ 1424 RSDS_R_ObjDistYStd_2 8;
BA_ "GenSigSendType" SG_ 1424 RSDS_R_ObjRelVelXStd_2 8;
BA_ "GenSigSendType" SG_ 1424 RSDS_R_ObjRelVelYStd_2 8;
BA_ "GenSigSendType" SG_ 1424 RSDS_R_ObjRAccelXStd_2 8;
BA_ "GenSigSendType" SG_ 1424 RSDS_R_ObjRAccelYStd_2 8;
BA_ "GenSigSendType" SG_ 1424 RSDS_R_ObjWidth_2 8;
BA_ "GenSigSendType" SG_ 1424 RSDS_R_ObjMotionDirection_2 8;
BA_ "GenSigSendType" SG_ 1424 RSDS_R_ObjAge_2 8;
BA_ "GenSigSendType" SG_ 1424 RSDS_R_ObjLength_2 8;
BA_ "GenSigSendType" SG_ 1424 RSDS_R_ObjHeading_2 8;
BA_ "GenSigSendType" SG_ 1424 RSDS_R_ObjYawrate_2 8;
BA_ "GenSigStartValue" SG_ 1424 RSDS_R_ObjRCS_2 400;
BA_ "GenSigSendType" SG_ 1424 RSDS_R_ObjRCS_2 8;
BA_ "GenSigSendType" SG_ 1424 RSDS_R_ObjRefPoint_2 8;
BA_ "GenSigSendType" SG_ 1424 RSDS_R_HWATargetValidity_2 8;
BA_ "GenSigSendType" SG_ 1424 RSDS_R_SGU1_BlockCounter 8;
BA_ "GenSigSendType" SG_ 1424 RSDS_R_SGU1_Checksum1 8;
BA_ "GenSigSendType" SG_ 1424 RSDS_R_SGU1_Checksum2 8;
BA_ "GenSigSendType" SG_ 1424 RSDS_R_SGU1_Checksum3 8;
BA_ "GenSigSendType" SG_ 1424 RSDS_R_SGU1_Checksum4 8;
BA_ "GenSigSendType" SG_ 1424 RSDS_R_SGU1_Checksum5 8;
BA_ "GenSigSendType" SG_ 1424 RSDS_R_SGU1_Checksum6 8;
BA_ "GenSigSendType" SG_ 1424 RSDS_R_SGU1_Checksum7 8;
BA_ "GenSigSendType" SG_ 1424 RSDS_R_SGU1_Checksum8 8;
BA_ "GenSigSendType" SG_ 1424 RSDS_R_SGU1_RollingCounter1 8;
BA_ "GenSigSendType" SG_ 1424 RSDS_R_SGU1_RollingCounter2 8;
BA_ "GenSigSendType" SG_ 1424 RSDS_R_SGU1_RollingCounter3 8;
BA_ "GenSigSendType" SG_ 1424 RSDS_R_SGU1_RollingCounter4 8;
BA_ "GenSigSendType" SG_ 1424 RSDS_R_SGU1_RollingCounter5 8;
BA_ "GenSigSendType" SG_ 1424 RSDS_R_SGU1_RollingCounter6 8;
BA_ "GenSigSendType" SG_ 1424 RSDS_R_SGU1_RollingCounter7 8;
BA_ "GenSigSendType" SG_ 1424 RSDS_R_SGU1_RollingCounter8 8;
BA_ "GenSigSendType" SG_ 1425 RSDS_R_ObjID_3 8;
BA_ "GenSigSendType" SG_ 1425 RSDS_R_ObjExistProb_3 8;
BA_ "GenSigSendType" SG_ 1425 RSDS_R_ObjObstacleProb_3 8;
BA_ "GenSigSendType" SG_ 1425 RSDS_R_ObjDistX_3 8;
BA_ "GenSigStartValue" SG_ 1425 RSDS_R_ObjDistY_3 1024;
BA_ "GenSigSendType" SG_ 1425 RSDS_R_ObjDistY_3 8;
BA_ "GenSigSendType" SG_ 1425 RSDS_R_ObjDistXStd_3 8;
BA_ "GenSigSendType" SG_ 1425 RSDS_R_ObjType_3 8;
BA_ "GenSigStartValue" SG_ 1425 RSDS_R_ObjRelVelX_3 4102;
BA_ "GenSigSendType" SG_ 1425 RSDS_R_ObjRelVelX_3 8;
BA_ "GenSigStartValue" SG_ 1425 RSDS_R_ObjRelVelY_3 4102;
BA_ "GenSigSendType" SG_ 1425 RSDS_R_ObjRelVelY_3 8;
BA_ "GenSigStartValue" SG_ 1425 RSDS_R_ObjRelAccelX_3 512;
BA_ "GenSigSendType" SG_ 1425 RSDS_R_ObjRelAccelX_3 8;
BA_ "GenSigStartValue" SG_ 1425 RSDS_R_ObjRelAccelY_3 512;
BA_ "GenSigSendType" SG_ 1425 RSDS_R_ObjRelAccelY_3 8;
BA_ "GenSigSendType" SG_ 1425 RSDS_R_ObjMotionType_3 8;
BA_ "GenSigStartValue" SG_ 1425 RSDS_R_ObjMeasured_3 1;
BA_ "GenSigSendType" SG_ 1425 RSDS_R_ObjMeasured_3 8;
BA_ "GenSigSendType" SG_ 1425 RSDS_R_ObjDistYStd_3 8;
BA_ "GenSigSendType" SG_ 1425 RSDS_R_ObjRelVelXStd_3 8;
BA_ "GenSigSendType" SG_ 1425 RSDS_R_ObjRelVelYStd_3 8;
BA_ "GenSigSendType" SG_ 1425 RSDS_R_ObjRAccelXStd_3 8;
BA_ "GenSigSendType" SG_ 1425 RSDS_R_ObjRAccelYStd_3 8;
BA_ "GenSigSendType" SG_ 1425 RSDS_R_ObjWidth_3 8;
BA_ "GenSigSendType" SG_ 1425 RSDS_R_ObjMotionDirection_3 8;
BA_ "GenSigSendType" SG_ 1425 RSDS_R_ObjAge_3 8;
BA_ "GenSigSendType" SG_ 1425 RSDS_R_ObjLength_3 8;
BA_ "GenSigSendType" SG_ 1425 RSDS_R_ObjHeading_3 8;
BA_ "GenSigSendType" SG_ 1425 RSDS_R_ObjYawrate_3 8;
BA_ "GenSigStartValue" SG_ 1425 RSDS_R_ObjRCS_3 400;
BA_ "GenSigSendType" SG_ 1425 RSDS_R_ObjRCS_3 8;
BA_ "GenSigSendType" SG_ 1425 RSDS_R_ObjRefPoint_3 8;
BA_ "GenSigSendType" SG_ 1425 RSDS_R_HWATargetValidity_3 8;
BA_ "GenSigSendType" SG_ 1425 RSDS_R_ObjID_4 8;
BA_ "GenSigSendType" SG_ 1425 RSDS_R_ObjExistProb_4 8;
BA_ "GenSigSendType" SG_ 1425 RSDS_R_ObjObstacleProb_4 8;
BA_ "GenSigSendType" SG_ 1425 RSDS_R_ObjDistX_4 8;
BA_ "GenSigStartValue" SG_ 1425 RSDS_R_ObjDistY_4 1024;
BA_ "GenSigSendType" SG_ 1425 RSDS_R_ObjDistY_4 8;
BA_ "GenSigSendType" SG_ 1425 RSDS_R_ObjDistXStd_4 8;
BA_ "GenSigSendType" SG_ 1425 RSDS_R_ObjType_4 8;
BA_ "GenSigStartValue" SG_ 1425 RSDS_R_ObjRelVelX_4 4102;
BA_ "GenSigSendType" SG_ 1425 RSDS_R_ObjRelVelX_4 8;
BA_ "GenSigStartValue" SG_ 1425 RSDS_R_ObjRelVelY_4 4102;
BA_ "GenSigSendType" SG_ 1425 RSDS_R_ObjRelVelY_4 8;
BA_ "GenSigStartValue" SG_ 1425 RSDS_R_ObjRelAccelX_4 512;
BA_ "GenSigSendType" SG_ 1425 RSDS_R_ObjRelAccelX_4 8;
BA_ "GenSigStartValue" SG_ 1425 RSDS_R_ObjRelAccelY_4 512;
BA_ "GenSigSendType" SG_ 1425 RSDS_R_ObjRelAccelY_4 8;
BA_ "GenSigSendType" SG_ 1425 RSDS_R_ObjMotionType_4 8;
BA_ "GenSigStartValue" SG_ 1425 RSDS_R_ObjMeasured_4 1;
BA_ "GenSigSendType" SG_ 1425 RSDS_R_ObjMeasured_4 8;
BA_ "GenSigSendType" SG_ 1425 RSDS_R_ObjDistYStd_4 8;
BA_ "GenSigSendType" SG_ 1425 RSDS_R_ObjRelVelXStd_4 8;
BA_ "GenSigSendType" SG_ 1425 RSDS_R_ObjRelVelYStd_4 8;
BA_ "GenSigSendType" SG_ 1425 RSDS_R_ObjRAccelXStd_4 8;
BA_ "GenSigSendType" SG_ 1425 RSDS_R_ObjRAccelYStd_4 8;
BA_ "GenSigSendType" SG_ 1425 RSDS_R_ObjWidth_4 8;
BA_ "GenSigSendType" SG_ 1425 RSDS_R_ObjMotionDirection_4 8;
BA_ "GenSigSendType" SG_ 1425 RSDS_R_ObjAge_4 8;
BA_ "GenSigSendType" SG_ 1425 RSDS_R_ObjLength_4 8;
BA_ "GenSigSendType" SG_ 1425 RSDS_R_ObjHeading_4 8;
BA_ "GenSigSendType" SG_ 1425 RSDS_R_ObjYawrate_4 8;
BA_ "GenSigStartValue" SG_ 1425 RSDS_R_ObjRCS_4 400;
BA_ "GenSigSendType" SG_ 1425 RSDS_R_ObjRCS_4 8;
BA_ "GenSigSendType" SG_ 1425 RSDS_R_ObjRefPoint_4 8;
BA_ "GenSigSendType" SG_ 1425 RSDS_R_HWATargetValidity_4 8;
BA_ "GenSigSendType" SG_ 1425 RSDS_R_SGU2_BlockCounter 8;
BA_ "GenSigSendType" SG_ 1425 RSDS_R_SGU2_Checksum1 8;
BA_ "GenSigSendType" SG_ 1425 RSDS_R_SGU2_Checksum2 8;
BA_ "GenSigSendType" SG_ 1425 RSDS_R_SGU2_Checksum3 8;
BA_ "GenSigSendType" SG_ 1425 RSDS_R_SGU2_Checksum4 8;
BA_ "GenSigSendType" SG_ 1425 RSDS_R_SGU2_Checksum5 8;
BA_ "GenSigSendType" SG_ 1425 RSDS_R_SGU2_Checksum6 8;
BA_ "GenSigSendType" SG_ 1425 RSDS_R_SGU2_Checksum7 8;
BA_ "GenSigSendType" SG_ 1425 RSDS_R_SGU2_Checksum8 8;
BA_ "GenSigSendType" SG_ 1425 RSDS_R_SGU2_RollingCounter1 8;
BA_ "GenSigSendType" SG_ 1425 RSDS_R_SGU2_RollingCounter2 8;
BA_ "GenSigSendType" SG_ 1425 RSDS_R_SGU2_RollingCounter3 8;
BA_ "GenSigSendType" SG_ 1425 RSDS_R_SGU2_RollingCounter4 8;
BA_ "GenSigSendType" SG_ 1425 RSDS_R_SGU2_RollingCounter5 8;
BA_ "GenSigSendType" SG_ 1425 RSDS_R_SGU2_RollingCounter6 8;
BA_ "GenSigSendType" SG_ 1425 RSDS_R_SGU2_RollingCounter7 8;
BA_ "GenSigSendType" SG_ 1425 RSDS_R_SGU2_RollingCounter8 8;
BA_ "GenSigSendType" SG_ 1426 RSDS_R_ObjID_5 8;
BA_ "GenSigSendType" SG_ 1426 RSDS_R_ObjExistProb_5 8;
BA_ "GenSigSendType" SG_ 1426 RSDS_R_ObjObstacleProb_5 8;
BA_ "GenSigSendType" SG_ 1426 RSDS_R_ObjDistX_5 8;
BA_ "GenSigStartValue" SG_ 1426 RSDS_R_ObjDistY_5 1024;
BA_ "GenSigSendType" SG_ 1426 RSDS_R_ObjDistY_5 8;
BA_ "GenSigSendType" SG_ 1426 RSDS_R_ObjDistXStd_5 8;
BA_ "GenSigSendType" SG_ 1426 RSDS_R_ObjType_5 8;
BA_ "GenSigStartValue" SG_ 1426 RSDS_R_ObjRelVelX_5 4102;
BA_ "GenSigSendType" SG_ 1426 RSDS_R_ObjRelVelX_5 8;
BA_ "GenSigStartValue" SG_ 1426 RSDS_R_ObjRelVelY_5 4102;
BA_ "GenSigSendType" SG_ 1426 RSDS_R_ObjRelVelY_5 8;
BA_ "GenSigStartValue" SG_ 1426 RSDS_R_ObjRelAccelX_5 512;
BA_ "GenSigSendType" SG_ 1426 RSDS_R_ObjRelAccelX_5 8;
BA_ "GenSigStartValue" SG_ 1426 RSDS_R_ObjRelAccelY_5 512;
BA_ "GenSigSendType" SG_ 1426 RSDS_R_ObjRelAccelY_5 8;
BA_ "GenSigSendType" SG_ 1426 RSDS_R_ObjMotionType_5 8;
BA_ "GenSigStartValue" SG_ 1426 RSDS_R_ObjMeasured_5 1;
BA_ "GenSigSendType" SG_ 1426 RSDS_R_ObjMeasured_5 8;
BA_ "GenSigSendType" SG_ 1426 RSDS_R_ObjDistYStd_5 8;
BA_ "GenSigSendType" SG_ 1426 RSDS_R_ObjRelVelXStd_5 8;
BA_ "GenSigSendType" SG_ 1426 RSDS_R_ObjRelVelYStd_5 8;
BA_ "GenSigSendType" SG_ 1426 RSDS_R_ObjRAccelXStd_5 8;
BA_ "GenSigSendType" SG_ 1426 RSDS_R_ObjRAccelYStd_5 8;
BA_ "GenSigSendType" SG_ 1426 RSDS_R_ObjWidth_5 8;
BA_ "GenSigSendType" SG_ 1426 RSDS_R_ObjMotionDirection_5 8;
BA_ "GenSigSendType" SG_ 1426 RSDS_R_ObjAge_5 8;
BA_ "GenSigSendType" SG_ 1426 RSDS_R_ObjLength_5 8;
BA_ "GenSigSendType" SG_ 1426 RSDS_R_ObjHeading_5 8;
BA_ "GenSigSendType" SG_ 1426 RSDS_R_ObjYawrate_5 8;
BA_ "GenSigStartValue" SG_ 1426 RSDS_R_ObjRCS_5 400;
BA_ "GenSigSendType" SG_ 1426 RSDS_R_ObjRCS_5 8;
BA_ "GenSigSendType" SG_ 1426 RSDS_R_ObjRefPoint_5 8;
BA_ "GenSigSendType" SG_ 1426 RSDS_R_HWATargetValidity_5 8;
BA_ "GenSigSendType" SG_ 1426 RSDS_R_ObjID_6 8;
BA_ "GenSigSendType" SG_ 1426 RSDS_R_ObjExistProb_6 8;
BA_ "GenSigSendType" SG_ 1426 RSDS_R_ObjObstacleProb_6 8;
BA_ "GenSigSendType" SG_ 1426 RSDS_R_ObjDistX_6 8;
BA_ "GenSigStartValue" SG_ 1426 RSDS_R_ObjDistY_6 1024;
BA_ "GenSigSendType" SG_ 1426 RSDS_R_ObjDistY_6 8;
BA_ "GenSigSendType" SG_ 1426 RSDS_R_ObjDistXStd_6 8;
BA_ "GenSigSendType" SG_ 1426 RSDS_R_ObjType_6 8;
BA_ "GenSigStartValue" SG_ 1426 RSDS_R_ObjRelVelX_6 4102;
BA_ "GenSigSendType" SG_ 1426 RSDS_R_ObjRelVelX_6 8;
BA_ "GenSigStartValue" SG_ 1426 RSDS_R_ObjRelVelY_6 4102;
BA_ "GenSigSendType" SG_ 1426 RSDS_R_ObjRelVelY_6 8;
BA_ "GenSigStartValue" SG_ 1426 RSDS_R_ObjRelAccelX_6 512;
BA_ "GenSigSendType" SG_ 1426 RSDS_R_ObjRelAccelX_6 8;
BA_ "GenSigStartValue" SG_ 1426 RSDS_R_ObjRelAccelY_6 512;
BA_ "GenSigSendType" SG_ 1426 RSDS_R_ObjRelAccelY_6 8;
BA_ "GenSigSendType" SG_ 1426 RSDS_R_ObjMotionType_6 8;
BA_ "GenSigStartValue" SG_ 1426 RSDS_R_ObjMeasured_6 1;
BA_ "GenSigSendType" SG_ 1426 RSDS_R_ObjMeasured_6 8;
BA_ "GenSigSendType" SG_ 1426 RSDS_R_ObjDistYStd_6 8;
BA_ "GenSigSendType" SG_ 1426 RSDS_R_ObjRelVelXStd_6 8;
BA_ "GenSigSendType" SG_ 1426 RSDS_R_ObjRelVelYStd_6 8;
BA_ "GenSigSendType" SG_ 1426 RSDS_R_ObjRAccelXStd_6 8;
BA_ "GenSigSendType" SG_ 1426 RSDS_R_ObjRAccelYStd_6 8;
BA_ "GenSigSendType" SG_ 1426 RSDS_R_ObjWidth_6 8;
BA_ "GenSigSendType" SG_ 1426 RSDS_R_ObjMotionDirection_6 8;
BA_ "GenSigSendType" SG_ 1426 RSDS_R_ObjAge_6 8;
BA_ "GenSigSendType" SG_ 1426 RSDS_R_ObjLength_6 8;
BA_ "GenSigSendType" SG_ 1426 RSDS_R_ObjHeading_6 8;
BA_ "GenSigSendType" SG_ 1426 RSDS_R_ObjYawrate_6 8;
BA_ "GenSigStartValue" SG_ 1426 RSDS_R_ObjRCS_6 400;
BA_ "GenSigSendType" SG_ 1426 RSDS_R_ObjRCS_6 8;
BA_ "GenSigSendType" SG_ 1426 RSDS_R_ObjRefPoint_6 8;
BA_ "GenSigSendType" SG_ 1426 RSDS_R_HWATargetValidity_6 8;
BA_ "GenSigSendType" SG_ 1426 RSDS_R_SGU3_BlockCounter 8;
BA_ "GenSigSendType" SG_ 1426 RSDS_R_SGU3_Checksum1 8;
BA_ "GenSigSendType" SG_ 1426 RSDS_R_SGU3_Checksum2 8;
BA_ "GenSigSendType" SG_ 1426 RSDS_R_SGU3_Checksum3 8;
BA_ "GenSigSendType" SG_ 1426 RSDS_R_SGU3_Checksum4 8;
BA_ "GenSigSendType" SG_ 1426 RSDS_R_SGU3_Checksum5 8;
BA_ "GenSigSendType" SG_ 1426 RSDS_R_SGU3_Checksum6 8;
BA_ "GenSigSendType" SG_ 1426 RSDS_R_SGU3_Checksum7 8;
BA_ "GenSigSendType" SG_ 1426 RSDS_R_SGU3_Checksum8 8;
BA_ "GenSigSendType" SG_ 1426 RSDS_R_SGU3_RollingCounter1 8;
BA_ "GenSigSendType" SG_ 1426 RSDS_R_SGU3_RollingCounter2 8;
BA_ "GenSigSendType" SG_ 1426 RSDS_R_SGU3_RollingCounter3 8;
BA_ "GenSigSendType" SG_ 1426 RSDS_R_SGU3_RollingCounter4 8;
BA_ "GenSigSendType" SG_ 1426 RSDS_R_SGU3_RollingCounter5 8;
BA_ "GenSigSendType" SG_ 1426 RSDS_R_SGU3_RollingCounter6 8;
BA_ "GenSigSendType" SG_ 1426 RSDS_R_SGU3_RollingCounter7 8;
BA_ "GenSigSendType" SG_ 1426 RSDS_R_SGU3_RollingCounter8 8;
BA_ "GenSigSendType" SG_ 1427 RSDS_R_ObjID_7 8;
BA_ "GenSigSendType" SG_ 1427 RSDS_R_ObjExistProb_7 8;
BA_ "GenSigSendType" SG_ 1427 RSDS_R_ObjObstacleProb_7 8;
BA_ "GenSigSendType" SG_ 1427 RSDS_R_ObjDistX_7 8;
BA_ "GenSigStartValue" SG_ 1427 RSDS_R_ObjDistY_7 1024;
BA_ "GenSigSendType" SG_ 1427 RSDS_R_ObjDistY_7 8;
BA_ "GenSigSendType" SG_ 1427 RSDS_R_ObjDistXStd_7 8;
BA_ "GenSigSendType" SG_ 1427 RSDS_R_ObjType_7 8;
BA_ "GenSigStartValue" SG_ 1427 RSDS_R_ObjRelVelX_7 4102;
BA_ "GenSigSendType" SG_ 1427 RSDS_R_ObjRelVelX_7 8;
BA_ "GenSigStartValue" SG_ 1427 RSDS_R_ObjRelVelY_7 4102;
BA_ "GenSigSendType" SG_ 1427 RSDS_R_ObjRelVelY_7 8;
BA_ "GenSigStartValue" SG_ 1427 RSDS_R_ObjRelAccelX_7 512;
BA_ "GenSigSendType" SG_ 1427 RSDS_R_ObjRelAccelX_7 8;
BA_ "GenSigStartValue" SG_ 1427 RSDS_R_ObjRelAccelY_7 512;
BA_ "GenSigSendType" SG_ 1427 RSDS_R_ObjRelAccelY_7 8;
BA_ "GenSigSendType" SG_ 1427 RSDS_R_ObjMotionType_7 8;
BA_ "GenSigStartValue" SG_ 1427 RSDS_R_ObjMeasured_7 1;
BA_ "GenSigSendType" SG_ 1427 RSDS_R_ObjMeasured_7 8;
BA_ "GenSigSendType" SG_ 1427 RSDS_R_ObjDistYStd_7 8;
BA_ "GenSigSendType" SG_ 1427 RSDS_R_ObjRelVelXStd_7 8;
BA_ "GenSigSendType" SG_ 1427 RSDS_R_ObjRelVelYStd_7 8;
BA_ "GenSigSendType" SG_ 1427 RSDS_R_ObjRAccelXStd_7 8;
BA_ "GenSigSendType" SG_ 1427 RSDS_R_ObjRAccelYStd_7 8;
BA_ "GenSigSendType" SG_ 1427 RSDS_R_ObjWidth_7 8;
BA_ "GenSigSendType" SG_ 1427 RSDS_R_ObjMotionDirection_7 8;
BA_ "GenSigSendType" SG_ 1427 RSDS_R_ObjAge_7 8;
BA_ "GenSigSendType" SG_ 1427 RSDS_R_ObjLength_7 8;
BA_ "GenSigSendType" SG_ 1427 RSDS_R_ObjHeading_7 8;
BA_ "GenSigSendType" SG_ 1427 RSDS_R_ObjYawrate_7 8;
BA_ "GenSigStartValue" SG_ 1427 RSDS_R_ObjRCS_7 400;
BA_ "GenSigSendType" SG_ 1427 RSDS_R_ObjRCS_7 8;
BA_ "GenSigSendType" SG_ 1427 RSDS_R_ObjRefPoint_7 8;
BA_ "GenSigSendType" SG_ 1427 RSDS_R_HWATargetValidity_7 8;
BA_ "GenSigSendType" SG_ 1427 RSDS_R_ObjID_8 8;
BA_ "GenSigSendType" SG_ 1427 RSDS_R_ObjExistProb_8 8;
BA_ "GenSigSendType" SG_ 1427 RSDS_R_ObjObstacleProb_8 8;
BA_ "GenSigSendType" SG_ 1427 RSDS_R_ObjDistX_8 8;
BA_ "GenSigStartValue" SG_ 1427 RSDS_R_ObjDistY_8 1024;
BA_ "GenSigSendType" SG_ 1427 RSDS_R_ObjDistY_8 8;
BA_ "GenSigSendType" SG_ 1427 RSDS_R_ObjDistXStd_8 8;
BA_ "GenSigSendType" SG_ 1427 RSDS_R_ObjType_8 8;
BA_ "GenSigStartValue" SG_ 1427 RSDS_R_ObjRelVelX_8 4102;
BA_ "GenSigSendType" SG_ 1427 RSDS_R_ObjRelVelX_8 8;
BA_ "GenSigStartValue" SG_ 1427 RSDS_R_ObjRelVelY_8 4102;
BA_ "GenSigSendType" SG_ 1427 RSDS_R_ObjRelVelY_8 8;
BA_ "GenSigStartValue" SG_ 1427 RSDS_R_ObjRelAccelX_8 512;
BA_ "GenSigSendType" SG_ 1427 RSDS_R_ObjRelAccelX_8 8;
BA_ "GenSigStartValue" SG_ 1427 RSDS_R_ObjRelAccelY_8 512;
BA_ "GenSigSendType" SG_ 1427 RSDS_R_ObjRelAccelY_8 8;
BA_ "GenSigSendType" SG_ 1427 RSDS_R_ObjMotionType_8 8;
BA_ "GenSigStartValue" SG_ 1427 RSDS_R_ObjMeasured_8 1;
BA_ "GenSigSendType" SG_ 1427 RSDS_R_ObjMeasured_8 8;
BA_ "GenSigSendType" SG_ 1427 RSDS_R_ObjDistYStd_8 8;
BA_ "GenSigSendType" SG_ 1427 RSDS_R_ObjRelVelXStd_8 8;
BA_ "GenSigSendType" SG_ 1427 RSDS_R_ObjRelVelYStd_8 8;
BA_ "GenSigSendType" SG_ 1427 RSDS_R_ObjRAccelXStd_8 8;
BA_ "GenSigSendType" SG_ 1427 RSDS_R_ObjRAccelYStd_8 8;
BA_ "GenSigSendType" SG_ 1427 RSDS_R_ObjWidth_8 8;
BA_ "GenSigSendType" SG_ 1427 RSDS_R_ObjMotionDirection_8 8;
BA_ "GenSigSendType" SG_ 1427 RSDS_R_ObjAge_8 8;
BA_ "GenSigSendType" SG_ 1427 RSDS_R_ObjLength_8 8;
BA_ "GenSigSendType" SG_ 1427 RSDS_R_ObjHeading_8 8;
BA_ "GenSigSendType" SG_ 1427 RSDS_R_ObjYawrate_8 8;
BA_ "GenSigStartValue" SG_ 1427 RSDS_R_ObjRCS_8 400;
BA_ "GenSigSendType" SG_ 1427 RSDS_R_ObjRCS_8 8;
BA_ "GenSigSendType" SG_ 1427 RSDS_R_ObjRefPoint_8 8;
BA_ "GenSigSendType" SG_ 1427 RSDS_R_HWATargetValidity_8 8;
BA_ "GenSigSendType" SG_ 1427 RSDS_R_SGU4_BlockCounter 8;
BA_ "GenSigSendType" SG_ 1427 RSDS_R_SGU4_Checksum1 8;
BA_ "GenSigSendType" SG_ 1427 RSDS_R_SGU4_Checksum2 8;
BA_ "GenSigSendType" SG_ 1427 RSDS_R_SGU4_Checksum3 8;
BA_ "GenSigSendType" SG_ 1427 RSDS_R_SGU4_Checksum4 8;
BA_ "GenSigSendType" SG_ 1427 RSDS_R_SGU4_Checksum5 8;
BA_ "GenSigSendType" SG_ 1427 RSDS_R_SGU4_Checksum6 8;
BA_ "GenSigSendType" SG_ 1427 RSDS_R_SGU4_Checksum7 8;
BA_ "GenSigSendType" SG_ 1427 RSDS_R_SGU4_Checksum8 8;
BA_ "GenSigSendType" SG_ 1427 RSDS_R_SGU4_RollingCounter1 8;
BA_ "GenSigSendType" SG_ 1427 RSDS_R_SGU4_RollingCounter2 8;
BA_ "GenSigSendType" SG_ 1427 RSDS_R_SGU4_RollingCounter3 8;
BA_ "GenSigSendType" SG_ 1427 RSDS_R_SGU4_RollingCounter4 8;
BA_ "GenSigSendType" SG_ 1427 RSDS_R_SGU4_RollingCounter5 8;
BA_ "GenSigSendType" SG_ 1427 RSDS_R_SGU4_RollingCounter6 8;
BA_ "GenSigSendType" SG_ 1427 RSDS_R_SGU4_RollingCounter7 8;
BA_ "GenSigSendType" SG_ 1427 RSDS_R_SGU4_RollingCounter8 8;
BA_ "GenSigStartValue" SG_  629 TrailerStatusVld 1;
VAL_ 395 AEB_TgtDecel_ReqValue 65535 "Invalid" ;
VAL_ 395 AEB_TgtDecel_Req 0 "No Request" 1 "Request" ;
VAL_ 303 HCU_GearSts 0 " Select lever in position -P- " 1 " Reserved " 2 " Reserved " 3 " Reserved " 4 " Reserved " 5 " Select lever in position -D- " 6 " Select lever in position -N- " 7 " Select lever in position -R- " 8 " Reserved " 9 " Reserved " 10 " Reserved " 11 " Reserved " 12 " Reserved " 13 " Reserved " 14 " Intermediate position " 15 " Invalid  " ;
VAL_ 350 Checksum_CR_R_1 0 " Valid value " ;
VAL_ 350 CR_FCTA_Resp 0 " OFF " 1 " ON " ;
VAL_ 350 CR_FCTB_Resp 0 " OFF " 1 " ON " ;
VAL_ 350 CR_ErrSts 0 " No Error " 1 " Error " ;
VAL_ 350 CR_BliSts 0 " No Blindness " 1 " Blindness " ;
VAL_ 350 FCTB_ABA_Level 0 " Level 0 " 1 " Level 1 " 2 " Level 2 " 3 " Level 3 " ;
VAL_ 350 FCTB_ABA_Req 0 " No Request " 1 " Request " ;
VAL_ 350 FCTB_ABP_Req 0 " No Request " 1 " Request " ;
VAL_ 350 FCTA_Warn 0 " No warning " 1 " Warning " ;
VAL_ 350 FCTBTrig 0 " Not tirggered " 1 " tirggered " ;
VAL_ 350 FCTA_B_FuncSts 0 " No display  " 1 " error  " 2 " FCTA_B temporarily unavailable " 3 " FCTA_B Performance degradation " ;
VAL_ 350 CR_BrkgReqVal 0 " Valid value " 65535 " Invalid " ;
VAL_ 350 CR_BrkgReq 0 " No Request " 1 " Request " ;
VAL_ 350 FCTA_B_TTC 0 " No Display " 1 " valid value " ;
VAL_ 350 RollingCounter_CR_R_1 0 " Valid value " 15 " Invalid value " ;
VAL_ 350 Checksum_CR_R_2 0 " Valid value " ;
VAL_ 350 CR_ObjSts_Le 0 " Target Invalid " 1 " Target Valid " 2 " No target " 3 " Reserved " ;
VAL_ 350 CR_ObjID_Le 0 " Valid value " ;
VAL_ 350 CR_ObjDistX_Le 0 " Valid value " ;
VAL_ 350 CR_ObjDistY_Le 0 " Valid value " ;
VAL_ 350 CR_ObjRelVelX_Le 0 " Valid value " ;
VAL_ 350 CR_ObjRelAccelX_Le 0 " Valid values " ;
VAL_ 350 CR_ObjMotionType_Le 0 " int " 1 " unknown " 2 " Drive " 3 " Stopped " 4 " Stand " 5 " reserved " 6 " reserved " 7 " reserved " ;
VAL_ 350 RollingCounter_CR_R_2 0 " Valid value " 15 " Invalid value " ;
VAL_ 350 Checksum_CR_R_3 0 " Valid value " ;
VAL_ 350 CR_ObjSts_Ri 0 " Target Invalid " 1 " Target Valid " 2 " No target " 3 " Reserved " ;
VAL_ 350 CR_ObjID_Ri 0 " Valid value " ;
VAL_ 350 CR_ObjDistX_Ri 0 " Valid value " ;
VAL_ 350 CR_ObjDistY_Ri 0 " Valid value " ;
VAL_ 350 CR_ObjRelVelX_Ri 0 " Valid value " ;
VAL_ 350 CR_ObjRelAccelX_Ri 0 " Valid values " ;
VAL_ 350 CR_ObjMotionType_Ri 0 " int " 1 " unknown " 2 " Drive " 3 " Stopped " 4 " Stand " 5 " reserved " 6 " reserved " 7 " reserved " ;
VAL_ 350 RollingCounter_CR_R_3 0 " Valid value " 15 " Invalid value " ;
VAL_ 350 Checksum_CR_R_4 0 " Valid value " ;
VAL_ 350 CR_ObjRelAccelY_Ri 0 " Valid values " ;
VAL_ 350 CR_ObjRelVelY_Ri 0 " Valid value " ;
VAL_ 350 CR_ObjRelAccelY_Le 0 " Valid values " ;
VAL_ 350 CR_ObjRelVelY_Le 0 " Valid value " ;
VAL_ 350 RollingCounter_CR_R_4 0 " Valid value " 15 " Invalid value " ;
VAL_ 350 CR_ObjDistXStd_Le 0 " valid value " ;
VAL_ 350 CR_ObjDistYStd_Le 0 " valid value " ;
VAL_ 350 CR_ObjRelVelXStd_Le 0 " valid value " ;
VAL_ 350 CR_ObjRelVelYStd_Le 0 " valid value " ;
VAL_ 350 CR_ObjRAccelXStd_Le 0 " valid value " ;
VAL_ 350 CR_ObjRAccelYStd_Le 0 " valid value " ;
VAL_ 350 CR_ObjDistXStd_Ri 0 " valid value " ;
VAL_ 350 CR_ObjDistYStd_Ri 0 " valid value " ;
VAL_ 350 CR_ObjRelVelXStd_Ri 0 " valid value " ;
VAL_ 350 CR_ObjRelVelYStd_Ri 0 " valid value " ;
VAL_ 350 CR_ObjRAccelXStd_Ri 0 " valid value " ;
VAL_ 350 CR_ObjRAccelYStd_Ri 0 " valid value " ;
VAL_ 846 Sync_CRC 0 " Valid value " ;
VAL_ 846 Sync_OVS 0 " Valid value " ;
VAL_ 846 Sync_Resd 0 " Valid value " ;
VAL_ 846 Sync_Counter 0 " Valid value " ;
VAL_ 846 Sync_SGW 0 " Valid value " ;
VAL_ 846 Sync_SyncTime 0 " Valid value " ;
VAL_ 846 Sync_TimeDomain 0 " Valid value " ;
VAL_ 846 Sync_Type 0 " Valid value " ;
VAL_ 323 ACC_CRInterface 0 " No Response " 1 " Response " ;
VAL_ 121 BrkPedalSts_0x079 0 " Not pressed " 1 " Pressed " 2 " Reserved " 3 " Error " ;
VAL_ 121 EngSpd_0x079 0 " Valid values  " ;
VAL_ 121 EngSpdVldty_0x079 0 " Invalid " 1 " Valid " 2 " Initial value " 3 " Reserved " ;
VAL_ 259 AccelPedlPosnDiagc_0x103 0 " Valid values  " ;
VAL_ 259 AccelPedalPosnVldty_0x103 0 " Invalid " 1 " Valid " 2 " Init value " 3 " Reserved " ;
VAL_ 259 EngState_0x103 0 " Stopped " 1 " Cranking " 2 " Running " 3 " Stalling " ;
VAL_ 259 EngState_PHEV_0x103 0 " Stand by " 1 " Ready " 2 " Cranking " 3 " Running " 4 " Stopping " 5 " Finish " 6 " Autostopping " 7 " Reserved " ;
VAL_ 273 EngSpd 0 " Valid values  " ;
VAL_ 273 EngSpdVldty 0 " Invalid " 1 " Valid " 2 " Initial value " 3 " Reserved " ;
VAL_ 273 BrkPedalSts1 0 " Not pressed " 1 " Pressed " 2 " Reserved " 3 " Error " ;
VAL_ 545 CurrentGearValid 0 " Invalid  " 1 " Valid " ;
VAL_ 545 CURRENT_GEAR 0 " Current gear -N- or -P- " 1 " Current gear -1- " 2 " Current gear -2- " 3 " Current gear -3- " 4 " Current gear -4- " 5 " Current gear -5- " 6 " Current gear -6- " 7 " Current gear -7- " 8 " Current gear -R- " 9 " Reserved " ;
VAL_ 545 TGS_LEVER 0 " Select lever in position -P- " 1 " Reserved " 2 " Reserved " 3 " Reserved " 4 " Reserved " 5 " Select lever in position -D- " 6 " Select lever in position -N- " 7 " Select lever in position -R- " 8 " Select lever in position -M- " 9 " Reserved " 14 " Intermediate position " 15 " Invalid  " ;
VAL_ 311 ESP_DiagActv_0x137 0 "ESP diagnosis is inactive" 1 "ESP diagnosis is active" ;
VAL_ 311 BrkDskOvrheatd_0x137 0 " Not high " 1 " Temp too high " ;
VAL_ 311 NoBrkForce_0x137 0 " EXist brake force " 1 " No brake force " ;
VAL_ 311 VehStandstill_0x137 0 " Not standstill " 1 " Standstill " 2 " Invalid (short unavailability, maX 3s) " 3 " Reserved " ;
VAL_ 311 AEBIBActv_0x137 0 " Not active " 1 " Active " ;
VAL_ 311 AEBBAActv_0x137 0 " Not active " 1 " Active " ;
VAL_ 311 AEBAvailable_0x137 0 " Unusable " 1 " Usable " ;
VAL_ 311 ABPAvailable_0x137 0 " Unusable " 1 " Usable " ;
VAL_ 311 ABPActv_0x137 0 " Not active " 1 " Active " ;
VAL_ 311 ABAavailable_0x137 0 " Unusable " 1 " Usable " ;
VAL_ 311 ABAactv_0x137 0 " Not active " 1 " Active " ;
VAL_ 311 HDCCtrl_0x137 0 " OFF " 1 " On active braking " 2 " On not active braking " 3 " Reserved " ;
VAL_ 311 CTABrkAvailable_0x137 0 " Not Available " 1 " Available " ;
VAL_ 311 CheckSum_ESP1_0x137 0 " Valid values " ;
VAL_ 311 ESPFuncOffSts_0x137 0 " Available/On " 1 " Unavailable/Off " ;
VAL_ 311 ESPFailSts_0x137 0 " No failure " 1 " Failure " ;
VAL_ 311 ESP_MasterCylBrkPressVld_0x137 0 " Invalid " 1 " Valid " ;
VAL_ 311 MSRActv_0x137 0 " Not active " 1 " Active " ;
VAL_ 311 VDCActv_0x137 0 " Not active " 1 " Active " ;
VAL_ 311 PTCActv_0x137 0 " Not active " 1 " Active " ;
VAL_ 311 BTCActv_0x137 0 " Not active " 1 " Active " ;
VAL_ 311 ESP_MasterCylBrkPress_0x137 0 " Valid value " 14961 " Reserved " ;
VAL_ 311 MSRActv_RA_0x137 0 " Inactive " 1 " Active " ;
VAL_ 311 PTCActv_RA_0x137 0 " Inactive " 1 " Active " ;
VAL_ 311 BTCActv_RA_0x137 0 " Inactive " 1 " Active " ;
VAL_ 311 RollingCounter_ESP1_0x137 0 " Valid value " 15 " Invalid value " ;
VAL_ 311 CheckSum_ABS3_0x137 0 " Valid values " ;
VAL_ 311 VehSpdVld_0x137 0 " Invalid " 1 " Valid " ;
VAL_ 311 VehSpd_0x137 0 " Valid values " 5334 " Reserved " ;
VAL_ 311 ABSActv_0x137 0 " Not active " 1 " Active " ;
VAL_ 311 RollingCounter_ABS3_0x137 0 " Valid value " 15 " Invalid value " ;
VAL_ 315 CheckSum_ABS1_0x13B 0 " Valid values " ;
VAL_ 315 FLWheelDriveDirection_0x13B 0 " Invalid " 1 " Forward " 2 " Backward " 3 " Stop " ;
VAL_ 315 FLWheelSpdVld_0x13B 0 " Invalid " 1 " Valid " ;
VAL_ 315 FLWheelSpd_0x13B 0 " Valid values " 5334 " Reserved " ;
VAL_ 315 FRWheelDriveDirection_0x13B 0 " Invalid " 1 " Forward " 2 " Backward " 3 " Stop " ;
VAL_ 315 FRWheelSpdVld_0x13B 0 " Invalid " 1 " Valid " ;
VAL_ 315 FRWheelSpd_0x13B 0 " Valid values " 5334 " Reserved " ;
VAL_ 315 RollingCounter_ABS1_0x13B 0 " Valid value " 15 " Invalid value " ;
VAL_ 315 EPBErrSts_0x13B 0 " Undefined " 1 " No Error " 2 " Error " 3 " Diagnosis " ;
VAL_ 315 EPBSts_0x13B 0 " Released " 1 " Closed " 2 " In progress " 3 " unknown " ;
VAL_ 315 CheckSum_ABS2_0x13B 0 " Valid values " ;
VAL_ 315 RLWheelDriveDirection_0x13B 0 " Invalid " 1 " Forward " 2 " Backward " 3 " Stop " ;
VAL_ 315 RLWheelSpdVld_0x13B 0 " Invalid " 1 " Valid " ;
VAL_ 315 RLWheelSpd_0x13B 0 " Valid values " 5334 " Reserved " ;
VAL_ 315 RRWheelDriveDirection_0x13B 0 " Invalid " 1 " Forward " 2 " Backward " 3 " Stop " ;
VAL_ 315 RRWheelSpdVld_0x13B 0 " Invalid " 1 " Valid " ;
VAL_ 315 RRWheelSpd_0x13B 0 " Valid values " 5334 " Reserved " ;
VAL_ 315 RollingCounter_ABS2_0x13B 0 " Valid value " 15 " Invalid value " ;
VAL_ 793 DrvDoorSts 0 " Closed " 1 " Open " ;
VAL_ 793 LRDoorSts 0 " Closed " 1 " Open " ;
VAL_ 793 PassengerDoorSts 0 " Closed " 1 " Open " ;
VAL_ 793 RRDoorSts 0 " Closed " 1 " Open " ;
VAL_ 671 RSDS_LLEDSts 0 " No Error " 1 " Error " ;
VAL_ 671 RSDS_RLEDSts 0 " No Error " 1 " Error " ;
VAL_ 661 SysPowerMod 0 " OFF " 1 " ACC (reserved) " 2 " ON " 3 " Crank " ;
VAL_ 661 SysPowerModVld 0 " Invalid " 1 " Valid " ;
VAL_ 627 TrailerSts 0 " Trailer off " 1 " Trailer on " ;
VAL_ 357 LTurnLmpSwtSts 0 " OFF " 1 " ON " ;
VAL_ 357 RTurnLmpSwtSts 0 " OFF " 1 " ON " ;
VAL_ 161 Checksum_CSA2 0 " Valid values " ;
VAL_ 161 SteerWheelAng 0 " Valid value " 7801 " Reserved " 32767 " Invalid " ;
VAL_ 161 SteerWheelAngSign 0 " Left (Positive) " 1 " Right (Negative) " ;
VAL_ 161 SteerWheelSpd 0 " Valid value " 10161 " Reserved " 32767 " Invalid " ;
VAL_ 161 SteerWheelSpdSign 0 " Left (Positive) " 1 " Right (Negative) " ;
VAL_ 161 SAS_Sts 0 " SAS Angle And Speed Correct " 1 " SAS Not Calibrated " 2 " Intermittent Error Detected " 3 " Permanent Error Detected " ;
VAL_ 161 Rollingcounter_CSA2 0 " Valid value " 15 " Invalid value " ;
VAL_ 714 RSDS_Driver_LED_Sts 0 " no error " 1 " error " ;
VAL_ 717 RSDS_Pass_LED_Sts 0 " no error " 1 " error " ;
VAL_ 581 CheckSum_ABM2 0 " Valid values " ;
VAL_ 581 VehLgtAccel 0 " Valid Value " 44067 " Reserved " ;
VAL_ 581 VehLatAccel 0 " Valid Value " 44067 " Reserved " ;
VAL_ 581 VehYawRate 0 " Valid Value " 17442 " Reserved " ;
VAL_ 581 VehLgtAccelVld 0 " Invalid " 1 " Valid " ;
VAL_ 581 VehLatAccelVld 0 " Invalid " 1 " Valid " ;
VAL_ 581 VehDynYawRateVld 0 " Invalid " 1 " Valid " ;
VAL_ 581 RollingCounter_ABM2 0 " Valid value " 15 " Invalid value " ;
VAL_ 639 IP_VehTotDistance 0 " 0-9999999-km " 10000000 " Reserved " 16777215 " Invalid " ;
VAL_ 639 IP_VehTotDistanceValid 0 " Invalid " 1 " Valid " ;
VAL_ 707 DOWSwtReq 0 " OFF " 1 " ON " ;
VAL_ 707 LCASwtReq 0 " OFF " 1 " ON " ;
VAL_ 707 RCTASwtReq 0 " OFF " 1 " ON " ;
VAL_ 707 RCTABrkSwtReq 0 " OFF " 1 " ON " ;
VAL_ 707 RCWSwtReq 0 " OFF " 1 " ON " ;
VAL_ 707 FCW_SnvtySet 0 " Normal " 1 " High sensitivity " 2 " Low sensitivity " 3 " Reserved " ;
VAL_ 707 FCTASwtReq 0 " OFF " 1 " ON " ;
VAL_ 707 FCTABrkSwtReq 0 " OFF " 1 " ON " ;
VAL_ 258 AccelPedlPosnDiagc 0 " Valid values  " ;
VAL_ 625 AccelPedalPosnVldty 0 " Invalid " 1 " Valid " 2 " Init value " 3 " Reserved " ;
VAL_ 625 EngState 0 " Stopped " 1 " Cranking " 2 " Running " 3 " Stalling " ;
VAL_ 561 CheckSum_ABS1 0 " Valid values " ;
VAL_ 561 FLWheelDriveDirection 0 " Invalid " 1 " Forward " 2 " Backward " 3 " Stop " ;
VAL_ 561 FLWheelSpdVld 0 " Invalid " 1 " Valid " ;
VAL_ 561 FLWheelSpd 0 " Valid values " 5334 " Reserved " ;
VAL_ 561 FRWheelDriveDirection 0 " Invalid " 1 " Forward " 2 " Backward " 3 " Stop " ;
VAL_ 561 FRWheelSpdVld 0 " Invalid " 1 " Valid " ;
VAL_ 561 FRWheelSpd 0 " Valid values " 5334 " Reserved " ;
VAL_ 561 RollingCounter_ABS1 0 " Valid value " 15 " Invalid value " ;
VAL_ 582 CheckSum_ABS2 0 " Valid values " ;
VAL_ 582 RLWheelDriveDirection 0 " Invalid " 1 " Forward " 2 " Backward " 3 " Stop " ;
VAL_ 582 RLWheelSpdVld 0 " Invalid " 1 " Valid " ;
VAL_ 582 RLWheelSpd 0 " Valid values " 5334 " Reserved " ;
VAL_ 582 RRWheelDriveDirection 0 " Invalid " 1 " Forward " 2 " Backward " 3 " Stop " ;
VAL_ 582 RRWheelSpdVld 0 " Invalid " 1 " Valid " ;
VAL_ 582 RRWheelSpd 0 " Valid values " 5334 " Reserved " ;
VAL_ 582 RollingCounter_ABS2 0 " Valid value " 15 " Invalid value " ;
VAL_ 613 CheckSum_ABS3 0 " Valid values " ;
VAL_ 613 VehSpdVld 0 " Invalid " 1 " Valid " ;
VAL_ 613 VehSpd 0 " Valid values " 5334 " Reserved " ;
VAL_ 613 ABSActv 0 " Not active " 1 " Active " ;
VAL_ 613 RollingCounter_ABS3 0 " Valid value " 15 " Invalid value " ;
VAL_ 363 EPBErrSts 0 " Undefined " 1 " No Error " 2 " Error " 3 " Diagnosis " ;
VAL_ 363 EPBSts 0 " Released " 1 " Closed " 2 " In progress " 3 " unknown " ;
VAL_ 329 CheckSum_ESP1 0 " Valid values " ;
VAL_ 329 ESPFuncOffSts 0 " Available/On " 1 " Unavailable/Off " ;
VAL_ 329 ESPFailSts 0 " No failure " 1 " Failure " ;
VAL_ 329 ESP_MasterCylBrkPressVld 0 " Invalid " 1 " Valid " ;
VAL_ 329 MSRActv 0 " Not active " 1 " Active " ;
VAL_ 329 VDCActv 0 " Not active " 1 " Active " ;
VAL_ 329 PTCActv 0 " Not active " 1 " Active " ;
VAL_ 329 BTCActv 0 " Not active " 1 " Active " ;
VAL_ 329 ESP_MasterCylBrkPress 0 " Valid value " 14961 " Reserved " ;
VAL_ 329 RollingCounter_ESP1 0 " Valid value " 15 " Invalid value " ;
VAL_ 325 ESP_DiagActv 0 "ESP diagnosis is inactive" 1 "ESP diagnosis is active" ;
VAL_ 325 NoBrkForce 0 " EXist brake force " 1 " No brake force " ;
VAL_ 325 VehStandstill 0 " Not standstill " 1 " Standstill " 2 " Invalid (short unavailability, maX 3s) " 3 " Reserved " ;
VAL_ 325 AEBIBActv 0 " Not active " 1 " Active " ;
VAL_ 325 AEBBAActv 0 " Not active " 1 " Active " ;
VAL_ 325 HDCCtrl 0 " OFF " 1 " On active braking " 2 " On not active braking " 3 " Reserved " ;
VAL_ 325 CTABrkAvailable 0 " Not Available " 1 " Available " ;
VAL_ 325 BrkDskOvrheatd 0 " Not high " 1 " Temp too high " ;
VAL_ 325 AEBAvailable 0 " Unusable " 1 " Usable " ;
VAL_ 325 ABPAvailable 0 " Unusable " 1 " Usable " ;
VAL_ 325 ABPActv 0 " Not active " 1 " Active " ;
VAL_ 325 ABAavailable 0 " Unusable " 1 " Usable " ;
VAL_ 325 ABAactv 0 " Not active " 1 " Active " ;
VAL_ 96 HCU_BrkPedalSts 0 " not pressed " 1 " pressed " 2 " reserved " 3 " error " ;
VAL_ 96 HCU_BrkPedalStsValid 0 " Invalid values " 1 " Valid values " ;
VAL_ 96 HCU_AccelPedalPosn_Diag 0 " Vaild value " ;
VAL_ 96 HCU_AccelPedalPosn_DiagValid 0 " Invaild " 1 " Vaild " ;
VAL_ 96 HCU_PowertrainSts 0 " Sleep " 1 " Initialize Mode " 2 " power up " 3 " power down " 4 " Home " 5 " run " 6 " Charging " 7 " Cellphone AC " 8 " Limphome  " 9 " Emergency Mode  " 10 " V2L " 11 " Prepare Sleep " 12 " ready " 13 " LV Charging " 14 " LT Charging " 15 " IL heating " 16 " Thermal run away " 17 " End of line " 18 " BattTempKeep " 19 " Reserved " ;
VAL_ 288 IB_BrkPedalAppld 0 " Not applied " 1 " Applied " ;
VAL_ 288 IB_BrkPedalAppldVld 0 " Not initialized " 1 " Normal " 2 " Faulty " 3 " Reserved " ;
VAL_ 174 MCU_ActRotSpd 0 " Valid " 65535 " Invalid " ;
VAL_ 537 VCU_GearSts 0 " Zero " 1 " P " 2 " R " 3 " N " 4 " D " 5 " S " 6 " E " 7 " Reserved " ;
VAL_ 537 VCU_GearStsVld 0 " Invalid " 1 " Valid " ;
VAL_ 1305 Destination_HC_NM 1 "GW" 2 "PEPS" 3 "ESCL" 4 "LRSDS" 5 "RRSDS" 6 "BCM" 7 "Trailer" 8 "T-Box" 9 "CMS" 10 "AC" 11 "SCM" 12 "DSM" 13 "DDCM" 14 "PDCM" 15 "HUT" 16 "HCM" 17 "AC_RCP" 18 "TPMS" 32 "ACU" 33 "HCU" 34 "OBC" 35 "BMS" 36 "MCU" 37 "BSG" ;
VAL_ 1305 OpCode_HC_NM 1 "Alive" 2 "ring" 4 "limphome" 18 "ring_sleep_ind" 20 "limphome_sleep_ind" 50 "ring_sleep_ack" ;
VAL_ 1308 Destination_IDC_L3_NM 1 "GW" 2 "PEPS" 3 "ESCL" 4 "LRSDS" 5 "RRSDS" 6 "BCM" 7 "Trailer" 8 "T-Box" 9 "CMS" 10 "AC" 11 "SCM" 12 "DSM" 13 "DDCM" 14 "PDCM" 15 "HUT" 16 "HCM" 17 "AC_RCP" 18 "TPMS" 32 "ACU" 33 "HCU" 34 "OBC" 35 "BMS" 36 "MCU" 37 "BSG" ;
VAL_ 1308 OpCode_IDC_L3_NM 1 "Alive" 2 "ring" 4 "limphome" 18 "ring_sleep_ind" 20 "limphome_sleep_ind" 50 "ring_sleep_ack" ;
VAL_ 1309 Destination_RRR_NM 1 "GW" 2 "PEPS" 3 "ESCL" 4 "LRSDS" 5 "RRSDS" 6 "BCM" 7 "Trailer" 8 "T-Box" 9 "CMS" 10 "AC" 11 "SCM" 12 "DSM" 13 "DDCM" 14 "PDCM" 15 "HUT" 16 "HCM" 17 "AC_RCP" 18 "TPMS" 32 "ACU" 33 "HCU" 34 "OBC" 35 "BMS" 36 "MCU" 37 "BSG" ;
VAL_ 1309 OpCode_RRR_NM 1 "Alive" 2 "ring" 4 "limphome" 18 "ring_sleep_ind" 20 "limphome_sleep_ind" 50 "ring_sleep_ack" ;
VAL_ 1310 Destination_SRR_L_NM 1 "GW" 2 "PEPS" 3 "ESCL" 4 "LRSDS" 5 "RRSDS" 6 "BCM" 7 "Trailer" 8 "T-Box" 9 "CMS" 10 "AC" 11 "SCM" 12 "DSM" 13 "DDCM" 14 "PDCM" 15 "HUT" 16 "HCM" 17 "AC_RCP" 18 "TPMS" 32 "ACU" 33 "HCU" 34 "OBC" 35 "BMS" 36 "MCU" 37 "BSG" ;
VAL_ 1310 OpCode_SRR_L_NM 1 "Alive" 2 "ring" 4 "limphome" 18 "ring_sleep_ind" 20 "limphome_sleep_ind" 50 "ring_sleep_ack" ;
VAL_ 1311 Destination_SRR_R_NM 1 "GW" 2 "PEPS" 3 "ESCL" 4 "LRSDS" 5 "RRSDS" 6 "BCM" 7 "Trailer" 8 "T-Box" 9 "CMS" 10 "AC" 11 "SCM" 12 "DSM" 13 "DDCM" 14 "PDCM" 15 "HUT" 16 "HCM" 17 "AC_RCP" 18 "TPMS" 32 "ACU" 33 "HCU" 34 "OBC" 35 "BMS" 36 "MCU" 37 "BSG" ;
VAL_ 1311 OpCode_SRR_R_NM 1 "Alive" 2 "ring" 4 "limphome" 18 "ring_sleep_ind" 20 "limphome_sleep_ind" 50 "ring_sleep_ack" ;
VAL_ 1281 Destination_GW_NM 1 "GW" 2 "PEPS" 3 "ESCL" 4 "LRSDS" 5 "RRSDS" 6 "BCM" 7 "Trailer" 8 "T-Box" 9 "CMS" 10 "AC" 11 "SCM" 12 "DSM" 13 "DDCM" 14 "PDCM" 15 "HUT" 16 "HCM" 17 "AC_RCP" 18 "TPMS" 32 "ACU" 33 "HCU" 34 "OBC" 35 "BMS" 36 "MCU" 37 "BSG" ;
VAL_ 1281 OpCode_GW_NM 1 "Alive" 2 "ring" 4 "limphome" 18 "ring_sleep_ind" 20 "limphome_sleep_ind" 50 "ring_sleep_ack" ;
VAL_ 301 EB_AEBIBActv 0 " Not active " 1 " Active " ;
VAL_ 301 EB_AEBBAActv 0 " Not active " 1 " Active " ;
VAL_ 301 EB_AEBAvailable 0 " Unusable " 1 " Usable " ;
VAL_ 301 EB_ABPAvailable 0 " Unusable " 1 " Usable " ;
VAL_ 301 EB_ABPActv 0 " Not active " 1 " Active " ;
VAL_ 301 EB_CTABrkAvailable 0 " Not Available " 1 " Available " ;
VAL_ 1136 Sync_CRC_0x470 0 " Valid value " ;
VAL_ 1136 Sync_OVS_0x470 0 " Valid value " ;
VAL_ 1136 Sync_Resd_0x470 0 " Valid value " ;
VAL_ 1136 Sync_Counter_0x470 0 " Valid value " ;
VAL_ 1136 Sync_SGW_0x470 0 " Valid value " ;
VAL_ 1136 Sync_SyncTime_0x470 0 " Valid value " ;
VAL_ 1136 Sync_TimeDomain_0x470 0 " Valid value " ;
VAL_ 1136 Sync_Type_0x470 0 " Valid value " ;
VAL_ 778 RCTA_B_TTC 0 " No Display " 1 " valid value " ;
VAL_ 778 BSD_LCA_Left_TTC 0 " No Display " 1 " valid value " ;
VAL_ 778 RCW_TTC 0 " No Display " 1 " valid value " ;
VAL_ 778 BSD_LCA_Right_TTC 0 " No Display " 1 " valid value " ;
VAL_ 778 RSDS_LeTgt_01_dy 0 " Valid Value " 81 " Reserved " ;
VAL_ 778 RSDS_LeTgt_01 0 " No target " 1 " target detected " ;
VAL_ 778 RSDS_LeTgt_02 0 " No target " 1 " target detected " ;
VAL_ 778 RSDS_LeTgt_01_dx 0 " Valid Value " 951 " Reserved " ;
VAL_ 778 RSDS_LeTgt_02_dx 0 " Valid Value " 951 " Reserved " ;
VAL_ 778 RSDS_RiTgt_01 0 " No target " 1 " target detected " ;
VAL_ 778 RSDS_LeTgt_02_dy 0 " Valid Value " 81 " Reserved " ;
VAL_ 778 RSDS_RiTgt_01_dx 0 " Valid Value " 951 " Reserved " ;
VAL_ 778 RSDS_RiTgt_02 0 " No target " 1 " target detected " ;
VAL_ 778 RSDS_RiTgt_01_dy 0 " Valid Value " 81 " Reserved " ;
VAL_ 778 RSDS_RiTgt_02_dx 0 " Valid Value " 951 " Reserved " ;
VAL_ 778 RSDS_MidTgt_01 0 " No target " 1 " target detected " ;
VAL_ 778 RSDS_RiTgt_02_dy 0 " Valid Value " 81 " Reserved " ;
VAL_ 778 RSDS_MidTgt_01_dx 0 " Valid Value " 951 " Reserved " ;
VAL_ 778 RSDS_MidTgt_02 0 " No target " 1 " target detected " ;
VAL_ 778 RSDS_MidTgt_01_dy 0 " Valid Value " 81 " Reserved " ;
VAL_ 778 RSDS_MidTgt_02_dx 0 " Valid Value " 951 " Reserved " ;
VAL_ 778 RSDS_MidTgt_02_dy 0 " Valid Value " 81 " Reserved " ;
VAL_ 778 LCA_LeTgt_01_Type 0 " Initial_value " 1 " Unknown " 2 " Pedestrian " 3 " Two_wheelers " 4 " Car " 5 " Truck " ;
VAL_ 778 RCTA_LeTgt_02_Type 0 " Initial_value " 1 " Unknown " 2 " Pedestrian " 3 " Two_wheelers " 4 " Car " 5 " Truck " ;
VAL_ 778 LCA_RiTgt_01_Type 0 " Initial_value " 1 " Unknown " 2 " Pedestrian " 3 " Two_wheelers " 4 " Car " 5 " Truck " ;
VAL_ 778 RCTA_RiTgt_02_Type 0 " Initial_value " 1 " Unknown " 2 " Pedestrian " 3 " Two_wheelers " 4 " Car " 5 " Truck " ;
VAL_ 778 RCW_MidTgt_01_Type 0 " Initial_value " 1 " Unknown " 2 " Pedestrian " 3 " Two_wheelers " 4 " Car " 5 " Truck " ;
VAL_ 778 RCTB_MidTgt_02_Type 0 " Initial_value " 1 " Unknown " 2 " Pedestrian " 3 " Two_wheelers " 4 " Car " 5 " Truck " ;
VAL_ 778 LCA_LeTgt_01_Vx 0 " Initial_value " ;
VAL_ 778 RCTA_LeTgt_02_Vx 0 " Initial_value " ;
VAL_ 778 LCA_RiTgt_01_Vx 0 " Initial_value " ;
VAL_ 778 RCTA_RiTgt_02_Vx 0 " Initial_value " ;
VAL_ 778 RCW_MidTgt_01_Vx 0 " Initial_value " ;
VAL_ 778 RCTB_MidTgt_02_Vx 0 " Initial_value " ;
VAL_ 778 LCA_LeTgt_01_Vy 0 " Initial_value " ;
VAL_ 778 RCTA_LeTgt_02_Vy 0 " Initial_value " ;
VAL_ 778 LCA_RiTgt_01_Vy 0 " Initial_value " ;
VAL_ 778 RCTA_RiTgt_02_Vy 0 " Initial_value " ;
VAL_ 778 RCW_MidTgt_01_Vy 0 " Initial_value " ;
VAL_ 778 RCTB_MidTgt_02_Vy 0 " Initial_value " ;
VAL_ 367 RSDS_ObjRelAccelY_Le 0 " Valid values " ;
VAL_ 367 Checksum_RSDS_R_2 0 " Valid value " ;
VAL_ 367 RSDS_BrkgReq 0 " No Request " 1 " Request " ;
VAL_ 367 RSDS_Brk_ErrSts 0 " No error  " 1 " Error  " ;
VAL_ 367 RSDS_IPSoundReq 0 " No warning " 1 " Warning level 1£®2Hz…˘“Ù£© " 2 " Warning level 2£®4Hz…˘“Ù£© " 3 " Warning level 3£®≥£œÏ£© " ;
VAL_ 367 RSDS_LEDLightReqRight 0 " No warning " 1 " Warning level 1£®LED ≥£¡¡£© " 2 " Warning level 2£®LED 2Hz…¡À∏£© " 3 " Warning level 3£®LED 4Hz…¡À∏£© " ;
VAL_ 367 RSDS_LEDLightReqLeft 0 " No warning " 1 " Warning level 1£®LED ≥£¡¡£© " 2 " Warning level 2£®LED 2Hz…¡À∏£© " 3 " Warning level 3£®LED 4Hz…¡À∏£© " ;
VAL_ 367 RSDS_BrkgReqVal 0 " Valid value " ;
VAL_ 367 DOW_warningReqleft 0 " No warning " 1 " Warning level 1 " 2 " Warning level 2 " 3 " Reserved " ;
VAL_ 367 DOW_warningReqRight 0 " No warning " 1 " Warning level 1 " 2 " Warning level 2 " 3 " Reserved " ;
VAL_ 367 BSD_LCA_warningReqleft 0 " No warning " 1 " Warning level 1 " 2 " Warning level 2 " 3 " Reserved " ;
VAL_ 367 BSD_LCA_warningReqRight 0 " No warning " 1 " Warning level 1 " 2 " Warning level 2 " 3 " Reserved " ;
VAL_ 367 RSDS_RCW_Trigger 0 " No warning " 1 " RCW level 1 " 2 " RCW level 2 " 3 " Reserved " ;
VAL_ 367 RSDS_RCTAResp 0 " OFF " 1 " ON " ;
VAL_ 367 RSDS_RCWResp 0 " OFF " 1 " ON " ;
VAL_ 367 RSDS_DOWResp 0 " OFF " 1 " ON " ;
VAL_ 367 RSDS_LCAResp 0 " OFF " 1 " ON " ;
VAL_ 367 RSDS_TrailerSts 0 " None " 1 " Trailer " ;
VAL_ 367 RSDS_BliSts 0 " No Blindness " 1 " Blindness " ;
VAL_ 367 RSDS_BrkgTrig 0 " Not tirggered " 1 " Triggered " ;
VAL_ 367 RSDS_ErrSts 0 " No Error " 1 " Error " ;
VAL_ 367 RollingCounter_RSDS_R_2 0 " Valid value " 15 " Invalid value " ;
VAL_ 367 RCTA_warningReqLeft 0 " No warning " 1 " Warning level 2 " ;
VAL_ 367 RCTA_warningReqRight 0 " No warning " 1 " Warning level 2 " ;
VAL_ 367 RSDS_CTA_Actv 0 " Not active " 1 " Active " ;
VAL_ 367 RSDS_RCTABrkResp 0 " OFF " 1 " ON " ;
VAL_ 367 Checksum_RSDS_R_3 0 " Valid value " ;
VAL_ 367 ObjIDLe 0 " Valid value " ;
VAL_ 367 LeTarSts 0 " Target Invalid " 1 " Target Valid " 2 " No target " 3 " Reserved " ;
VAL_ 367 ObjLgtPosnCurvLe 0 " Valid value " ;
VAL_ 367 ObjLatPosnCurvLe 0 " Valid value " ;
VAL_ 367 ObjLgtSpdCurvLe 0 " Valid value " ;
VAL_ 367 ObjLatSpdCurvLe 0 " Valid value " ;
VAL_ 367 RollingCounter_RSDS_R_3 0 " Valid value " 15 " Invalid value " ;
VAL_ 367 ObjTTCLe 0 " Valid value " ;
VAL_ 367 Checksum_RSDS_R_4 0 " Valid value " ;
VAL_ 367 ObjStatyLe 0 " Stationary " 1 " Not Stationary " ;
VAL_ 367 ObjWidthLe 0 " Valid value " ;
VAL_ 367 ObjLenLe 0 " Valid value " ;
VAL_ 367 ObjRinRi 0 " Valid value " ;
VAL_ 367 ObjStsLe 0 " Invalid " 1 " New–¬ƒø±Í " 2 " Mature≥… Ïƒø±Í " 3 " Coastedª¨––µƒ " ;
VAL_ 367 ZoneIndLe 0 " No Object in the Zone " 1 " Object in BSW Zone " 2 " Object in CVW Zone " 3 " Object in the Shared Zone " ;
VAL_ 367 ObjStsRi 0 " Invalid " 1 " New " 2 " Mature " 3 " Coasted " ;
VAL_ 367 ZoneIndRi 0 " No Object in the Zone " 1 " Object in BSW Zone " 2 " Object in CVW Zone " 3 " Object in the Shared Zone " ;
VAL_ 367 ObjStatyRi 0 " Stationary " 1 " Not Stationary " ;
VAL_ 367 ObjWidthRi 0 " Valid value " ;
VAL_ 367 RollingCounter_RSDS_R_4 0 " Valid value " 15 " Invalid value " ;
VAL_ 367 Checksum_RSDS_R_5 0 " Valid value " ;
VAL_ 367 ObjIDRi 0 " Valid value " ;
VAL_ 367 RiTarSts 0 " Target Invalid " 1 " Target Valid " 2 " No target " 3 " Reserved " ;
VAL_ 367 ObjLgtPosnCurvRi 0 " Valid value " ;
VAL_ 367 ObjLatPosnCurvRi 0 " Valid value " ;
VAL_ 367 ObjLgtSpdCurvRi 0 " Valid value " ;
VAL_ 367 ObjLatSpdCurvRi 0 " Valid value " ;
VAL_ 367 RollingCounter_RSDS_R_5 0 " Valid value " 15 " Invalid value " ;
VAL_ 367 ObjTTCRi 0 " Valid value " ;
VAL_ 367 RSDS_ObjDistXStd_Le 0 " valid value " ;
VAL_ 367 RSDS_ObjRelVelXStd_Le 0 " valid value " ;
VAL_ 367 RSDS_ObjDistYStd_Le 0 " valid value " ;
VAL_ 367 RSDS_ObjRelVelYStd_Le 0 " valid value " ;
VAL_ 367 RSDS_ObjRAccelYStd_Le 0 " valid value " ;
VAL_ 367 RSDS_ObjRAccelXStd_Le 0 " valid value " ;
VAL_ 367 RSDS_ObjDistYStd_Ri 0 " valid value " ;
VAL_ 367 RSDS_ObjDistXStd_Ri 0 " valid value " ;
VAL_ 367 RSDS_ObjRelVelXStd_Ri 0 " valid value " ;
VAL_ 367 RSDS_ObjRelVelYStd_Ri 0 " valid value " ;
VAL_ 367 RSDS_ObjRAccelYStd_Ri 0 " valid value " ;
VAL_ 367 RSDS_ObjRAccelXStd_Ri 0 " valid value " ;
VAL_ 367 RSDS_ObjRelAccelX_Le 0 " Valid values " ;
VAL_ 367 RSDS_ObjRelAccelX_Ri 0 " Valid values " ;
VAL_ 367 RSDS_ObjRelAccelY_Ri 0 " Valid values " ;
VAL_ 367 BSD_State 0 " Initial_value " 1 " OFF " 2 " Standby " 3 " Active " 4 " Passive " 5 " Fault " 6 " Reserved " ;
VAL_ 367 LCA_State 0 " Initial_value " 1 " OFF " 2 " Standby " 3 " Active " 4 " Passive " 5 " Fault " 6 " Reserved " ;
VAL_ 367 DOW_State 0 " Initial_value " 1 " OFF " 2 " Standby " 3 " Active " 4 " Passive " 5 " Fault " 6 " Reserved " ;
VAL_ 367 RCW_State 0 " Initial_value " 1 " OFF " 2 " Standby " 3 " Active " 4 " Passive " 5 " Fault " 6 " Reserved " ;
VAL_ 367 RCTA_State 0 " Initial_value " 1 " OFF " 2 " Standby " 3 " Active " 4 " Passive " 5 " Fault " 6 " Reserved " ;
VAL_ 367 RCTB_State 0 " Initial_value " 1 " OFF " 2 " Standby " 3 " Active " 4 " Passive " 5 " Fault " 6 " Hold " 7 " Reserved " ;
VAL_ 880 Time_Hour 0 " Valid hour " 24 " Reserved " 31 " Invalid " ;
VAL_ 880 TimeMod 0 " 24 " 1 " 12 " ;
VAL_ 880 TimeIndcn 0 " am " 1 " pm " ;
VAL_ 880 Time_Minutes 0 " Valid minute " 60 " Reserved " 63 " Invalid " ;
VAL_ 880 Time_Second 0 " Valid second " 60 " Reserved " 63 " Invalid " ;
VAL_ 880 Time_Year_Right 0 " Valid year " 10 " Reserved " 15 " Invalid " ;
VAL_ 880 Time_Year_Left 0 " Valid year " 10 " Reserved " 15 " Invalid " ;
VAL_ 880 Time_Month 0 " Invalid " 1 " Valid month " 13 " Reserved " ;
VAL_ 880 Time_Day 0 " Invalid " 1 " Valid day " ;
VAL_ 302 InpRodStkSts 0 " Valid " 1 " Invalid " ;
VAL_ 302 PushrodStauts 0 " Not_Pressed/Init/Default " 1 " Pressed " 2 " Reserved " 3 " Error " ;
VAL_ 302 InpRodStk 0 " Valid " ;
VAL_ 181 VCU_ActAccrPedlRat 0 " Valid " ;
VAL_ 181 VCU_APedlPosVld 0 " Invalid " 1 " Valid " ;
VAL_ 181 VCU_BrkPedlSts 0 " No_Active " 1 " Brake_Active " 2 " Invalid " 3 " Reserved " ;
VAL_ 181 HCU_BrkPedalStsValid 0 " Invalid_Value " 1 " Valid_Value " ;
VAL_ 1091 RSDS_R_hdr_ErrorStatus 0 " No error " 1 " Not Defined " 2 " Misalignment_elevation " 3 " Misalignment_azimuth " 4 " Temporary failure " 5 " Permanent failure " 6 " Voltage_error " 7 " Production_mode " 8 " EOL_error " 9 " Calibration parameter_error " 10 " Radar not match " 11 " Reserved " ;
VAL_ 1091 RSDS_R_hdr_TimeStamp 0 " Valid values " 67562888 " Reserved " ;
VAL_ 1091 RSDS_R_ObjID_1 0 " Valid values " ;
VAL_ 1091 RSDS_R_ObjExistProb_1 0 " Valid values " ;
VAL_ 1091 RSDS_R_ObjObstacleProb_1 0 " Valid values " ;
VAL_ 1091 RSDS_R_ObjDistX_1 0 " Valid values " 4080 " Reserved " ;
VAL_ 1091 RSDS_R_ObjDistY_1 0 " Valid values " ;
VAL_ 1091 RSDS_R_ObjRelVelX_1 0 " Valid values " 8174 " Reserved " ;
VAL_ 1091 RSDS_R_ObjRelVelY_1 0 " Valid values " 8174 " Reserved " ;
VAL_ 1091 RSDS_R_ObjRelAccelX_1 0 " Valid values " ;
VAL_ 1091 RSDS_R_ObjRelAccelY_1 0 " Valid values " ;
VAL_ 1091 RSDS_R_ObjDistXStd_1 0 " Valid values " ;
VAL_ 1091 RSDS_R_ObjDistYStd_1 0 " Valid values " ;
VAL_ 1091 RSDS_R_ObjRelVelXStd_1 0 " Valid values " ;
VAL_ 1091 RSDS_R_ObjRelVelYStd_1 0 " Valid values " ;
VAL_ 1091 RSDS_R_ObjRAccelXStd_1 0 " Valid values " ;
VAL_ 1091 RSDS_R_ObjRAccelYStd_1 0 " Valid values " ;
VAL_ 1091 RSDS_R_VFC_ObjWidth_1 0 " Valid values " 501 " Reserved " ;
VAL_ 1091 RSDS_R_VFC_ObjLength_1 0 " Valid values " 401 " Reserved " ;
VAL_ 1091 RSDS_R_ObjID_2 0 " Valid values " ;
VAL_ 1091 RSDS_R_ObjExistProb_2 0 " Valid values " ;
VAL_ 1091 RSDS_R_ObjObstacleProb_2 0 " Valid values " ;
VAL_ 1091 RSDS_R_ObjDistX_2 0 " Valid values " 4080 " Reserved " ;
VAL_ 1091 RSDS_R_ObjDistY_2 0 " Valid values " ;
VAL_ 1091 RSDS_R_ObjRelVelX_2 0 " Valid values " 8174 " Reserved " ;
VAL_ 1091 RSDS_R_ObjRelVelY_2 0 " Valid values " 8174 " Reserved " ;
VAL_ 1091 RSDS_R_ObjRelAccelX_2 0 " Valid values " ;
VAL_ 1091 RSDS_R_ObjRelAccelY_2 0 " Valid values " ;
VAL_ 1091 RSDS_R_ObjDistXStd_2 0 " Valid values " ;
VAL_ 1091 RSDS_R_ObjDistYStd_2 0 " Valid values " ;
VAL_ 1091 RSDS_R_ObjRelVelXStd_2 0 " Valid values " ;
VAL_ 1091 RSDS_R_ObjRelVelYStd_2 0 " Valid values " ;
VAL_ 1091 RSDS_R_ObjRAccelXStd_2 0 " Valid values " ;
VAL_ 1091 RSDS_R_ObjRAccelYStd_2 0 " Valid values " ;
VAL_ 1091 RSDS_R_VFC_ObjWidth_2 0 " Valid values " 501 " Reserved " ;
VAL_ 1091 RSDS_R_VFC_ObjLength_2 0 " Valid values " 401 " Reserved " ;
VAL_ 1091 Checksum22 0 " Valid value " ;
VAL_ 1091 Checksum23 0 " Valid value " ;
VAL_ 1091 Checksum24 0 " Valid value " ;
VAL_ 1091 Checksum26 0 " Valid value " ;
VAL_ 1091 Checksum27 0 " Valid value " ;
VAL_ 1091 Checksum28 0 " Valid value " ;
VAL_ 1091 RollingCounter22 0 " Valid value " 15 " Invalid value " ;
VAL_ 1091 RollingCounter23 0 " Valid value " 15 " Invalid value " ;
VAL_ 1091 RollingCounter24 0 " Valid value " 15 " Invalid value " ;
VAL_ 1091 RollingCounter26 0 " Valid value " 15 " Invalid value " ;
VAL_ 1091 RollingCounter27 0 " Valid value " 15 " Invalid value " ;
VAL_ 1091 RollingCounter28 0 " Valid value " 15 " Invalid value " ;
VAL_ 1091 RSDS_R_ObjMeasured_1 0 " Init " 1 " Measured " 2 " Predicted " 3 " Reserved " ;
VAL_ 1091 RSDS_R_ObjMeasured_2 0 " Init " 1 " Measured " 2 " Predicted " 3 " Reserved " ;
VAL_ 1091 RSDS_R_BLIND 0 " No Blindness " 1 " Blindness " 2 " Reserved " 3 " Reserved " ;
VAL_ 1091 RSDS_R_hdr_TimerStempStatus 0 " Valid value " ;
VAL_ 1091 Checksum25 0 " Valid value " ;
VAL_ 1091 Rollingcounter25 0 " Valid value " 15 " Invalid value " ;
VAL_ 1091 BlockCounter4 0 " Valid value " ;
VAL_ 1091 RSDS_R_hdr_AutosarTimeStamp 0 " Valid values " 1729136740 " Reserved " ;
VAL_ 1092 RSDS_R_ObjID_3 0 " Valid values " ;
VAL_ 1092 RSDS_R_ObjExistProb_3 0 " Valid values " ;
VAL_ 1092 RSDS_R_ObjObstacleProb_3 0 " Valid values " ;
VAL_ 1092 RSDS_R_ObjDistX_3 0 " Valid values " 4080 " Reserved " ;
VAL_ 1092 RSDS_R_ObjDistY_3 0 " Valid values " ;
VAL_ 1092 RSDS_R_ObjRelVelX_3 0 " Valid values " 8174 " Reserved " ;
VAL_ 1092 RSDS_R_ObjRelVelY_3 0 " Valid values " 8174 " Reserved " ;
VAL_ 1092 RSDS_R_ObjRelAccelX_3 0 " Valid values " ;
VAL_ 1092 RSDS_R_ObjRelAccelY_3 0 " Valid values " ;
VAL_ 1092 RSDS_R_ObjDistXStd_3 0 " Valid values " ;
VAL_ 1092 RSDS_R_ObjDistYStd_3 0 " Valid values " ;
VAL_ 1092 RSDS_R_ObjRelVelXStd_3 0 " Valid values " ;
VAL_ 1092 RSDS_R_ObjRelVelYStd_3 0 " Valid values " ;
VAL_ 1092 RSDS_R_ObjRAccelXStd_3 0 " Valid values " ;
VAL_ 1092 RSDS_R_ObjRAccelYStd_3 0 " Valid values " ;
VAL_ 1092 RSDS_R_VFC_ObjWidth_3 0 " Valid values " 501 " Reserved " ;
VAL_ 1092 RSDS_R_VFC_ObjLength_3 0 " Valid values " 401 " Reserved " ;
VAL_ 1092 RSDS_R_ObjID_4 0 " Valid values " ;
VAL_ 1092 RSDS_R_ObjExistProb_4 0 " Valid values " ;
VAL_ 1092 RSDS_R_ObjObstacleProb_4 0 " Valid values " ;
VAL_ 1092 RSDS_R_ObjDistX_4 0 " Valid values " 4080 " Reserved " ;
VAL_ 1092 RSDS_R_ObjDistY_4 0 " Valid values " ;
VAL_ 1092 RSDS_R_ObjRelVelX_4 0 " Valid values " 8174 " Reserved " ;
VAL_ 1092 RSDS_R_ObjRelVelY_4 0 " Valid values " 8174 " Reserved " ;
VAL_ 1092 RSDS_R_ObjRelAccelX_4 0 " Valid values " ;
VAL_ 1092 RSDS_R_ObjRelAccelY_4 0 " Valid values " ;
VAL_ 1092 RSDS_R_ObjDistXStd_4 0 " Valid values " ;
VAL_ 1092 RSDS_R_ObjDistYStd_4 0 " Valid values " ;
VAL_ 1092 RSDS_R_ObjRelVelXStd_4 0 " Valid values " ;
VAL_ 1092 RSDS_R_ObjRelVelYStd_4 0 " Valid values " ;
VAL_ 1092 RSDS_R_ObjRAccelXStd_4 0 " Valid values " ;
VAL_ 1092 RSDS_R_ObjRAccelYStd_4 0 " Valid values " ;
VAL_ 1092 RSDS_R_VFC_ObjWidth_4 0 " Valid values " 501 " Reserved " ;
VAL_ 1092 RSDS_R_VFC_ObjLength_4 0 " Valid values " 401 " Reserved " ;
VAL_ 1092 Checksum29 0 " Valid value " ;
VAL_ 1092 Checksum30 0 " Valid value " ;
VAL_ 1092 Checksum31 0 " Valid value " ;
VAL_ 1092 Checksum33 0 " Valid value " ;
VAL_ 1092 Checksum34 0 " Valid value " ;
VAL_ 1092 Checksum35 0 " Valid value " ;
VAL_ 1092 RollingCounter29 0 " Valid value " 15 " Invalid value " ;
VAL_ 1092 RollingCounter30 0 " Valid value " 15 " Invalid value " ;
VAL_ 1092 RollingCounter31 0 " Valid value " 15 " Invalid value " ;
VAL_ 1092 RollingCounter33 0 " Valid value " 15 " Invalid value " ;
VAL_ 1092 RollingCounter34 0 " Valid value " 15 " Invalid value " ;
VAL_ 1092 RollingCounter35 0 " Valid value " 15 " Invalid value " ;
VAL_ 1092 RSDS_R_ObjMeasured_3 0 " Init " 1 " Measured " 2 " Predicted " 3 " Reserved " ;
VAL_ 1092 RSDS_R_ObjMeasured_4 0 " Init " 1 " Measured " 2 " Predicted " 3 " Reserved " ;
VAL_ 1092 Checksum32 0 " Valid value " ;
VAL_ 1092 Rollingcounter32 0 " Valid value " 15 " Invalid value " ;
VAL_ 1092 BlockCounter5 0 " Valid value " ;
VAL_ 1093 RSDS_R_ObjID_5 0 " Valid values " ;
VAL_ 1093 RSDS_R_ObjExistProb_5 0 " Valid values " ;
VAL_ 1093 RSDS_R_ObjObstacleProb_5 0 " Valid values " ;
VAL_ 1093 RSDS_R_ObjDistX_5 0 " Valid values " 4080 " Reserved " ;
VAL_ 1093 RSDS_R_ObjDistY_5 0 " Valid values " ;
VAL_ 1093 RSDS_R_ObjRelVelX_5 0 " Valid values " 8174 " Reserved " ;
VAL_ 1093 RSDS_R_ObjRelVelY_5 0 " Valid values " 8174 " Reserved " ;
VAL_ 1093 RSDS_R_ObjRelAccelX_5 0 " Valid values " ;
VAL_ 1093 RSDS_R_ObjRelAccelY_5 0 " Valid values " ;
VAL_ 1093 RSDS_R_ObjDistXStd_5 0 " Valid values " ;
VAL_ 1093 RSDS_R_ObjDistYStd_5 0 " Valid values " ;
VAL_ 1093 RSDS_R_ObjRelVelXStd_5 0 " Valid values " ;
VAL_ 1093 RSDS_R_ObjRelVelYStd_5 0 " Valid values " ;
VAL_ 1093 RSDS_R_ObjRAccelXStd_5 0 " Valid values " ;
VAL_ 1093 RSDS_R_ObjRAccelYStd_5 0 " Valid values " ;
VAL_ 1093 RSDS_R_VFC_ObjWidth_5 0 " Valid values " 501 " Reserved " ;
VAL_ 1093 RSDS_R_VFC_ObjLength_5 0 " Valid values " 401 " Reserved " ;
VAL_ 1093 RSDS_R_ObjID_6 0 " Valid values " ;
VAL_ 1093 RSDS_R_ObjExistProb_6 0 " Valid values " ;
VAL_ 1093 RSDS_R_ObjObstacleProb_6 0 " Valid values " ;
VAL_ 1093 RSDS_R_ObjDistX_6 0 " Valid values " 4080 " Reserved " ;
VAL_ 1093 RSDS_R_ObjDistY_6 0 " Valid values " ;
VAL_ 1093 RSDS_R_ObjRelVelX_6 0 " Valid values " 8174 " Reserved " ;
VAL_ 1093 RSDS_R_ObjRelVelY_6 0 " Valid values " 8174 " Reserved " ;
VAL_ 1093 RSDS_R_ObjRelAccelX_6 0 " Valid values " ;
VAL_ 1093 RSDS_R_ObjRelAccelY_6 0 " Valid values " ;
VAL_ 1093 RSDS_R_ObjDistXStd_6 0 " Valid values " ;
VAL_ 1093 RSDS_R_ObjDistYStd_6 0 " Valid values " ;
VAL_ 1093 RSDS_R_ObjRelVelXStd_6 0 " Valid values " ;
VAL_ 1093 RSDS_R_ObjRelVelYStd_6 0 " Valid values " ;
VAL_ 1093 RSDS_R_ObjRAccelXStd_6 0 " Valid values " ;
VAL_ 1093 RSDS_R_ObjRAccelYStd_6 0 " Valid values " ;
VAL_ 1093 RSDS_R_VFC_ObjWidth_6 0 " Valid values " 501 " Reserved " ;
VAL_ 1093 RSDS_R_VFC_ObjLength_6 0 " Valid values " 401 " Reserved " ;
VAL_ 1093 Checksum36 0 " Valid value " ;
VAL_ 1093 Checksum37 0 " Valid value " ;
VAL_ 1093 Checksum38 0 " Valid value " ;
VAL_ 1093 Checksum40 0 " Valid value " ;
VAL_ 1093 Checksum41 0 " Valid value " ;
VAL_ 1093 Checksum42 0 " Valid value " ;
VAL_ 1093 RollingCounter36 0 " Valid value " 15 " Invalid value " ;
VAL_ 1093 RollingCounter37 0 " Valid value " 15 " Invalid value " ;
VAL_ 1093 RollingCounter38 0 " Valid value " 15 " Invalid value " ;
VAL_ 1093 RollingCounter40 0 " Valid value " 15 " Invalid value " ;
VAL_ 1093 RollingCounter41 0 " Valid value " 15 " Invalid value " ;
VAL_ 1093 RollingCounter42 0 " Valid value " 15 " Invalid value " ;
VAL_ 1093 RSDS_R_ObjMeasured_5 0 " Init " 1 " Measured " 2 " Predicted " 3 " Reserved " ;
VAL_ 1093 RSDS_R_ObjMeasured_6 0 " Init " 1 " Measured " 2 " Predicted " 3 " Reserved " ;
VAL_ 1093 Checksum39 0 " Valid value " ;
VAL_ 1093 Rollingcounter39 0 " Valid value " 15 " Invalid value " ;
VAL_ 1093 BlockCounter6 0 " Valid value " ;
VAL_ 1424 RSDS_R_ObjID_1 0 " Valid values " ;
VAL_ 1424 RSDS_R_ObjExistProb_1 0 " Valid values " ;
VAL_ 1424 RSDS_R_ObjObstacleProb_1 0 " Valid values " ;
VAL_ 1424 RSDS_R_ObjDistX_1 0 " Valid values " 4080 " Reserved " ;
VAL_ 1424 RSDS_R_ObjDistY_1 0 " Valid values " ;
VAL_ 1424 RSDS_R_ObjDistXStd_1 0 " Valid values " ;
VAL_ 1424 RSDS_R_ObjType_1 0 " Unknown " 1 " Truck " 2 " Car " 3 " Pedestrian " 4 " Cyclist " 5 " Reserved " ;
VAL_ 1424 RSDS_R_ObjRelVelX_1 0 " Valid values " 8174 " Reserved " ;
VAL_ 1424 RSDS_R_ObjRelVelY_1 0 " Valid values " 8174 " Reserved " ;
VAL_ 1424 RSDS_R_ObjRelAccelX_1 0 " Valid values " ;
VAL_ 1424 RSDS_R_ObjRelAccelY_1 0 " Valid values " ;
VAL_ 1424 RSDS_R_ObjMotionType_1 0 " Int " 1 " Unknown " 2 " Drive " 3 " Stopped " 4 " Stand " 5 " Reserved " 6 " Reserved " 7 " Reserved " ;
VAL_ 1424 RSDS_R_ObjMeasured_1 0 " Init " 1 " Measured " 2 " Predicted " 3 " Reserved " ;
VAL_ 1424 RSDS_R_ObjDistYStd_1 0 " Valid values " ;
VAL_ 1424 RSDS_R_ObjRelVelXStd_1 0 " Valid values " ;
VAL_ 1424 RSDS_R_ObjRelVelYStd_1 0 " Valid values " ;
VAL_ 1424 RSDS_R_ObjRAccelXStd_1 0 " Valid values " ;
VAL_ 1424 RSDS_R_ObjRAccelYStd_1 0 " Valid values " ;
VAL_ 1424 RSDS_R_ObjWidth_1 0 " Valid values " 501 " Reserved " ;
VAL_ 1424 RSDS_R_ObjMotionDirection_1 0 " Init " 1 " Inverse direction " 2 " Same direction " 3 " Cross " 4 " Reserved " 5 " Reserved " 6 " Reserved " 7 " Reserved " ;
VAL_ 1424 RSDS_R_ObjAge_1 0 " Valid_values " ;
VAL_ 1424 RSDS_R_ObjLength_1 0 " Valid values " 401 " Reserved " ;
VAL_ 1424 RSDS_R_ObjHeading_1 0 " Valid values " 4446 " Reserved " ;
VAL_ 1424 RSDS_R_ObjYawrate_1 0 " Valid values " 4446 " Reserved " ;
VAL_ 1424 RSDS_R_ObjRCS_1 0 " Valid_values " ;
VAL_ 1424 RSDS_R_ObjRefPoint_1 0 " Rear " 1 " Rear left " 2 " Left " 3 " Front left " 4 " Front " 5 " Front Right " 6 " Right " 7 " Rear right " ;
VAL_ 1424 RSDS_R_HWATargetValidity_1 0 " NOT HWA Target " 1 " HWA Target " ;
VAL_ 1424 RSDS_R_ObjID_2 0 " Valid values " ;
VAL_ 1424 RSDS_R_ObjExistProb_2 0 " Valid values " ;
VAL_ 1424 RSDS_R_ObjObstacleProb_2 0 " Valid values " ;
VAL_ 1424 RSDS_R_ObjDistX_2 0 " Valid values " 4080 " Reserved " ;
VAL_ 1424 RSDS_R_ObjDistY_2 0 " Valid values " ;
VAL_ 1424 RSDS_R_ObjDistXStd_2 0 " Valid values " ;
VAL_ 1424 RSDS_R_ObjType_2 0 " Unknown " 1 " Truck " 2 " Car " 3 " Pedestrian " 4 " Cyclist " 5 " Reserved " ;
VAL_ 1424 RSDS_R_ObjRelVelX_2 0 " Valid values " 8174 " Reserved " ;
VAL_ 1424 RSDS_R_ObjRelVelY_2 0 " Valid values " 8174 " Reserved " ;
VAL_ 1424 RSDS_R_ObjRelAccelX_2 0 " Valid values " ;
VAL_ 1424 RSDS_R_ObjRelAccelY_2 0 " Valid values " ;
VAL_ 1424 RSDS_R_ObjMotionType_2 0 " Int " 1 " Unknown " 2 " Drive " 3 " Stopped " 4 " Stand " 5 " Reserved " 6 " Reserved " 7 " Reserved " ;
VAL_ 1424 RSDS_R_ObjMeasured_2 0 " Init " 1 " Measured " 2 " Predicted " 3 " Reserved " ;
VAL_ 1424 RSDS_R_ObjDistYStd_2 0 " Valid values " ;
VAL_ 1424 RSDS_R_ObjRelVelXStd_2 0 " Valid values " ;
VAL_ 1424 RSDS_R_ObjRelVelYStd_2 0 " Valid values " ;
VAL_ 1424 RSDS_R_ObjRAccelXStd_2 0 " Valid values " ;
VAL_ 1424 RSDS_R_ObjRAccelYStd_2 0 " Valid values " ;
VAL_ 1424 RSDS_R_ObjWidth_2 0 " Valid values " 501 " Reserved " ;
VAL_ 1424 RSDS_R_ObjMotionDirection_2 0 " Init " 1 " Inverse direction " 2 " Same direction " 3 " Cross " 4 " Reserved " 5 " Reserved " 6 " Reserved " 7 " Reserved " ;
VAL_ 1424 RSDS_R_ObjAge_2 0 " Valid_values " ;
VAL_ 1424 RSDS_R_ObjLength_2 0 " Valid values " 401 " Reserved " ;
VAL_ 1424 RSDS_R_ObjHeading_2 0 " Valid values " 4446 " Reserved " ;
VAL_ 1424 RSDS_R_ObjYawrate_2 0 " Valid values " 4446 " Reserved " ;
VAL_ 1424 RSDS_R_ObjRCS_2 0 " Valid_values " ;
VAL_ 1424 RSDS_R_ObjRefPoint_2 0 " Rear " 1 " Rear left " 2 " Left " 3 " Front left " 4 " Front " 5 " Front Right " 6 " Right " 7 " Rear right " ;
VAL_ 1424 RSDS_R_HWATargetValidity_2 0 " NOT HWA Target " 1 " HWA Target " ;
VAL_ 1424 RSDS_R_SGU1_BlockCounter 0 " Valid value " ;
VAL_ 1424 RSDS_R_SGU1_Checksum1 0 " Valid value " ;
VAL_ 1424 RSDS_R_SGU1_Checksum2 0 " Valid value " ;
VAL_ 1424 RSDS_R_SGU1_Checksum3 0 " Valid value " ;
VAL_ 1424 RSDS_R_SGU1_Checksum4 0 " Valid value " ;
VAL_ 1424 RSDS_R_SGU1_Checksum5 0 " Valid value " ;
VAL_ 1424 RSDS_R_SGU1_Checksum6 0 " Valid value " ;
VAL_ 1424 RSDS_R_SGU1_Checksum7 0 " Valid value " ;
VAL_ 1424 RSDS_R_SGU1_Checksum8 0 " Valid value " ;
VAL_ 1424 RSDS_R_SGU1_RollingCounter1 0 " Valid value " 15 " Invalid value " ;
VAL_ 1424 RSDS_R_SGU1_RollingCounter2 0 " Valid value " 15 " Invalid value " ;
VAL_ 1424 RSDS_R_SGU1_RollingCounter3 0 " Valid value " 15 " Invalid value " ;
VAL_ 1424 RSDS_R_SGU1_RollingCounter4 0 " Valid value " 15 " Invalid value " ;
VAL_ 1424 RSDS_R_SGU1_RollingCounter5 0 " Valid value " 15 " Invalid value " ;
VAL_ 1424 RSDS_R_SGU1_RollingCounter6 0 " Valid value " 15 " Invalid value " ;
VAL_ 1424 RSDS_R_SGU1_RollingCounter7 0 " Valid value " 15 " Invalid value " ;
VAL_ 1424 RSDS_R_SGU1_RollingCounter8 0 " Valid value " 15 " Invalid value " ;
VAL_ 1425 RSDS_R_ObjID_3 0 " Valid values " ;
VAL_ 1425 RSDS_R_ObjExistProb_3 0 " Valid values " ;
VAL_ 1425 RSDS_R_ObjObstacleProb_3 0 " Valid values " ;
VAL_ 1425 RSDS_R_ObjDistX_3 0 " Valid values " 4080 " Reserved " ;
VAL_ 1425 RSDS_R_ObjDistY_3 0 " Valid values " ;
VAL_ 1425 RSDS_R_ObjDistXStd_3 0 " Valid values " ;
VAL_ 1425 RSDS_R_ObjType_3 0 " Unknown " 1 " Truck " 2 " Car " 3 " Pedestrian " 4 " Cyclist " 5 " Reserved " ;
VAL_ 1425 RSDS_R_ObjRelVelX_3 0 " Valid values " 8174 " Reserved " ;
VAL_ 1425 RSDS_R_ObjRelVelY_3 0 " Valid values " 8174 " Reserved " ;
VAL_ 1425 RSDS_R_ObjRelAccelX_3 0 " Valid values " ;
VAL_ 1425 RSDS_R_ObjRelAccelY_3 0 " Valid values " ;
VAL_ 1425 RSDS_R_ObjMotionType_3 0 " Int " 1 " Unknown " 2 " Drive " 3 " Stopped " 4 " Stand " 5 " Reserved " 6 " Reserved " 7 " Reserved " ;
VAL_ 1425 RSDS_R_ObjMeasured_3 0 " Init " 1 " Measured " 2 " Predicted " 3 " Reserved " ;
VAL_ 1425 RSDS_R_ObjDistYStd_3 0 " Valid values " ;
VAL_ 1425 RSDS_R_ObjRelVelXStd_3 0 " Valid values " ;
VAL_ 1425 RSDS_R_ObjRelVelYStd_3 0 " Valid values " ;
VAL_ 1425 RSDS_R_ObjRAccelXStd_3 0 " Valid values " ;
VAL_ 1425 RSDS_R_ObjRAccelYStd_3 0 " Valid values " ;
VAL_ 1425 RSDS_R_ObjWidth_3 0 " Valid values " 501 " Reserved " ;
VAL_ 1425 RSDS_R_ObjMotionDirection_3 0 " Init " 1 " Inverse direction " 2 " Same direction " 3 " Cross " 4 " Reserved " 5 " Reserved " 6 " Reserved " 7 " Reserved " ;
VAL_ 1425 RSDS_R_ObjAge_3 0 " Valid_values " ;
VAL_ 1425 RSDS_R_ObjLength_3 0 " Valid values " 401 " Reserved " ;
VAL_ 1425 RSDS_R_ObjHeading_3 0 " Valid values " 4446 " Reserved " ;
VAL_ 1425 RSDS_R_ObjYawrate_3 0 " Valid values " 4446 " Reserved " ;
VAL_ 1425 RSDS_R_ObjRCS_3 0 " Valid_values " ;
VAL_ 1425 RSDS_R_ObjRefPoint_3 0 " Rear " 1 " Rear left " 2 " Left " 3 " Front left " 4 " Front " 5 " Front Right " 6 " Right " 7 " Rear right " ;
VAL_ 1425 RSDS_R_HWATargetValidity_3 0 " NOT HWA Target " 1 " HWA Target " ;
VAL_ 1425 RSDS_R_ObjID_4 0 " Valid values " ;
VAL_ 1425 RSDS_R_ObjExistProb_4 0 " Valid values " ;
VAL_ 1425 RSDS_R_ObjObstacleProb_4 0 " Valid values " ;
VAL_ 1425 RSDS_R_ObjDistX_4 0 " Valid values " 4080 " Reserved " ;
VAL_ 1425 RSDS_R_ObjDistY_4 0 " Valid values " ;
VAL_ 1425 RSDS_R_ObjDistXStd_4 0 " Valid values " ;
VAL_ 1425 RSDS_R_ObjType_4 0 " Unknown " 1 " Truck " 2 " Car " 3 " Pedestrian " 4 " Cyclist " 5 " Reserved " ;
VAL_ 1425 RSDS_R_ObjRelVelX_4 0 " Valid values " 8174 " Reserved " ;
VAL_ 1425 RSDS_R_ObjRelVelY_4 0 " Valid values " 8174 " Reserved " ;
VAL_ 1425 RSDS_R_ObjRelAccelX_4 0 " Valid values " ;
VAL_ 1425 RSDS_R_ObjRelAccelY_4 0 " Valid values " ;
VAL_ 1425 RSDS_R_ObjMotionType_4 0 " Int " 1 " Unknown " 2 " Drive " 3 " Stopped " 4 " Stand " 5 " Reserved " 6 " Reserved " 7 " Reserved " ;
VAL_ 1425 RSDS_R_ObjMeasured_4 0 " Init " 1 " Measured " 2 " Predicted " 3 " Reserved " ;
VAL_ 1425 RSDS_R_ObjDistYStd_4 0 " Valid values " ;
VAL_ 1425 RSDS_R_ObjRelVelXStd_4 0 " Valid values " ;
VAL_ 1425 RSDS_R_ObjRelVelYStd_4 0 " Valid values " ;
VAL_ 1425 RSDS_R_ObjRAccelXStd_4 0 " Valid values " ;
VAL_ 1425 RSDS_R_ObjRAccelYStd_4 0 " Valid values " ;
VAL_ 1425 RSDS_R_ObjWidth_4 0 " Valid values " 501 " Reserved " ;
VAL_ 1425 RSDS_R_ObjMotionDirection_4 0 " Init " 1 " Inverse direction " 2 " Same direction " 3 " Cross " 4 " Reserved " 5 " Reserved " 6 " Reserved " 7 " Reserved " ;
VAL_ 1425 RSDS_R_ObjAge_4 0 " Valid_values " ;
VAL_ 1425 RSDS_R_ObjLength_4 0 " Valid values " 401 " Reserved " ;
VAL_ 1425 RSDS_R_ObjHeading_4 0 " Valid values " 4446 " Reserved " ;
VAL_ 1425 RSDS_R_ObjYawrate_4 0 " Valid values " 4446 " Reserved " ;
VAL_ 1425 RSDS_R_ObjRCS_4 0 " Valid_values " ;
VAL_ 1425 RSDS_R_ObjRefPoint_4 0 " Rear " 1 " Rear left " 2 " Left " 3 " Front left " 4 " Front " 5 " Front Right " 6 " Right " 7 " Rear right " ;
VAL_ 1425 RSDS_R_HWATargetValidity_4 0 " NOT HWA Target " 1 " HWA Target " ;
VAL_ 1425 RSDS_R_SGU2_BlockCounter 0 " Valid value " ;
VAL_ 1425 RSDS_R_SGU2_Checksum1 0 " Valid value " ;
VAL_ 1425 RSDS_R_SGU2_Checksum2 0 " Valid value " ;
VAL_ 1425 RSDS_R_SGU2_Checksum3 0 " Valid value " ;
VAL_ 1425 RSDS_R_SGU2_Checksum4 0 " Valid value " ;
VAL_ 1425 RSDS_R_SGU2_Checksum5 0 " Valid value " ;
VAL_ 1425 RSDS_R_SGU2_Checksum6 0 " Valid value " ;
VAL_ 1425 RSDS_R_SGU2_Checksum7 0 " Valid value " ;
VAL_ 1425 RSDS_R_SGU2_Checksum8 0 " Valid value " ;
VAL_ 1425 RSDS_R_SGU2_RollingCounter1 0 " Valid value " 15 " Invalid value " ;
VAL_ 1425 RSDS_R_SGU2_RollingCounter2 0 " Valid value " 15 " Invalid value " ;
VAL_ 1425 RSDS_R_SGU2_RollingCounter3 0 " Valid value " 15 " Invalid value " ;
VAL_ 1425 RSDS_R_SGU2_RollingCounter4 0 " Valid value " 15 " Invalid value " ;
VAL_ 1425 RSDS_R_SGU2_RollingCounter5 0 " Valid value " 15 " Invalid value " ;
VAL_ 1425 RSDS_R_SGU2_RollingCounter6 0 " Valid value " 15 " Invalid value " ;
VAL_ 1425 RSDS_R_SGU2_RollingCounter7 0 " Valid value " 15 " Invalid value " ;
VAL_ 1425 RSDS_R_SGU2_RollingCounter8 0 " Valid value " 15 " Invalid value " ;
VAL_ 1426 RSDS_R_ObjID_5 0 " Valid values " ;
VAL_ 1426 RSDS_R_ObjExistProb_5 0 " Valid values " ;
VAL_ 1426 RSDS_R_ObjObstacleProb_5 0 " Valid values " ;
VAL_ 1426 RSDS_R_ObjDistX_5 0 " Valid values " 4080 " Reserved " ;
VAL_ 1426 RSDS_R_ObjDistY_5 0 " Valid values " ;
VAL_ 1426 RSDS_R_ObjDistXStd_5 0 " Valid values " ;
VAL_ 1426 RSDS_R_ObjType_5 0 " Unknown " 1 " Truck " 2 " Car " 3 " Pedestrian " 4 " Cyclist " 5 " Reserved " ;
VAL_ 1426 RSDS_R_ObjRelVelX_5 0 " Valid values " 8174 " Reserved " ;
VAL_ 1426 RSDS_R_ObjRelVelY_5 0 " Valid values " 8174 " Reserved " ;
VAL_ 1426 RSDS_R_ObjRelAccelX_5 0 " Valid values " ;
VAL_ 1426 RSDS_R_ObjRelAccelY_5 0 " Valid values " ;
VAL_ 1426 RSDS_R_ObjMotionType_5 0 " Int " 1 " Unknown " 2 " Drive " 3 " Stopped " 4 " Stand " 5 " Reserved " 6 " Reserved " 7 " Reserved " ;
VAL_ 1426 RSDS_R_ObjMeasured_5 0 " Init " 1 " Measured " 2 " Predicted " 3 " Reserved " ;
VAL_ 1426 RSDS_R_ObjDistYStd_5 0 " Valid values " ;
VAL_ 1426 RSDS_R_ObjRelVelXStd_5 0 " Valid values " ;
VAL_ 1426 RSDS_R_ObjRelVelYStd_5 0 " Valid values " ;
VAL_ 1426 RSDS_R_ObjRAccelXStd_5 0 " Valid values " ;
VAL_ 1426 RSDS_R_ObjRAccelYStd_5 0 " Valid values " ;
VAL_ 1426 RSDS_R_ObjWidth_5 0 " Valid values " 501 " Reserved " ;
VAL_ 1426 RSDS_R_ObjMotionDirection_5 0 " Init " 1 " Inverse direction " 2 " Same direction " 3 " Cross " 4 " Reserved " 5 " Reserved " 6 " Reserved " 7 " Reserved " ;
VAL_ 1426 RSDS_R_ObjAge_5 0 " Valid_values " ;
VAL_ 1426 RSDS_R_ObjLength_5 0 " Valid values " 401 " Reserved " ;
VAL_ 1426 RSDS_R_ObjHeading_5 0 " Valid values " 4446 " Reserved " ;
VAL_ 1426 RSDS_R_ObjYawrate_5 0 " Valid values " 4446 " Reserved " ;
VAL_ 1426 RSDS_R_ObjRCS_5 0 " Valid_values " ;
VAL_ 1426 RSDS_R_ObjRefPoint_5 0 " Rear " 1 " Rear left " 2 " Left " 3 " Front left " 4 " Front " 5 " Front Right " 6 " Right " 7 " Rear right " ;
VAL_ 1426 RSDS_R_HWATargetValidity_5 0 " NOT HWA Target " 1 " HWA Target " ;
VAL_ 1426 RSDS_R_ObjID_6 0 " Valid values " ;
VAL_ 1426 RSDS_R_ObjExistProb_6 0 " Valid values " ;
VAL_ 1426 RSDS_R_ObjObstacleProb_6 0 " Valid values " ;
VAL_ 1426 RSDS_R_ObjDistX_6 0 " Valid values " 4080 " Reserved " ;
VAL_ 1426 RSDS_R_ObjDistY_6 0 " Valid values " ;
VAL_ 1426 RSDS_R_ObjDistXStd_6 0 " Valid values " ;
VAL_ 1426 RSDS_R_ObjType_6 0 " Unknown " 1 " Truck " 2 " Car " 3 " Pedestrian " 4 " Cyclist " 5 " Reserved " ;
VAL_ 1426 RSDS_R_ObjRelVelX_6 0 " Valid values " 8174 " Reserved " ;
VAL_ 1426 RSDS_R_ObjRelVelY_6 0 " Valid values " 8174 " Reserved " ;
VAL_ 1426 RSDS_R_ObjRelAccelX_6 0 " Valid values " ;
VAL_ 1426 RSDS_R_ObjRelAccelY_6 0 " Valid values " ;
VAL_ 1426 RSDS_R_ObjMotionType_6 0 " Int " 1 " Unknown " 2 " Drive " 3 " Stopped " 4 " Stand " 5 " Reserved " 6 " Reserved " 7 " Reserved " ;
VAL_ 1426 RSDS_R_ObjMeasured_6 0 " Init " 1 " Measured " 2 " Predicted " 3 " Reserved " ;
VAL_ 1426 RSDS_R_ObjDistYStd_6 0 " Valid values " ;
VAL_ 1426 RSDS_R_ObjRelVelXStd_6 0 " Valid values " ;
VAL_ 1426 RSDS_R_ObjRelVelYStd_6 0 " Valid values " ;
VAL_ 1426 RSDS_R_ObjRAccelXStd_6 0 " Valid values " ;
VAL_ 1426 RSDS_R_ObjRAccelYStd_6 0 " Valid values " ;
VAL_ 1426 RSDS_R_ObjWidth_6 0 " Valid values " 501 " Reserved " ;
VAL_ 1426 RSDS_R_ObjMotionDirection_6 0 " Init " 1 " Inverse direction " 2 " Same direction " 3 " Cross " 4 " Reserved " 5 " Reserved " 6 " Reserved " 7 " Reserved " ;
VAL_ 1426 RSDS_R_ObjAge_6 0 " Valid_values " ;
VAL_ 1426 RSDS_R_ObjLength_6 0 " Valid values " 401 " Reserved " ;
VAL_ 1426 RSDS_R_ObjHeading_6 0 " Valid values " 4446 " Reserved " ;
VAL_ 1426 RSDS_R_ObjYawrate_6 0 " Valid values " 4446 " Reserved " ;
VAL_ 1426 RSDS_R_ObjRCS_6 0 " Valid_values " ;
VAL_ 1426 RSDS_R_ObjRefPoint_6 0 " Rear " 1 " Rear left " 2 " Left " 3 " Front left " 4 " Front " 5 " Front Right " 6 " Right " 7 " Rear right " ;
VAL_ 1426 RSDS_R_HWATargetValidity_6 0 " NOT HWA Target " 1 " HWA Target " ;
VAL_ 1426 RSDS_R_SGU3_BlockCounter 0 " Valid value " ;
VAL_ 1426 RSDS_R_SGU3_Checksum1 0 " Valid value " ;
VAL_ 1426 RSDS_R_SGU3_Checksum2 0 " Valid value " ;
VAL_ 1426 RSDS_R_SGU3_Checksum3 0 " Valid value " ;
VAL_ 1426 RSDS_R_SGU3_Checksum4 0 " Valid value " ;
VAL_ 1426 RSDS_R_SGU3_Checksum5 0 " Valid value " ;
VAL_ 1426 RSDS_R_SGU3_Checksum6 0 " Valid value " ;
VAL_ 1426 RSDS_R_SGU3_Checksum7 0 " Valid value " ;
VAL_ 1426 RSDS_R_SGU3_Checksum8 0 " Valid value " ;
VAL_ 1426 RSDS_R_SGU3_RollingCounter1 0 " Valid value " 15 " Invalid value " ;
VAL_ 1426 RSDS_R_SGU3_RollingCounter2 0 " Valid value " 15 " Invalid value " ;
VAL_ 1426 RSDS_R_SGU3_RollingCounter3 0 " Valid value " 15 " Invalid value " ;
VAL_ 1426 RSDS_R_SGU3_RollingCounter4 0 " Valid value " 15 " Invalid value " ;
VAL_ 1426 RSDS_R_SGU3_RollingCounter5 0 " Valid value " 15 " Invalid value " ;
VAL_ 1426 RSDS_R_SGU3_RollingCounter6 0 " Valid value " 15 " Invalid value " ;
VAL_ 1426 RSDS_R_SGU3_RollingCounter7 0 " Valid value " 15 " Invalid value " ;
VAL_ 1426 RSDS_R_SGU3_RollingCounter8 0 " Valid value " 15 " Invalid value " ;
VAL_ 1427 RSDS_R_ObjID_7 0 " Valid values " ;
VAL_ 1427 RSDS_R_ObjExistProb_7 0 " Valid values " ;
VAL_ 1427 RSDS_R_ObjObstacleProb_7 0 " Valid values " ;
VAL_ 1427 RSDS_R_ObjDistX_7 0 " Valid values " 4080 " Reserved " ;
VAL_ 1427 RSDS_R_ObjDistY_7 0 " Valid values " ;
VAL_ 1427 RSDS_R_ObjDistXStd_7 0 " Valid values " ;
VAL_ 1427 RSDS_R_ObjType_7 0 " Unknown " 1 " Truck " 2 " Car " 3 " Pedestrian " 4 " Cyclist " 5 " Reserved " ;
VAL_ 1427 RSDS_R_ObjRelVelX_7 0 " Valid values " 8174 " Reserved " ;
VAL_ 1427 RSDS_R_ObjRelVelY_7 0 " Valid values " 8174 " Reserved " ;
VAL_ 1427 RSDS_R_ObjRelAccelX_7 0 " Valid values " ;
VAL_ 1427 RSDS_R_ObjRelAccelY_7 0 " Valid values " ;
VAL_ 1427 RSDS_R_ObjMotionType_7 0 " Int " 1 " Unknown " 2 " Drive " 3 " Stopped " 4 " Stand " 5 " Reserved " 6 " Reserved " 7 " Reserved " ;
VAL_ 1427 RSDS_R_ObjMeasured_7 0 " Init " 1 " Measured " 2 " Predicted " 3 " Reserved " ;
VAL_ 1427 RSDS_R_ObjDistYStd_7 0 " Valid values " ;
VAL_ 1427 RSDS_R_ObjRelVelXStd_7 0 " Valid values " ;
VAL_ 1427 RSDS_R_ObjRelVelYStd_7 0 " Valid values " ;
VAL_ 1427 RSDS_R_ObjRAccelXStd_7 0 " Valid values " ;
VAL_ 1427 RSDS_R_ObjRAccelYStd_7 0 " Valid values " ;
VAL_ 1427 RSDS_R_ObjWidth_7 0 " Valid values " 501 " Reserved " ;
VAL_ 1427 RSDS_R_ObjMotionDirection_7 0 " Init " 1 " Inverse direction " 2 " Same direction " 3 " Cross " 4 " Reserved " 5 " Reserved " 6 " Reserved " 7 " Reserved " ;
VAL_ 1427 RSDS_R_ObjAge_7 0 " Valid_values " ;
VAL_ 1427 RSDS_R_ObjLength_7 0 " Valid values " 401 " Reserved " ;
VAL_ 1427 RSDS_R_ObjHeading_7 0 " Valid values " 4446 " Reserved " ;
VAL_ 1427 RSDS_R_ObjYawrate_7 0 " Valid values " 4446 " Reserved " ;
VAL_ 1427 RSDS_R_ObjRCS_7 0 " Valid_values " ;
VAL_ 1427 RSDS_R_ObjRefPoint_7 0 " Rear " 1 " Rear left " 2 " Left " 3 " Front left " 4 " Front " 5 " Front Right " 6 " Right " 7 " Rear right " ;
VAL_ 1427 RSDS_R_HWATargetValidity_7 0 " NOT HWA Target " 1 " HWA Target " ;
VAL_ 1427 RSDS_R_ObjID_8 0 " Valid values " ;
VAL_ 1427 RSDS_R_ObjExistProb_8 0 " Valid values " ;
VAL_ 1427 RSDS_R_ObjObstacleProb_8 0 " Valid values " ;
VAL_ 1427 RSDS_R_ObjDistX_8 0 " Valid values " 4080 " Reserved " ;
VAL_ 1427 RSDS_R_ObjDistY_8 0 " Valid values " ;
VAL_ 1427 RSDS_R_ObjDistXStd_8 0 " Valid values " ;
VAL_ 1427 RSDS_R_ObjType_8 0 " Unknown " 1 " Truck " 2 " Car " 3 " Pedestrian " 4 " Cyclist " 5 " Reserved " ;
VAL_ 1427 RSDS_R_ObjRelVelX_8 0 " Valid values " 8174 " Reserved " ;
VAL_ 1427 RSDS_R_ObjRelVelY_8 0 " Valid values " 8174 " Reserved " ;
VAL_ 1427 RSDS_R_ObjRelAccelX_8 0 " Valid values " ;
VAL_ 1427 RSDS_R_ObjRelAccelY_8 0 " Valid values " ;
VAL_ 1427 RSDS_R_ObjMotionType_8 0 " Int " 1 " Unknown " 2 " Drive " 3 " Stopped " 4 " Stand " 5 " Reserved " 6 " Reserved " 7 " Reserved " ;
VAL_ 1427 RSDS_R_ObjMeasured_8 0 " Init " 1 " Measured " 2 " Predicted " 3 " Reserved " ;
VAL_ 1427 RSDS_R_ObjDistYStd_8 0 " Valid values " ;
VAL_ 1427 RSDS_R_ObjRelVelXStd_8 0 " Valid values " ;
VAL_ 1427 RSDS_R_ObjRelVelYStd_8 0 " Valid values " ;
VAL_ 1427 RSDS_R_ObjRAccelXStd_8 0 " Valid values " ;
VAL_ 1427 RSDS_R_ObjRAccelYStd_8 0 " Valid values " ;
VAL_ 1427 RSDS_R_ObjWidth_8 0 " Valid values " 501 " Reserved " ;
VAL_ 1427 RSDS_R_ObjMotionDirection_8 0 " Init " 1 " Inverse direction " 2 " Same direction " 3 " Cross " 4 " Reserved " 5 " Reserved " 6 " Reserved " 7 " Reserved " ;
VAL_ 1427 RSDS_R_ObjAge_8 0 " Valid_values " ;
VAL_ 1427 RSDS_R_ObjLength_8 0 " Valid values " 401 " Reserved " ;
VAL_ 1427 RSDS_R_ObjHeading_8 0 " Valid values " 4446 " Reserved " ;
VAL_ 1427 RSDS_R_ObjYawrate_8 0 " Valid values " 4446 " Reserved " ;
VAL_ 1427 RSDS_R_ObjRCS_8 0 " Valid_values " ;
VAL_ 1427 RSDS_R_ObjRefPoint_8 0 " Rear " 1 " Rear left " 2 " Left " 3 " Front left " 4 " Front " 5 " Front Right " 6 " Right " 7 " Rear right " ;
VAL_ 1427 RSDS_R_HWATargetValidity_8 0 " NOT HWA Target " 1 " HWA Target " ;
VAL_ 1427 RSDS_R_SGU4_BlockCounter 0 " Valid value " ;
VAL_ 1427 RSDS_R_SGU4_Checksum1 0 " Valid value " ;
VAL_ 1427 RSDS_R_SGU4_Checksum2 0 " Valid value " ;
VAL_ 1427 RSDS_R_SGU4_Checksum3 0 " Valid value " ;
VAL_ 1427 RSDS_R_SGU4_Checksum4 0 " Valid value " ;
VAL_ 1427 RSDS_R_SGU4_Checksum5 0 " Valid value " ;
VAL_ 1427 RSDS_R_SGU4_Checksum6 0 " Valid value " ;
VAL_ 1427 RSDS_R_SGU4_Checksum7 0 " Valid value " ;
VAL_ 1427 RSDS_R_SGU4_Checksum8 0 " Valid value " ;
VAL_ 1427 RSDS_R_SGU4_RollingCounter1 0 " Valid value " 15 " Invalid value " ;
VAL_ 1427 RSDS_R_SGU4_RollingCounter2 0 " Valid value " 15 " Invalid value " ;
VAL_ 1427 RSDS_R_SGU4_RollingCounter3 0 " Valid value " 15 " Invalid value " ;
VAL_ 1427 RSDS_R_SGU4_RollingCounter4 0 " Valid value " 15 " Invalid value " ;
VAL_ 1427 RSDS_R_SGU4_RollingCounter5 0 " Valid value " 15 " Invalid value " ;
VAL_ 1427 RSDS_R_SGU4_RollingCounter6 0 " Valid value " 15 " Invalid value " ;
VAL_ 1427 RSDS_R_SGU4_RollingCounter7 0 " Valid value " 15 " Invalid value " ;
VAL_ 1427 RSDS_R_SGU4_RollingCounter8 0 " Valid value " 15 " Invalid value " ;
VAL_ 629 Checksum_Trailer2 0 " Valid_value " ;
VAL_ 629 TrailerStatusVld 0 " InValid " 1 " Valid " ;
VAL_ 629 TrailerStatus 0 " Trailer_off " 1 " Trailer_on " ;
VAL_ 629 RollingCounter_Trailer2 0 " Valid_value " 15 " Invalid_value " ;
